VERSION ""

NS_ :

BS_:

BU_: RLPSU DPSU APSU PSB SHVU_RR vHS_B2 FCS EMCU SLB RCM CGW_CCU vDummy_HS_B ATS RLHV PFSU SGU ALBCU DSAU SWRC SHVU_FR RCS RRPSU BLTN_CAM SCM DLBCU OHCL RWPC RRHV WPC HOD ASAU

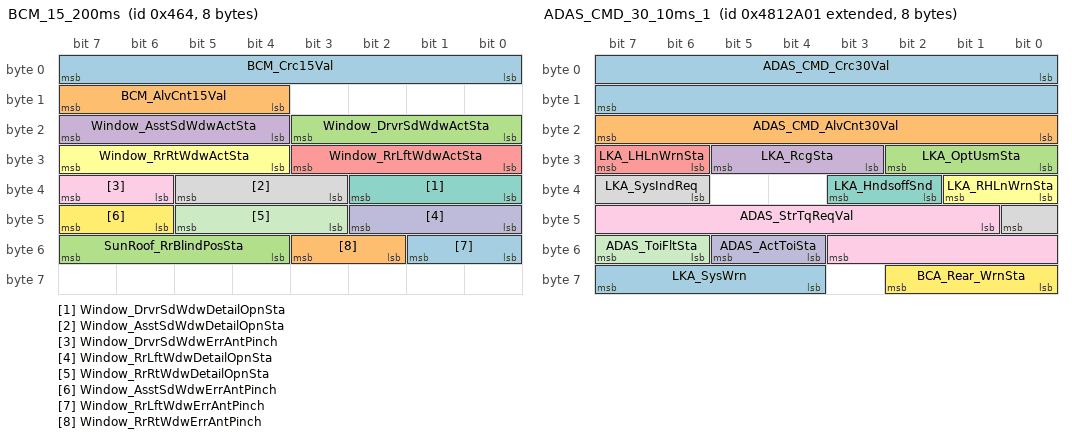
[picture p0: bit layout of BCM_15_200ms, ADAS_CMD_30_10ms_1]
BO_ 1124 BCM_15_200ms: 8 CGW_CCU
 SG_ BCM_Crc15Val : 0|8@1+ (1,0) [0|0] ""  Vector__XXX
 SG_ BCM_AlvCnt15Val : 12|4@1+ (1,0) [0|0] ""  Vector__XXX
 SG_ Window_DrvrSdWdwActSta : 16|4@1+ (1,0) [0|0] ""  Vector__XXX
 SG_ Window_AsstSdWdwActSta : 20|4@1+ (1,0) [0|0] ""  Vector__XXX
 SG_ Window_RrLftWdwActSta : 24|4@1+ (1,0) [0|0] ""  Vector__XXX
 SG_ Window_RrRtWdwActSta : 28|4@1+ (1,0) [0|0] ""  Vector__XXX
 SG_ Window_DrvrSdWdwDetailOpnSta : 32|3@1+ (1,0) [0|0] ""  Vector__XXX
 SG_ Window_AsstSdWdwDetailOpnSta : 35|3@1+ (1,0) [0|0] ""  Vector__XXX
 SG_ Window_DrvrSdWdwErrAntPinch : 38|2@1+ (1,0) [0|0] ""  Vector__XXX
 SG_ Window_RrLftWdwDetailOpnSta : 40|3@1+ (1,0) [0|0] ""  Vector__XXX
 SG_ Window_RrRtWdwDetailOpnSta : 43|3@1+ (1,0) [0|0] ""  Vector__XXX
 SG_ Window_AsstSdWdwErrAntPinch : 46|2@1+ (1,0) [0|0] ""  Vector__XXX
 SG_ Window_RrLftWdwErrAntPinch : 48|2@1+ (1,0) [0|0] ""  Vector__XXX
 SG_ Window_RrRtWdwErrAntPinch : 50|2@1+ (1,0) [0|0] ""  Vector__XXX
 SG_ SunRoof_RrBlindPosSta : 52|4@1+ (1,0) [0|0] ""  ATS

BO_ 2223057409 ADAS_CMD_30_10ms_1: 8 CGW_CCU
 SG_ ADAS_CMD_Crc30Val : 0|16@1+ (1,0) [0|0] ""  Vector__XXX
 SG_ ADAS_CMD_AlvCnt30Val : 16|8@1+ (1,0) [0|0] ""  Vector__XXX
 SG_ LKA_OptUsmSta : 24|3@1+ (1,0) [0|0] ""  Vector__XXX
 SG_ LKA_RcgSta : 27|3@1+ (1,0) [0|0] ""  Vector__XXX
 SG_ LKA_LHLnWrnSta : 30|2@1+ (1,0) [0|0] ""  Vector__XXX
 SG_ LKA_RHLnWrnSta : 32|2@1+ (1,0) [0|0] ""  Vector__XXX
 SG_ LKA_HndsoffSnd : 34|2@1+ (1,0) [0|0] ""  Vector__XXX
 SG_ LKA_SysIndReq : 38|3@1+ (1,0) [0|0] ""  Vector__XXX
 SG_ ADAS_StrTqReqVal : 41|11@1+ (0.0078125,-8) [0|0] "Nm"  Vector__XXX
 SG_ ADAS_ActToiSta : 52|2@1+ (1,0) [0|0] ""  Vector__XXX
 SG_ ADAS_ToiFltSta : 54|2@1+ (1,0) [0|0] ""  Vector__XXX
 SG_ BCA_Rear_WrnSta : 56|3@1+ (1,0) [0|0] ""  Vector__XXX
 SG_ LKA_SysWrn : 60|4@1+ (1,0) [0|0] ""  Vector__XXX

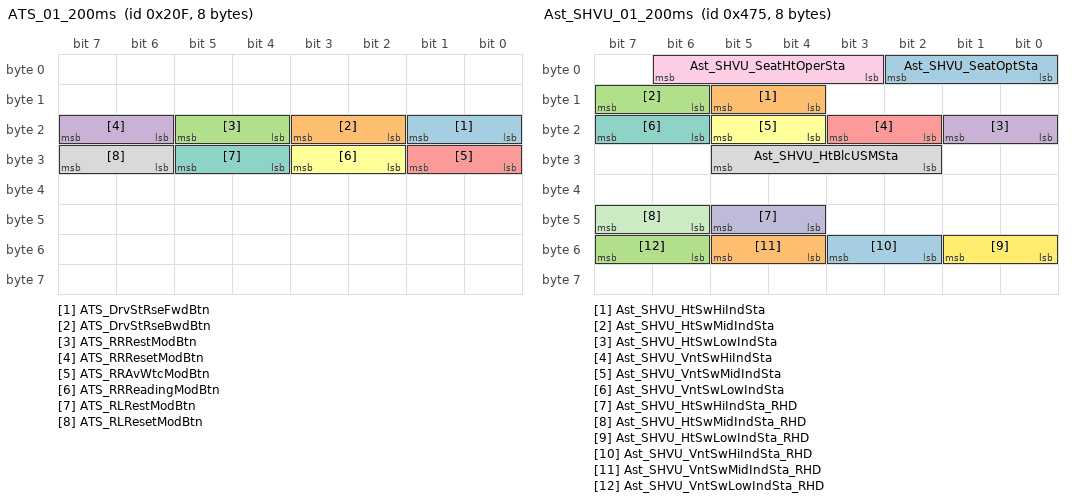
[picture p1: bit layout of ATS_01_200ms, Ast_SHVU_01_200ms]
BO_ 527 ATS_01_200ms: 8 ATS
 SG_ ATS_DrvStRseFwdBtn : 16|2@1+ (1,0) [0|0] ""  Vector__XXX
 SG_ ATS_DrvStRseBwdBtn : 18|2@1+ (1,0) [0|0] ""  Vector__XXX
 SG_ ATS_RRRestModBtn : 20|2@1+ (1,0) [0|0] ""  Vector__XXX
 SG_ ATS_RRResetModBtn : 22|2@1+ (1,0) [0|0] ""  Vector__XXX
 SG_ ATS_RRAvWtcModBtn : 24|2@1+ (1,0) [0|0] ""  Vector__XXX
 SG_ ATS_RRReadingModBtn : 26|2@1+ (1,0) [0|0] ""  Vector__XXX
 SG_ ATS_RLRestModBtn : 28|2@1+ (1,0) [0|0] ""  Vector__XXX
 SG_ ATS_RLResetModBtn : 30|2@1+ (1,0) [0|0] ""  Vector__XXX

BO_ 1616 MKBD_HU_E_01: 8 CGW_CCU
 SG_ MKBD_IllumiState : 48|2@1+ (1,0) [0|0] ""  Vector__XXX
 SG_ MKBD_SeatKeySet : 50|2@1+ (1,0) [0|0] ""  APSU,SHVU_FR,DPSU

BO_ 1141 Ast_SHVU_01_200ms: 8 APSU
 SG_ Ast_SHVU_SeatOptSta : 0|3@1+ (1,0) [0|0] ""  FCS,CGW_CCU
 SG_ Ast_SHVU_HtSwHiIndSta : 12|2@1+ (1,0) [0|0] ""  FCS,CGW_CCU
 SG_ Ast_SHVU_HtSwMidIndSta : 14|2@1+ (1,0) [0|0] ""  FCS,CGW_CCU
 SG_ Ast_SHVU_HtSwLowIndSta : 16|2@1+ (1,0) [0|0] ""  FCS,CGW_CCU
 SG_ Ast_SHVU_VntSwHiIndSta : 18|2@1+ (1,0) [0|0] ""  FCS,CGW_CCU
 SG_ Ast_SHVU_VntSwMidIndSta : 20|2@1+ (1,0) [0|0] ""  FCS,CGW_CCU
 SG_ Ast_SHVU_VntSwLowIndSta : 22|2@1+ (1,0) [0|0] ""  FCS,CGW_CCU
 SG_ Ast_SHVU_HtBlcUSMSta : 26|4@1+ (1,0) [0|0] ""  CGW_CCU
 SG_ Ast_SHVU_SeatHtOperSta : 3|4@1+ (1,0) [0|0] ""  CGW_CCU
 SG_ Ast_SHVU_HtSwHiIndSta_RHD : 44|2@1+ (1,0) [0|0] ""  FCS,CGW_CCU
 SG_ Ast_SHVU_HtSwMidIndSta_RHD : 46|2@1+ (1,0) [0|0] ""  FCS,CGW_CCU
 SG_ Ast_SHVU_HtSwLowIndSta_RHD : 48|2@1+ (1,0) [0|0] ""  FCS,CGW_CCU
 SG_ Ast_SHVU_VntSwHiIndSta_RHD : 50|2@1+ (1,0) [0|0] ""  FCS,CGW_CCU
 SG_ Ast_SHVU_VntSwMidIndSta_RHD : 52|2@1+ (1,0) [0|0] ""  FCS,CGW_CCU
 SG_ Ast_SHVU_VntSwLowIndSta_RHD : 54|2@1+ (1,0) [0|0] ""  FCS,CGW_CCU

BO_ 543 ATS_02_200ms: 8 ATS
 SG_ ATS_AstStSldFwdBtn : 16|2@1+ (1,0) [0|0] ""  Vector__XXX
 SG_ ATS_AstStSldBwdBtn : 18|2@1+ (1,0) [0|0] ""  Vector__XXX
 SG_ ATS_AstStRclFwdBtn : 20|2@1+ (1,0) [0|0] ""  Vector__XXX
 SG_ ATS_AstStRclBwdBtn : 22|2@1+ (1,0) [0|0] ""  Vector__XXX
 SG_ ATS_AstStHgtUpBtn : 28|2@1+ (1,0) [0|0] ""  Vector__XXX
 SG_ ATS_AstStHgtDnBtn : 30|2@1+ (1,0) [0|0] ""  Vector__XXX
 SG_ ATS_AstStHRestUpBtn : 40|2@1+ (1,0) [0|0] ""  Vector__XXX
 SG_ ATS_AstStHRestDnBtn : 42|2@1+ (1,0) [0|0] ""  Vector__XXX
 SG_ ATS_AstStHRestFwdBtn : 44|2@1+ (1,0) [0|0] ""  Vector__XXX
 SG_ ATS_AstStHRestBwdBtn : 46|2@1+ (1,0) [0|0] ""  Vector__XXX
 SG_ ATS_AstStHRestFldBtn : 48|2@1+ (1,0) [0|0] ""  Vector__XXX
 SG_ ATS_AstStHRestUnFldBtn : 50|2@1+ (1,0) [0|0] ""  Vector__XXX
 SG_ ATS_AstStRseFwdBtn : 52|2@1+ (1,0) [0|0] ""  Vector__XXX
 SG_ ATS_AstStRseBwdBtn : 54|2@1+ (1,0) [0|0] ""  Vector__XXX
 SG_ ATS_AstStFRestFldBtn : 56|2@1+ (1,0) [0|0] ""  Vector__XXX
 SG_ ATS_AstStFRestUnFldBtn : 58|2@1+ (1,0) [0|0] ""  Vector__XXX
 SG_ ATS_AstTltUpBtn : 60|2@1+ (1,0) [0|0] ""  Vector__XXX
 SG_ ATS_AstTltDnBtn : 62|2@1+ (1,0) [0|0] ""  Vector__XXX

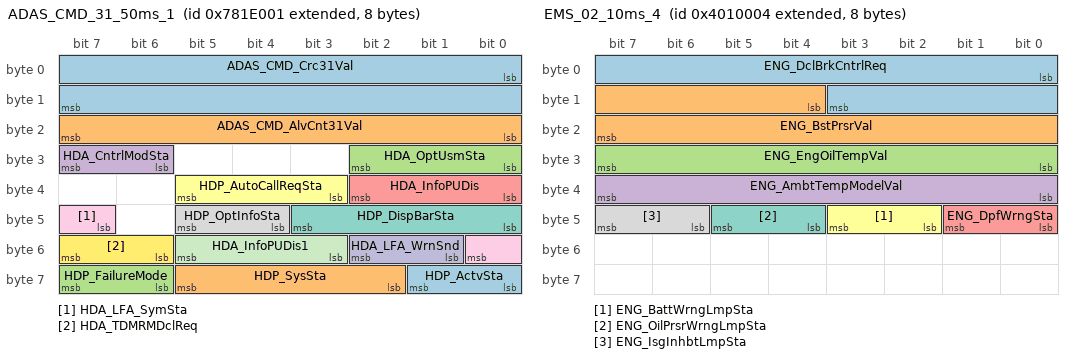
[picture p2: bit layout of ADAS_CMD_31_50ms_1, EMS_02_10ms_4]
BO_ 2273435649 ADAS_CMD_31_50ms_1: 8 CGW_CCU
 SG_ ADAS_CMD_Crc31Val : 0|16@1+ (1,0) [0|0] ""  Vector__XXX
 SG_ ADAS_CMD_AlvCnt31Val : 16|8@1+ (1,0) [0|0] ""  Vector__XXX
 SG_ HDA_OptUsmSta : 24|3@1+ (1,0) [0|0] ""  Vector__XXX
 SG_ HDA_CntrlModSta : 30|2@1+ (1,0) [0|0] ""  Vector__XXX
 SG_ HDA_InfoPUDis : 32|3@1+ (1,0) [0|0] ""  Vector__XXX
 SG_ HDP_AutoCallReqSta : 35|3@1+ (1,0) [0|0] ""  Vector__XXX
 SG_ HDP_DispBarSta : 40|4@1+ (1,0) [0|0] ""  Vector__XXX
 SG_ HDP_OptInfoSta : 44|2@1+ (1,0) [0|0] ""  Vector__XXX
 SG_ HDA_LFA_SymSta : 47|2@1+ (1,0) [0|0] ""  Vector__XXX
 SG_ HDA_LFA_WrnSnd : 49|2@1+ (1,0) [0|0] ""  Vector__XXX
 SG_ HDA_InfoPUDis1 : 51|3@1+ (1,0) [0|0] ""  Vector__XXX
 SG_ HDA_TDMRMDclReq : 54|2@1+ (1,0) [0|0] ""  Vector__XXX
 SG_ HDP_ActvSta : 56|2@1+ (1,0) [0|0] ""  Vector__XXX
 SG_ HDP_SysSta : 58|4@1+ (1,0) [0|0] ""  HOD
 SG_ HDP_FailureMode : 62|2@1+ (1,0) [0|0] ""  Vector__XXX

BO_ 2214658052 EMS_02_10ms_4: 8 CGW_CCU
 SG_ ENG_DclBrkCntrlReq : 0|12@1+ (0.001,-4.094) [0|0] "m/s^2"  Vector__XXX
 SG_ ENG_BstPrsrVal : 12|12@1+ (1.322,0) [0|0] "hPa"  Vector__XXX
 SG_ ENG_EngOilTempVal : 24|8@1+ (0.75,-40) [0|0] "¡É"  Vector__XXX
 SG_ ENG_AmbtTempModelVal : 32|8@1+ (0.5,-41) [0|0] "¡É"  Vector__XXX
 SG_ ENG_DpfWrngSta : 40|2@1+ (1,0) [0|0] ""  Vector__XXX
 SG_ ENG_BattWrngLmpSta : 42|2@1+ (1,0) [0|0] ""  Vector__XXX
 SG_ ENG_OilPrsrWrngLmpSta : 44|2@1+ (1,0) [0|0] ""  Vector__XXX
 SG_ ENG_IsgInhbtLmpSta : 46|2@1+ (1,0) [0|0] ""  FCS

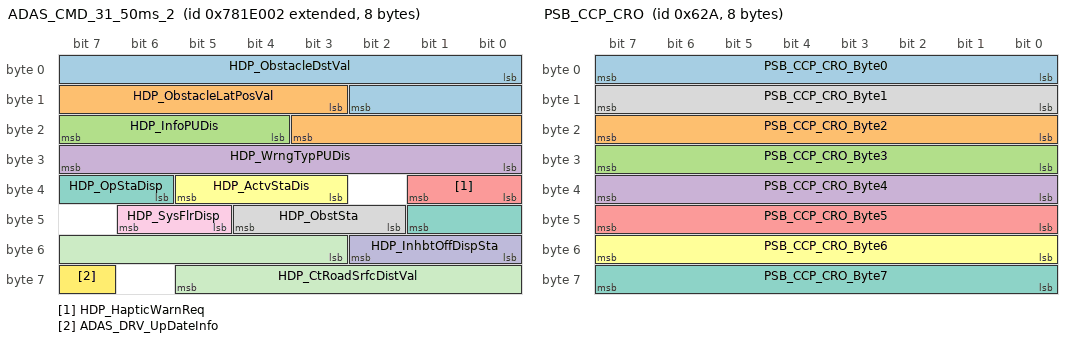
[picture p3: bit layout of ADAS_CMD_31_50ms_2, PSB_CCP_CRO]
BO_ 2273435650 ADAS_CMD_31_50ms_2: 8 CGW_CCU
 SG_ HDP_ObstacleDstVal : 0|11@1+ (0.1,0) [0|0] "m"  Vector__XXX
 SG_ HDP_ObstacleLatPosVal : 11|9@1+ (0.1,-20) [0|0] "m"  Vector__XXX
 SG_ HDP_InfoPUDis : 20|4@1+ (1,0) [0|0] ""  Vector__XXX
 SG_ HDP_WrngTypPUDis : 24|8@1+ (1,0) [0|0] ""  Vector__XXX
 SG_ HDP_HapticWarnReq : 32|2@1+ (1,0) [0|0] ""  PSB
 SG_ HDP_ActvStaDis : 35|3@1+ (1,0) [0|0] ""  Vector__XXX
 SG_ HDP_OpStaDisp : 38|4@1+ (1,0) [0|0] ""  Vector__XXX
 SG_ HDP_ObstSta : 42|3@1+ (1,0) [0|0] ""  Vector__XXX
 SG_ HDP_SysFlrDisp : 45|2@1+ (1,0) [0|0] ""  Vector__XXX
 SG_ HDP_InhbtOffDispSta : 48|3@1+ (1,0) [0|0] ""  Vector__XXX
 SG_ HDP_CtRoadSrfcDistVal : 51|11@1+ (1,0) [0|0] ""  Vector__XXX
 SG_ ADAS_DRV_UpDateInfo : 63|1@1+ (1,0) [0|0] ""  Vector__XXX

BO_ 1578 PSB_CCP_CRO: 8 CGW_CCU
 SG_ PSB_CCP_CRO_Byte0 : 0|8@1+ (1,0) [0|0] ""  PSB
 SG_ PSB_CCP_CRO_Byte2 : 16|8@1+ (1,0) [0|0] ""  PSB
 SG_ PSB_CCP_CRO_Byte3 : 24|8@1+ (1,0) [0|0] ""  PSB
 SG_ PSB_CCP_CRO_Byte4 : 32|8@1+ (1,0) [0|0] ""  PSB
 SG_ PSB_CCP_CRO_Byte5 : 40|8@1+ (1,0) [0|0] ""  PSB
 SG_ PSB_CCP_CRO_Byte6 : 48|8@1+ (1,0) [0|0] ""  PSB
 SG_ PSB_CCP_CRO_Byte7 : 56|8@1+ (1,0) [0|0] ""  PSB
 SG_ PSB_CCP_CRO_Byte1 : 8|8@1+ (1,0) [0|0] ""  PSB

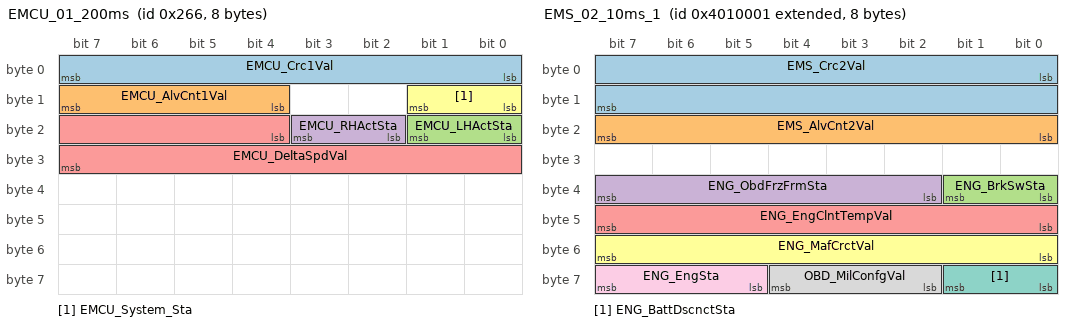
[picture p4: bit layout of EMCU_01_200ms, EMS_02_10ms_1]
BO_ 614 EMCU_01_200ms: 8 EMCU
 SG_ EMCU_Crc1Val : 0|8@1+ (1,0) [0|0] ""  Vector__XXX
 SG_ EMCU_AlvCnt1Val : 12|4@1+ (1,0) [0|0] ""  Vector__XXX
 SG_ EMCU_LHActSta : 16|2@1+ (1,0) [0|0] ""  Vector__XXX
 SG_ EMCU_RHActSta : 18|2@1+ (1,0) [0|0] ""  Vector__XXX
 SG_ EMCU_DeltaSpdVal : 20|12@1+ (0.01,0) [0|0] ""  Vector__XXX
 SG_ EMCU_System_Sta : 8|2@1+ (1,0) [0|0] ""  Vector__XXX

BO_ 2214658049 EMS_02_10ms_1: 8 CGW_CCU
 SG_ EMS_Crc2Val : 0|16@1+ (1,0) [0|0] ""  Vector__XXX
 SG_ EMS_AlvCnt2Val : 16|8@1+ (1,0) [0|0] ""  Vector__XXX
 SG_ ENG_BrkSwSta : 32|2@1+ (1,0) [0|0] ""  BLTN_CAM
 SG_ ENG_ObdFrzFrmSta : 34|6@1+ (1,0) [0|0] ""  Vector__XXX
 SG_ ENG_EngClntTempVal : 40|8@1+ (0.75,-48) [0|0] "¡É"  Vector__XXX
 SG_ ENG_MafCrctVal : 48|8@1+ (0.00781,0) [0|0] ""  Vector__XXX
 SG_ ENG_BattDscnctSta : 56|2@1+ (1,0) [0|0] ""  Vector__XXX
 SG_ OBD_MilConfgVal : 58|3@1+ (1,0) [0|0] ""  Vector__XXX
 SG_ ENG_EngSta : 61|3@1+ (1,0) [0|0] ""  SCM,WPC,RWPC,SWRC,APSU,SHVU_FR,DPSU,PFSU,RRPSU,RLPSU,HOD,BLTN_CAM,EMCU

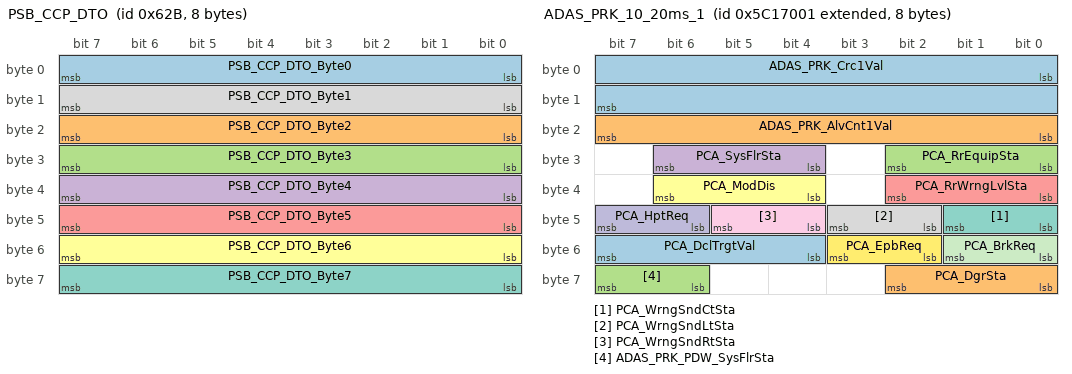
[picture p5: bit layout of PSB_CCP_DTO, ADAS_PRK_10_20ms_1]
BO_ 1579 PSB_CCP_DTO: 8 PSB
 SG_ PSB_CCP_DTO_Byte0 : 0|8@1+ (1,0) [0|0] ""  CGW_CCU
 SG_ PSB_CCP_DTO_Byte2 : 16|8@1+ (1,0) [0|0] ""  CGW_CCU
 SG_ PSB_CCP_DTO_Byte3 : 24|8@1+ (1,0) [0|0] ""  CGW_CCU
 SG_ PSB_CCP_DTO_Byte4 : 32|8@1+ (1,0) [0|0] ""  CGW_CCU
 SG_ PSB_CCP_DTO_Byte5 : 40|8@1+ (1,0) [0|0] ""  CGW_CCU
 SG_ PSB_CCP_DTO_Byte6 : 48|8@1+ (1,0) [0|0] ""  CGW_CCU
 SG_ PSB_CCP_DTO_Byte7 : 56|8@1+ (1,0) [0|0] ""  CGW_CCU
 SG_ PSB_CCP_DTO_Byte1 : 8|8@1+ (1,0) [0|0] ""  CGW_CCU

BO_ 2244046850 ADAS_PRK_10_20ms_2: 8 CGW_CCU
 SG_ ADAS_PRK_PDW_SwIndOnReq : 0|2@1+ (1,0) [0|0] ""  FCS
 SG_ PCA_RrEquipChkSta : 10|2@1+ (1,0) [0|0] ""  Vector__XXX
 SG_ PCA_FrWrngLvlSta : 12|3@1+ (1,0) [0|0] ""  Vector__XXX
 SG_ PCA_LtWrngLvlSta : 16|3@1+ (1,0) [0|0] ""  Vector__XXX
 SG_ ADAS_PRK_PDW_OptTyp : 2|3@1+ (1,0) [0|0] ""  Vector__XXX
 SG_ PCA_RtWrngLvlSta : 20|3@1+ (1,0) [0|0] ""  Vector__XXX
 SG_ PCA_RrFlrDis : 32|2@1+ (1,0) [0|0] ""  Vector__XXX
 SG_ PCA_FrFlrDis : 34|2@1+ (1,0) [0|0] ""  Vector__XXX
 SG_ PCA_LtFlrDis : 36|2@1+ (1,0) [0|0] ""  Vector__XXX
 SG_ PCA_RtFlrDis : 38|2@1+ (1,0) [0|0] ""  Vector__XXX
 SG_ PCA_FrBndryLn : 40|2@1+ (1,0) [0|0] ""  Vector__XXX
 SG_ PCA_RrBndryLn : 42|2@1+ (1,0) [0|0] ""  Vector__XXX
 SG_ PCA_LtBndryLn : 44|2@1+ (1,0) [0|0] ""  Vector__XXX
 SG_ PCA_RtBndryLn : 46|2@1+ (1,0) [0|0] ""  Vector__XXX
 SG_ PCA_WrngPhrs : 48|3@1+ (1,0) [0|0] ""  Vector__XXX
 SG_ ADAS_PRK_PDW_AutoOn_USM : 5|2@1+ (1,0) [0|0] ""  Vector__XXX
 SG_ PCA_FrSdEquipChkSta : 8|2@1+ (1,0) [0|0] ""  Vector__XXX

BO_ 2244046849 ADAS_PRK_10_20ms_1: 8 CGW_CCU
 SG_ ADAS_PRK_Crc1Val : 0|16@1+ (1,0) [0|0] ""  Vector__XXX
 SG_ ADAS_PRK_AlvCnt1Val : 16|8@1+ (1,0) [0|0] ""  Vector__XXX
 SG_ PCA_RrEquipSta : 24|3@1+ (1,0) [0|0] ""  Vector__XXX
 SG_ PCA_SysFlrSta : 28|3@1+ (1,0) [0|0] ""  Vector__XXX
 SG_ PCA_RrWrngLvlSta : 32|3@1+ (1,0) [0|0] ""  Vector__XXX
 SG_ PCA_ModDis : 36|3@1+ (1,0) [0|0] ""  Vector__XXX
 SG_ PCA_WrngSndCtSta : 40|2@1+ (1,0) [0|0] ""  Vector__XXX
 SG_ PCA_WrngSndLtSta : 42|2@1+ (1,0) [0|0] ""  Vector__XXX
 SG_ PCA_WrngSndRtSta : 44|2@1+ (1,0) [0|0] ""  Vector__XXX
 SG_ PCA_HptReq : 46|2@1+ (1,0) [0|0] ""  Vector__XXX
 SG_ PCA_BrkReq : 48|2@1+ (1,0) [0|0] ""  Vector__XXX
 SG_ PCA_EpbReq : 50|2@1+ (1,0) [0|0] ""  Vector__XXX
 SG_ PCA_DclTrgtVal : 52|4@1+ (0.04,0) [0|0] "g"  Vector__XXX
 SG_ PCA_DgrSta : 56|3@1+ (1,0) [0|0] ""  Vector__XXX
 SG_ ADAS_PRK_PDW_SysFlrSta : 62|2@1+ (1,0) [0|0] ""  Vector__XXX

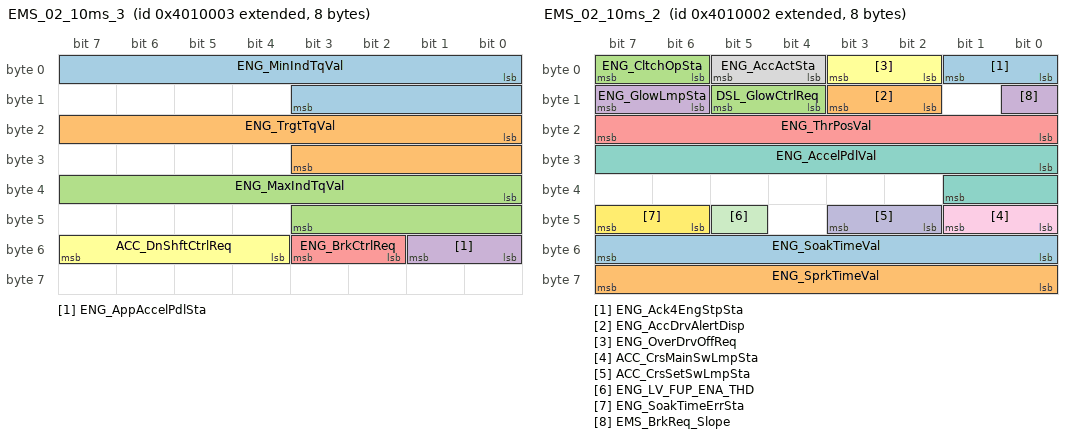
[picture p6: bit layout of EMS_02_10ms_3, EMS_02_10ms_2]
BO_ 2214658051 EMS_02_10ms_3: 8 CGW_CCU
 SG_ ENG_MinIndTqVal : 0|12@1- (1,0) [0|0] "Nm"  Vector__XXX
 SG_ ENG_TrgtTqVal : 16|12@1- (1,0) [0|0] "Nm"  Vector__XXX
 SG_ ENG_MaxIndTqVal : 32|12@1- (1,0) [0|0] "Nm"  Vector__XXX
 SG_ ENG_AppAccelPdlSta : 48|2@1+ (1,0) [0|0] ""  Vector__XXX
 SG_ ENG_BrkCtrlReq : 50|2@1+ (1,0) [0|0] ""  Vector__XXX
 SG_ ACC_DnShftCtrlReq : 52|4@1+ (1,0) [0|0] ""  Vector__XXX

BO_ 2214658050 EMS_02_10ms_2: 8 CGW_CCU
 SG_ ENG_Ack4EngStpSta : 0|2@1+ (1,0) [0|0] ""  Vector__XXX
 SG_ ENG_AccDrvAlertDisp : 10|2@1+ (1,0) [0|0] ""  Vector__XXX
 SG_ DSL_GlowCtrlReq : 12|2@1+ (1,0) [0|0] ""  Vector__XXX
 SG_ ENG_GlowLmpSta : 14|2@1+ (1,0) [0|0] ""  Vector__XXX
 SG_ ENG_ThrPosVal : 16|8@1+ (0.4694836,-15.0234742) [0|0] "%"  Vector__XXX
 SG_ ENG_OverDrvOffReq : 2|2@1+ (1,0) [0|0] ""  Vector__XXX
 SG_ ENG_AccelPdlVal : 24|10@1+ (0.09784,0) [0|0] "%"  BLTN_CAM,EMCU
 SG_ ENG_AccActSta : 4|2@1+ (1,0) [0|0] ""  Vector__XXX
 SG_ ACC_CrsMainSwLmpSta : 40|2@1+ (1,0) [0|0] ""  Vector__XXX
 SG_ ACC_CrsSetSwLmpSta : 42|2@1+ (1,0) [0|0] ""  Vector__XXX
 SG_ ENG_LV_FUP_ENA_THD : 45|1@1+ (1,0) [0|0] ""  Vector__XXX
 SG_ ENG_SoakTimeErrSta : 46|2@1+ (1,0) [0|0] ""  Vector__XXX
 SG_ ENG_SoakTimeVal : 48|8@1+ (1,0) [0|0] "Min"  Vector__XXX
 SG_ ENG_SprkTimeVal : 56|8@1+ (0.375,-35.625) [0|0] "¢ª"  Vector__XXX
 SG_ ENG_CltchOpSta : 6|2@1+ (1,0) [0|0] ""  Vector__XXX
 SG_ EMS_BrkReq_Slope : 8|1@1+ (1,0) [0|0] ""  Vector__XXX

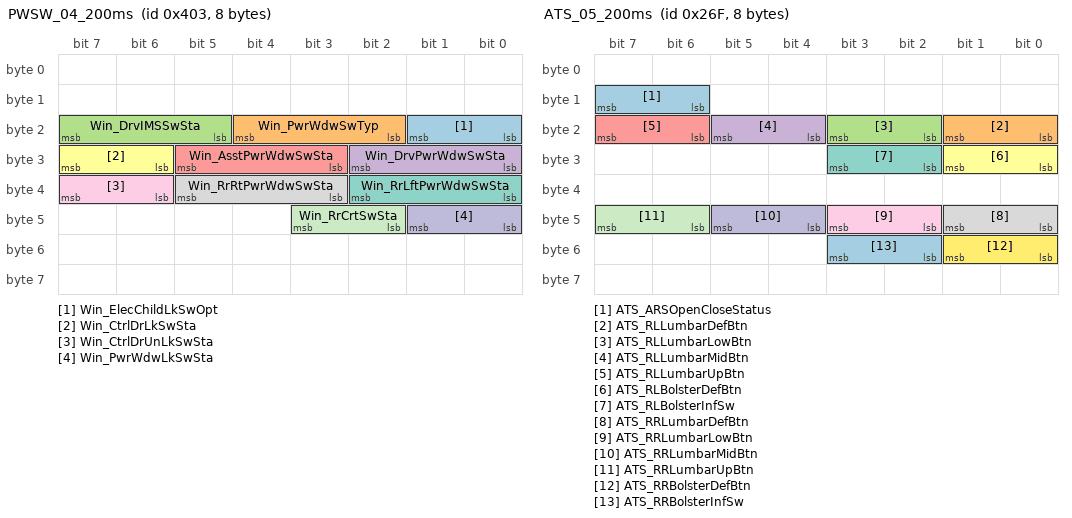
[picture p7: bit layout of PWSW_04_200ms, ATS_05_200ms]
BO_ 1027 PWSW_04_200ms: 8 CGW_CCU
 SG_ Win_ElecChildLkSwOpt : 16|2@1+ (1,0) [0|0] ""  Vector__XXX
 SG_ Win_PwrWdwSwTyp : 18|3@1+ (1,0) [0|0] ""  Vector__XXX
 SG_ Win_DrvIMSSwSta : 21|3@1+ (1,0) [0|0] ""  DPSU
 SG_ Win_DrvPwrWdwSwSta : 24|3@1+ (1,0) [0|0] ""  Vector__XXX
 SG_ Win_AsstPwrWdwSwSta : 27|3@1+ (1,0) [0|0] ""  Vector__XXX
 SG_ Win_CtrlDrLkSwSta : 30|2@1+ (1,0) [0|0] ""  Vector__XXX
 SG_ Win_RrLftPwrWdwSwSta : 32|3@1+ (1,0) [0|0] ""  Vector__XXX
 SG_ Win_RrRtPwrWdwSwSta : 35|3@1+ (1,0) [0|0] ""  Vector__XXX
 SG_ Win_CtrlDrUnLkSwSta : 38|2@1+ (1,0) [0|0] ""  Vector__XXX
 SG_ Win_PwrWdwLkSwSta : 40|2@1+ (1,0) [0|0] ""  Vector__XXX
 SG_ Win_RrCrtSwSta : 42|2@1+ (1,0) [0|0] ""  Vector__XXX

BO_ 623 ATS_05_200ms: 8 ATS
 SG_ ATS_ARSOpenCloseStatus : 14|2@1+ (1,0) [0|0] ""  Vector__XXX
 SG_ ATS_RLLumbarDefBtn : 16|2@1+ (1,0) [0|0] ""  Vector__XXX
 SG_ ATS_RLLumbarLowBtn : 18|2@1+ (1,0) [0|0] ""  Vector__XXX
 SG_ ATS_RLLumbarMidBtn : 20|2@1+ (1,0) [0|0] ""  Vector__XXX
 SG_ ATS_RLLumbarUpBtn : 22|2@1+ (1,0) [0|0] ""  Vector__XXX
 SG_ ATS_RLBolsterDefBtn : 24|2@1+ (1,0) [0|0] ""  Vector__XXX
 SG_ ATS_RLBolsterInfSw : 26|2@1+ (1,0) [0|0] ""  Vector__XXX
 SG_ ATS_RRLumbarDefBtn : 40|2@1+ (1,0) [0|0] ""  Vector__XXX
 SG_ ATS_RRLumbarLowBtn : 42|2@1+ (1,0) [0|0] ""  Vector__XXX
 SG_ ATS_RRLumbarMidBtn : 44|2@1+ (1,0) [0|0] ""  Vector__XXX
 SG_ ATS_RRLumbarUpBtn : 46|2@1+ (1,0) [0|0] ""  Vector__XXX
 SG_ ATS_RRBolsterDefBtn : 48|2@1+ (1,0) [0|0] ""  Vector__XXX
 SG_ ATS_RRBolsterInfSw : 50|2@1+ (1,0) [0|0] ""  Vector__XXX

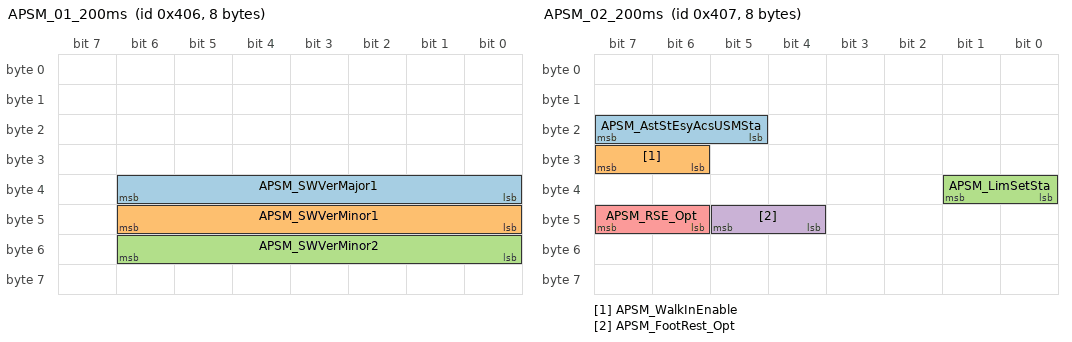
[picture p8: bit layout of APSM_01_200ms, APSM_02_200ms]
BO_ 1030 APSM_01_200ms: 8 APSU
 SG_ APSM_SWVerMajor1 : 32|7@1+ (1,0) [0|0] ""  CGW_CCU
 SG_ APSM_SWVerMinor1 : 40|7@1+ (1,0) [0|0] ""  CGW_CCU
 SG_ APSM_SWVerMinor2 : 48|7@1+ (1,0) [0|0] ""  CGW_CCU

BO_ 1031 APSM_02_200ms: 8 APSU
 SG_ APSM_AstStEsyAcsUSMSta : 21|3@1+ (1,0) [0|0] ""  CGW_CCU
 SG_ APSM_WalkInEnable : 30|2@1+ (1,0) [0|0] ""  Vector__XXX
 SG_ APSM_LimSetSta : 32|2@1+ (1,0) [0|0] ""  Vector__XXX
 SG_ APSM_FootRest_Opt : 44|2@1+ (1,0) [0|0] ""  Vector__XXX
 SG_ APSM_RSE_Opt : 46|2@1+ (1,0) [0|0] ""  Vector__XXX

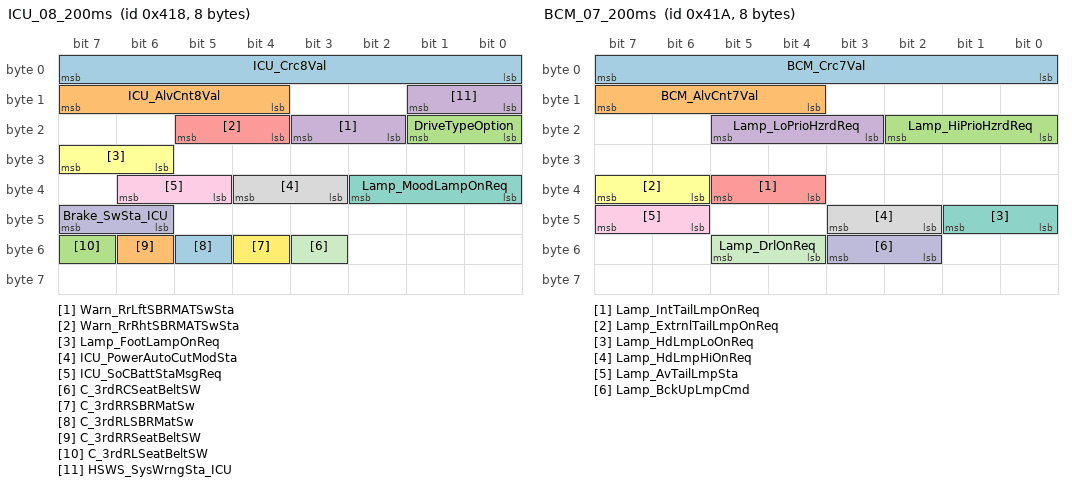
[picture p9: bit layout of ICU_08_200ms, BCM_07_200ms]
BO_ 1048 ICU_08_200ms: 8 CGW_CCU
 SG_ ICU_Crc8Val : 0|8@1+ (1,0) [0|0] ""  Vector__XXX
 SG_ ICU_AlvCnt8Val : 12|4@1+ (1,0) [0|0] ""  Vector__XXX
 SG_ DriveTypeOption : 16|2@1+ (1,0) [0|0] ""  APSU,SHVU_FR,SHVU_RR,DPSU,DLBCU,ATS
 SG_ Warn_RrLftSBRMATSwSta : 18|2@1+ (1,0) [0|0] ""  Vector__XXX
 SG_ Warn_RrRhtSBRMATSwSta : 20|2@1+ (1,0) [0|0] ""  Vector__XXX
 SG_ Lamp_FootLampOnReq : 30|2@1+ (1,0) [0|0] ""  Vector__XXX
 SG_ Lamp_MoodLampOnReq : 32|3@1+ (1,0) [0|0] ""  Vector__XXX
 SG_ ICU_PowerAutoCutModSta : 35|2@1+ (1,0) [0|0] ""  APSU,RLHV,RRHV,DPSU,RRPSU,RLPSU,BLTN_CAM
 SG_ ICU_SoCBattStaMsgReq : 37|2@1+ (1,0) [0|0] ""  Vector__XXX
 SG_ Brake_SwSta_ICU : 46|2@1+ (1,0) [0|0] ""  Vector__XXX
 SG_ C_3rdRCSeatBeltSW : 51|1@1+ (1,0) [0|0] ""  RRPSU,RLPSU
 SG_ C_3rdRRSBRMatSw : 52|1@1+ (1,0) [0|0] ""  RRPSU,RLPSU
 SG_ C_3rdRLSBRMatSw : 53|1@1+ (1,0) [0|0] ""  RLPSU
 SG_ C_3rdRRSeatBeltSW : 54|1@1+ (1,0) [0|0] ""  RRPSU,RLPSU
 SG_ C_3rdRLSeatBeltSW : 55|1@1+ (1,0) [0|0] ""  RRPSU,RLPSU
 SG_ HSWS_SysWrngSta_ICU : 8|2@1+ (1,0) [0|0] ""  Vector__XXX

BO_ 1050 BCM_07_200ms: 8 CGW_CCU
 SG_ BCM_Crc7Val : 0|8@1+ (1,0) [0|0] ""  Vector__XXX
 SG_ BCM_AlvCnt7Val : 12|4@1+ (1,0) [0|0] ""  Vector__XXX
 SG_ Lamp_HiPrioHzrdReq : 16|3@1+ (1,0) [0|0] ""  Vector__XXX
 SG_ Lamp_LoPrioHzrdReq : 19|3@1+ (1,0) [0|0] ""  Vector__XXX
 SG_ Lamp_IntTailLmpOnReq : 36|2@1+ (1,0) [0|0] ""  FCS,WPC,RWPC,APSU,RLHV,RRHV,SHVU_FR,SHVU_RR,DPSU
 SG_ Lamp_ExtrnlTailLmpOnReq : 38|2@1+ (1,0) [0|0] ""  BLTN_CAM
 SG_ Lamp_HdLmpLoOnReq : 40|2@1+ (1,0) [0|0] ""  Vector__XXX
 SG_ Lamp_HdLmpHiOnReq : 42|2@1+ (1,0) [0|0] ""  Vector__XXX
 SG_ Lamp_AvTailLmpSta : 46|2@1+ (1,0) [0|0] ""  SWRC,APSU,ATS
 SG_ Lamp_BckUpLmpCmd : 50|2@1+ (1,0) [0|0] ""  Vector__XXX
 SG_ Lamp_DrlOnReq : 52|2@1+ (1,0) [0|0] ""  Vector__XXX

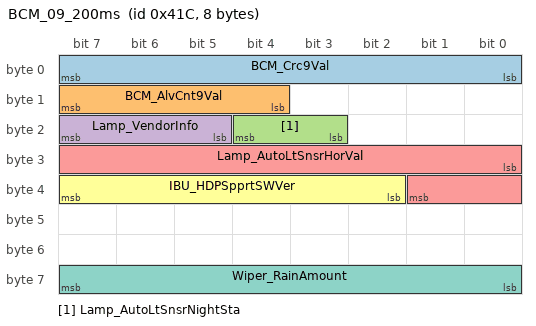
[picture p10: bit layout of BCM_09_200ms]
BO_ 1052 BCM_09_200ms: 8 CGW_CCU
 SG_ BCM_Crc9Val : 0|8@1+ (1,0) [0|0] ""  Vector__XXX
 SG_ BCM_AlvCnt9Val : 12|4@1+ (1,0) [0|0] ""  Vector__XXX
 SG_ Lamp_AutoLtSnsrNightSta : 19|2@1+ (1,0) [0|0] ""  SWRC,APSU,ATS
 SG_ Lamp_VendorInfo : 21|3@1+ (1,0) [0|0] ""  Vector__XXX
 SG_ Lamp_AutoLtSnsrHorVal : 24|10@1+ (1,0) [0|0] ""  ATS
 SG_ IBU_HDPSpprtSWVer : 34|6@1+ (1,0) [0|0] ""  Vector__XXX
 SG_ Wiper_RainAmount : 56|8@1+ (0.5,0) [0|0] ""  Vector__XXX

BO_TX_BU_ 1141 : APSU,SHVU_FR;
CM_ BO_ 2223057409 "[P] Periodic";
CM_ SG_ 2223057409 ADAS_CMD_Crc30Val "ADAS_CMD_CyclicRedundancyCheck30Value";
CM_ SG_ 2223057409 ADAS_CMD_AlvCnt30Val "ADAS_CMD_AliveCounter30Value";
CM_ SG_ 2223057409 LKA_OptUsmSta "LKA_OptionUsmStatus ##2G##LDW_LKA - LKA11 - CF_LKA_Opt_USM";
CM_ SG_ 2223057409 LKA_RcgSta "LKA_RecognitionStatus ##2G##LDW_LKA - LKA11 - CF_LKA_LaneRecogState";
CM_ SG_ 2223057409 LKA_LHLnWrnSta "LKA_LHLaneWarningStatus ##2G##LDW_LKA - LKA11 - CF_LKA_LHWarning";
CM_ SG_ 2223057409 LKA_RHLnWrnSta "LKA_RHLaneWarningStatus ##2G##LDW_LKA - LKA11 - CF_LKA_RHWarning";
CM_ SG_ 2223057409 LKA_HndsoffSnd "LKA_HandsoffSound ##2G##LDW_LKA - LKA11 - CF_LKA_HandsOff_Snd";
CM_ SG_ 2223057409 LKA_SysIndReq "LKA_SystemIndicatorRequest ##2G##LDW_LKA - LKA11 - CF_LKA_SymbolState";
CM_ SG_ 2223057409 ADAS_StrTqReqVal "LKA_SteeringTorqueRequestValue ##2G##LDW_LKA - LKA11 - CR_LKA_StrToqReq";
CM_ SG_ 2223057409 ADAS_ActToiSta "ADAS_ActiveTorqueOverlayInterfaceStatus ##2G##LDW_LKA - LKA11 - CF_LKA_ActToi";
CM_ SG_ 2223057409 ADAS_ToiFltSta "ADAS_TorqueOverlayInterfaceFaultStatus ##2G##LDW_LKA - LKA11 - CF_LKA_ToiFlt";
CM_ SG_ 2223057409 BCA_Rear_WrnSta "BCA_Rear_WarningStatus";
CM_ SG_ 2223057409 LKA_SysWrn "LKA_Additional_Info";
CM_ BO_ 2273435649 "[P] Periodic";
CM_ SG_ 2273435649 ADAS_CMD_Crc31Val "ADAS_CMD_CyclicRedundancyCheck31Value";
CM_ SG_ 2273435649 ADAS_CMD_AlvCnt31Val "ADAS_CMD_AliveCounter31Value";
CM_ SG_ 2273435649 HDA_OptUsmSta "HDA_OptionUSMStatus ##2G##LDW_LKA - HDA11 - CF_HDA_Opt_USM";
CM_ SG_ 2273435649 HDA_CntrlModSta "HDA_ControlModeStatus ##2G##LDW_LKA - HDA11 - CF_HDA_Mode";
CM_ SG_ 2273435649 HDA_InfoPUDis "HDA_InformationPopUpDisplay ##2G##LDW_LKA - HDA11 - CF_HDA_InfoDisplay";
CM_ SG_ 2273435649 HDP_AutoCallReqSta "HDP Auto Call Request State";
CM_ SG_ 2273435649 HDP_DispBarSta "HDP Display Bar State";
CM_ SG_ 2273435649 HDP_OptInfoSta "HDP Option Infomation State";
CM_ SG_ 2273435649 HDA_LFA_SymSta "HDA_LFA_SymbolStatus ##2G##LDW_LKA - HDA11 - CF_HDA_LFA_SymbolState";
CM_ SG_ 2273435649 HDA_LFA_WrnSnd "HDA/LFA Additional Warning Sound";
CM_ SG_ 2273435649 HDA_InfoPUDis1 "HDA_InfomationPopupDisplay";
CM_ SG_ 2273435649 HDP_ActvSta "HDP_ControlActiveStatus";
CM_ SG_ 2273435649 HDP_SysSta "HDP_SystemStatus";
CM_ BO_ 2273435650 "[P] Periodic";
CM_ SG_ 2273435650 HDP_ObstacleDstVal "HDP_InPathObstacleDistance";
CM_ SG_ 2273435650 HDP_ObstacleLatPosVal "HDP_InPathObstaclePositionValue";
CM_ SG_ 2273435650 HDP_InfoPUDis "HDP_InformationPopupDisplay (main pop-up)";
CM_ SG_ 2273435650 HDP_WrngTypPUDis "HDP_WarningTypePopupDisplay (mini pop-up)";
CM_ SG_ 2273435650 HDP_HapticWarnReq "Request for HDP haptic warning";
CM_ SG_ 2273435650 HDP_ActvStaDis "HDP_Active/Deactive Status Display";
CM_ SG_ 2273435650 HDP_OpStaDisp "HDP Operation State Display";
CM_ SG_ 2273435650 HDP_ObstSta "HDP Obstacle State";
CM_ SG_ 2273435650 HDP_SysFlrDisp "HDP System Failure Display";
CM_ SG_ 2273435650 HDP_InhbtOffDispSta "HDP Inhibit Off Display State";
CM_ SG_ 2273435650 HDP_CtRoadSrfcDistVal "HDP Center Road Surface Distance Value";
CM_ SG_ 2273435650 ADAS_DRV_UpDateInfo "ADAS_DRV update state info";
CM_ BO_ 2244046849 "[P] Periodic";
CM_ SG_ 2244046849 ADAS_PRK_Crc1Val "ADAS_PRK_CyclicRedundancyCheck1Value";
CM_ SG_ 2244046849 ADAS_PRK_AlvCnt1Val "ADAs_PRK_AliveCounter1Value";
CM_ SG_ 2244046849 PCA_RrEquipSta "PCA_RearEquipmentStatus";
CM_ SG_ 2244046849 PCA_SysFlrSta "PCA_SystemFailureStatus";
CM_ SG_ 2244046849 PCA_RrWrngLvlSta "PCA_RearWarningLevelStatus";
CM_ SG_ 2244046849 PCA_ModDis "PCA_ ModeDisplay";
CM_ SG_ 2244046849 PCA_WrngSndCtSta "PCA_WarningSoundCenterStatus";
CM_ SG_ 2244046849 PCA_WrngSndLtSta "PCA_WarningSoundLeftStatus";
CM_ SG_ 2244046849 PCA_WrngSndRtSta "PCA_WarningSoundRightStatus";
CM_ SG_ 2244046849 PCA_HptReq "PCA_HapticRequest";
CM_ SG_ 2244046849 PCA_BrkReq "PCA_BrakeRequest";
CM_ SG_ 2244046849 PCA_EpbReq "PCA_EPBRequest";
CM_ SG_ 2244046849 PCA_DclTrgtVal "PCA_DecelerationTargetValue";
CM_ SG_ 2244046849 PCA_DgrSta "PCA_DegreeStatus";
CM_ SG_ 2244046849 ADAS_PRK_PDW_SysFlrSta "PDW System Failure State";
CM_ BO_ 2244046850 "[P] Periodic";
CM_ SG_ 2244046850 PCA_RrEquipChkSta "PCA RearEquipmentCheckStatus";
CM_ SG_ 2244046850 PCA_FrWrngLvlSta "PCA_FrontWarningLevelStatus";
CM_ SG_ 2244046850 PCA_LtWrngLvlSta "PCA_LeftWarningLevelStatus";
CM_ SG_ 2244046850 ADAS_PRK_PDW_OptTyp "Option information for None, PDW-R, PDW-FR, PDW-FSR";
CM_ SG_ 2244046850 PCA_RtWrngLvlSta "PCA_RightWarningLevelStatus";
CM_ SG_ 2244046850 PCA_RrFlrDis "PCA_RearFailureDisplay";
CM_ SG_ 2244046850 PCA_FrFlrDis "PCA_FrontFailureDisplay";
CM_ SG_ 2244046850 PCA_LtFlrDis "PCA_LeftFailureDisplay";
CM_ SG_ 2244046850 PCA_RtFlrDis "PCA_RightFailureDisplay";
CM_ SG_ 2244046850 PCA_FrBndryLn "PCA - Front Boundary Line Display Status";
CM_ SG_ 2244046850 PCA_RrBndryLn "PCA - Rear Boundary Line Display Status";
CM_ SG_ 2244046850 PCA_LtBndryLn "PCA - Left Boundary Line Display Status";
CM_ SG_ 2244046850 PCA_RtBndryLn "PCA - Right Boundary Line Display Status";
CM_ SG_ 2244046850 PCA_WrngPhrs "PCA - Warning Phrase Display Status";
CM_ SG_ 2244046850 PCA_FrSdEquipChkSta "PCA_FrontSideEquipmentCheckStatus";
CM_ BO_ 1030 "[PE] Periodic and On Event";
CM_ SG_ 1030 APSM_SWVerMajor1 "First Word(ASCII) in APSM S/W Ver";
CM_ SG_ 1030 APSM_SWVerMinor1 "Second Word(ASCII) in APSM S/W Ver";
CM_ SG_ 1030 APSM_SWVerMinor2 "Third Word(ASCII) in APSM S/W Ver";
CM_ BO_ 1031 "[PE] Periodic and On Event";
CM_ SG_ 1031 APSM_AstStEsyAcsUSMSta "USM_MovingValue";
CM_ SG_ 1031 APSM_LimSetSta "APSM limit setting state";
CM_ SG_ 1031 APSM_FootRest_Opt "Foot Rest OPTION";
CM_ SG_ 1031 APSM_RSE_Opt "RSE OPTION";
CM_ BO_ 527 "[PE] Periodic and On Event";
CM_ SG_ 527 ATS_DrvStRseFwdBtn "Drive Seat  RSE Forward Touch Button";
CM_ SG_ 527 ATS_DrvStRseBwdBtn "Drive Seat  RSE Backward Touch Button";
CM_ SG_ 527 ATS_RRRestModBtn "Rear Right Rest Mode Touch Button";
CM_ SG_ 527 ATS_RRResetModBtn "Rear Right Return Mode Touch Button";
CM_ SG_ 527 ATS_RRAvWtcModBtn "Rear Right AV Watching Mode Touch Button";
CM_ SG_ 527 ATS_RRReadingModBtn "Rear Right Reading Mode Touch Button";
CM_ SG_ 527 ATS_RLRestModBtn "Rear Left Rest Mode Touch Button";
CM_ SG_ 527 ATS_RLResetModBtn "Rear Left Return Mode Touch Button";
CM_ BO_ 543 "[PE] Periodic and On Event";
CM_ SG_ 543 ATS_AstStSldFwdBtn "Assist Power Seat Slide Forward Rear Walk In Button";
CM_ SG_ 543 ATS_AstStSldBwdBtn "Assist Power Seat Slide Backward Rear Walk In Button";
CM_ SG_ 543 ATS_AstStRclFwdBtn "Assist Power Seat Recline Forward Rear Walk In Button";
CM_ SG_ 543 ATS_AstStRclBwdBtn "Assist Power Seat Recline Backward Rear Walk In Button";
CM_ SG_ 543 ATS_AstStHgtUpBtn "Assist Power Seat Height Up Walk In Button";
CM_ SG_ 543 ATS_AstStHgtDnBtn "Assist Power Seat Height Dn Walk In Button";
CM_ SG_ 543 ATS_AstStHRestUpBtn "Assist Power Seat Head Rest Up Walk In Button";
CM_ SG_ 543 ATS_AstStHRestDnBtn "Assist Power Seat  Head Rest Dn Walk In Button";
CM_ SG_ 543 ATS_AstStHRestFwdBtn "Assist Power Seat Head Rest Forward  Walk In Button";
CM_ SG_ 543 ATS_AstStHRestBwdBtn "Assist Power Seat Head Rest Backward  Walk In Button";
CM_ SG_ 543 ATS_AstStHRestFldBtn "Assist Power Seat Head Rest Folding  Walk In Button";
CM_ SG_ 543 ATS_AstStHRestUnFldBtn "Assist Power Seat Head Rest Unfolding  Walk In Button";
CM_ SG_ 543 ATS_AstStRseFwdBtn "Assist Power Seat RSE Forward  Walk In Button";
CM_ SG_ 543 ATS_AstStRseBwdBtn "Assist Power Seat RSE Backward Walk In Button";
CM_ SG_ 543 ATS_AstStFRestFldBtn "Assist Power Seat Foot Rest Folding Walk In Button";
CM_ SG_ 543 ATS_AstStFRestUnFldBtn "Assist Power Seat Foot Rest Unfolding Walk In Button";
CM_ SG_ 543 ATS_AstTltUpBtn "Assist Power Seat  Tilt Up Walk In Button";
CM_ SG_ 543 ATS_AstTltDnBtn "Assist Power Seat Tilt Down  Walk In Button";
CM_ BO_ 623 "[PE] Periodic and On Event";
CM_ SG_ 623 ATS_ARSOpenCloseStatus "Armrest Open / Close Status";
CM_ SG_ 623 ATS_RLLumbarDefBtn "Rear Left Lumbar Deflation Touch Button";
CM_ SG_ 623 ATS_RLLumbarLowBtn "Rear Left Lumbar Low Touch Button";
CM_ SG_ 623 ATS_RLLumbarMidBtn "Rear Left Lumbar Middle Touch Button";
CM_ SG_ 623 ATS_RLLumbarUpBtn "Rear Left Lumbar Up Touch Button";
CM_ SG_ 623 ATS_RLBolsterDefBtn "Rear Left Bolster Deflation Touch Button";
CM_ SG_ 623 ATS_RLBolsterInfSw "Rear Left Bolster Inflation Touch Button";
CM_ SG_ 623 ATS_RRLumbarDefBtn "Rear Right Lumbar Deflation Touch Button";
CM_ SG_ 623 ATS_RRLumbarLowBtn "Rear Right Lumbar Low Touch Button";
CM_ SG_ 623 ATS_RRLumbarMidBtn "Rear Right Lumbar Middle Touch Button";
CM_ SG_ 623 ATS_RRLumbarUpBtn "Rear Right Lumbar Up Touch Button";
CM_ SG_ 623 ATS_RRBolsterDefBtn "Rear Right Bolster Deflation Touch Button";
CM_ SG_ 623 ATS_RRBolsterInfSw "Rear Right Bolster Inflation Touch Button";
CM_ BO_ 1141 "[PE] Periodic and On Event";
CM_ SG_ 1141 Ast_SHVU_SeatOptSta "Ast Seat Heater/Vent option info";
CM_ SG_ 1141 Ast_SHVU_HtSwHiIndSta "Ast Seat Heater Switch High Indicator Status";
CM_ SG_ 1141 Ast_SHVU_HtSwMidIndSta "Ast Seat Heater Switch Mid Indicator Status";
CM_ SG_ 1141 Ast_SHVU_HtSwLowIndSta "Ast Seat Heater Switch Low Indicator Status";
CM_ SG_ 1141 Ast_SHVU_VntSwHiIndSta "Ast Seat Vent Switch High Indicator Status";
CM_ SG_ 1141 Ast_SHVU_VntSwMidIndSta "Ast Seat Vent Switch Mid Indicator Status";
CM_ SG_ 1141 Ast_SHVU_VntSwLowIndSta "Ast Seat Vent Switch Low Indicator Status";
CM_ SG_ 1141 Ast_SHVU_HtBlcUSMSta "Hetaer Balance Assistant USM R vaule";
CM_ SG_ 1141 Ast_SHVU_SeatHtOperSta "Ast Seat Heater/Vent current operation state";
CM_ SG_ 1141 Ast_SHVU_HtSwHiIndSta_RHD "Ast Seat Heater Switch High Indicator Status(RHD)";
CM_ SG_ 1141 Ast_SHVU_HtSwMidIndSta_RHD "Ast Seat Heater Switch Mid Indicator Status(RHD)";
CM_ SG_ 1141 Ast_SHVU_HtSwLowIndSta_RHD "Ast Seat Heater Switch Low Indicator Status(RHD)";
CM_ SG_ 1141 Ast_SHVU_VntSwHiIndSta_RHD "Ast Seat Vent Switch High Indicator Status(RHD)";
CM_ SG_ 1141 Ast_SHVU_VntSwMidIndSta_RHD "Ast Seat Vent Switch Mid Indicator Status(RHD)";
CM_ SG_ 1141 Ast_SHVU_VntSwLowIndSta_RHD "Ast Seat Vent Switch Low Indicator Status(RHD)";
CM_ BO_ 1050 "[PE] Periodic and On Event";
CM_ SG_ 1050 BCM_Crc7Val "BCM_CyclicRedundancyCheck7Value";
CM_ SG_ 1050 BCM_AlvCnt7Val "BCM_AliveCounter7Value";
CM_ SG_ 1050 Lamp_HiPrioHzrdReq "Lamp_HighPriorityHazardRequest ##2G##BCM - BCMmsg19 - C_HazardFromBCMHigh";
CM_ SG_ 1050 Lamp_LoPrioHzrdReq "Lamp_LowPriorityHazardStatus ##2G##BCM - BCMmsg19 - C_HazardfromBCMLow";
CM_ SG_ 1050 Lamp_IntTailLmpOnReq "Lamp_InternalTailLampOnRequest ##2G##BCM - BCMmsg19 - C_IntTailOn";
CM_ SG_ 1050 Lamp_ExtrnlTailLmpOnReq "Lamp_ExternalTailLampOnRequest ##2G##BCM - BCMmsg19 - C_ExtTailOn";
CM_ SG_ 1050 Lamp_HdLmpLoOnReq "Lamp_HeadLampLowOnRequest ##2G##BCM - BCMmsg19 - C_HLpLowOn";
CM_ SG_ 1050 Lamp_HdLmpHiOnReq "Lamp_HeadLampHighOnRequest ##2G##BCM - BCMmsg19 - C_HLpHighOn";
CM_ SG_ 1050 Lamp_AvTailLmpSta "Lamp_AvTailLampStatus ##2G##BCM - BCMmsg18 - C_AvTail";
CM_ BO_ 1052 "[PE] Periodic and On Event";
CM_ SG_ 1052 BCM_Crc9Val "BCM_CyclicRedundancyCheck9Value";
CM_ SG_ 1052 BCM_AlvCnt9Val "BCM_AliveCounter9Value";
CM_ SG_ 1052 Lamp_AutoLtSnsrNightSta "Lamp_AutoLightSensorNightStatus ##2G##BCM - BCMmsg24 - C_AutolightValue";
CM_ SG_ 1052 Lamp_AutoLtSnsrHorVal "Lamp_AutoLightSensorHorValue ##2G##BCM - BCMmsg24 - C_AutolightSensorHorState";
CM_ BO_ 1124 "[PE] Periodic and On Event";
CM_ SG_ 1124 BCM_Crc15Val "BCM_CyclicRedundancyCheck15Value";
CM_ SG_ 1124 BCM_AlvCnt15Val "BCM_AliveCounter15Value";
CM_ SG_ 1124 Window_DrvrSdWdwActSta "Window_DriverSideWindowActionStatus ##2G##BCM - BCMmsg25 - C_DrvWindowActState";
CM_ SG_ 1124 Window_AsstSdWdwActSta "Window_AssistantSideWindowActionStatus ##2G##BCM - BCMmsg25 - C_AstWindowActState";
CM_ SG_ 1124 Window_RrLftWdwActSta "Window_RearLeftWindowActionStatus ##2G##BCM - BCMmsg25 - C_RLWindowActState";
CM_ SG_ 1124 Window_RrRtWdwActSta "Window_RearRightWindowActionStatus ##2G##BCM - BCMmsg25 - C_RRWindowActState";
CM_ SG_ 1124 Window_DrvrSdWdwDetailOpnSta "Window_DriverSideWindowDetailOpenStatus ##2G##BCM - BCMmsg26 - C_DrvWdwDetailOpenState";
CM_ SG_ 1124 Window_AsstSdWdwDetailOpnSta "Window_AssistantSideWindowDetailOpenStatus ##2G##BCM - BCMmsg26 - C_AstWdwDetailOpenState";
CM_ SG_ 1124 Window_DrvrSdWdwErrAntPinch "Window_DriverSideWindowErrorAntiPinch ##2G##BCM - BCMmsg26 - C_DrvWdwErrAntiPinch";
CM_ SG_ 1124 Window_RrLftWdwDetailOpnSta "Window_RearLeftWindowDetailOpenStatus ##2G##BCM - BCMmsg26 - C_RLWdwDetailOpenState";
CM_ SG_ 1124 Window_RrRtWdwDetailOpnSta "Window_RearRightWindowDetailOpenStatus ##2G##BCM - BCMmsg26 - C_RRWdwDetailOpenState";
CM_ SG_ 1124 Window_AsstSdWdwErrAntPinch "Window_AssistantSideWindowErrorAntiPinch ##2G##BCM - BCMmsg26 - C_AstWdwErrAntiPinch";
CM_ SG_ 1124 Window_RrLftWdwErrAntPinch "Window_RearLeftWindowErrorAntiPinch ##2G##BCM - BCMmsg26 - C_RLWdwErrAntiPinch";
CM_ SG_ 1124 Window_RrRtWdwErrAntPinch "Window_RearRightWindowErrorAntiPinch ##2G##BCM - BCMmsg26 - C_RRWdwErrAntiPinch";
CM_ SG_ 1124 SunRoof_RrBlindPosSta "SunRoof_RearBlindPositionStatus";
CM_ BO_ 614 "[PE] Periodic and On Event";
CM_ SG_ 614 EMCU_Crc1Val "EMCU_CyclicRedundancyCheck1Value";
CM_ SG_ 614 EMCU_AlvCnt1Val "EMCU_AliveCounter1Value";
CM_ SG_ 614 EMCU_LHActSta "EMCU_LeftActuatorStatus";
CM_ SG_ 614 EMCU_RHActSta "EMCU_RightActuatorStatus";
CM_ SG_ 614 EMCU_DeltaSpdVal "EMCU_DeltaSpeedValue";
CM_ SG_ 614 EMCU_System_Sta "EMCU_SystemStatus";
CM_ BO_ 2214658049 "[P] Periodic";
CM_ SG_ 2214658049 EMS_Crc2Val "EMS_CyclicRedundancyCheck2Value";
CM_ SG_ 2214658049 EMS_AlvCnt2Val "EMS_AliveCounter2Value";
CM_ SG_ 2214658049 ENG_BrkSwSta "ENG_BrakeSwitchStatus ##2G##EMS - EMS12 - BRAKE_ACT";
CM_ SG_ 2214658049 ENG_ObdFrzFrmSta "ENG_ObdFreezeFrameStatus ##2G##EMS - EMS12 - OBD_FRF_ACK";
CM_ SG_ 2214658049 ENG_EngClntTempVal "ENG_EngineCoolantTemperatureValue ##2G##EMS - EMS12 - TEMP_ENG";
CM_ SG_ 2214658049 ENG_MafCrctVal "ENG_MassAirFlowCorrectionValue ##2G##EMS - EMS12 - MAF_FAC_ALTI_MMV";
CM_ SG_ 2214658049 ENG_BattDscnctSta "ENG_BatteryDisconnectStatus ##2G##EMS - EMS12 - VB_OFF_ACT";
CM_ SG_ 2214658049 OBD_MilConfgVal "OBD_MalfunctionIndicationLampConfigurationValue ##2G##EMS - EMS12 - CONF_MIL_FMY";
CM_ SG_ 2214658049 ENG_EngSta "ENG_EngineStatus ##2G##EMS - EMS16 - ENG_STAT";
CM_ BO_ 2214658050 "[P] Periodic";
CM_ SG_ 2214658050 ENG_Ack4EngStpSta "ENG_AcknowledgeForEngineStopStatus ##2G##EMS - EMS12 - ACK_ES";
CM_ SG_ 2214658050 ENG_AccDrvAlertDisp "The status of No Auto cruise Engaged or Auto cruise Disengaged.";
CM_ SG_ 2214658050 DSL_GlowCtrlReq "DSL_GlowControlRequest ##2G##EMS - EMS12 - GP_CTL";
CM_ SG_ 2214658050 ENG_GlowLmpSta "ENG_GlowLampStatus ##2G##EMS - EMS16 - GLOW_STAT";
CM_ SG_ 2214658050 ENG_ThrPosVal "ENG_ThrottlePositionValue ##2G##EMS - EMS12 - TPS";
CM_ SG_ 2214658050 ENG_OverDrvOffReq "ENG_OverDriveOffRequest ##2G##EMS - EMS12 - OD_OFF_REQ";
CM_ SG_ 2214658050 ENG_AccelPdlVal "ENG_AcceleratorPedalValue ##2G##EMS - EMS12 - PV_AV_CAN";
CM_ SG_ 2214658050 ENG_AccActSta "ENG_AutoCruiseControlActiveStatus ##2G##EMS - EMS12 - ACC_ACT";
CM_ SG_ 2214658050 ACC_CrsMainSwLmpSta "ACC_CruiseMainSwLampStatus ##2G##EMS - EMS16 - CRUISE_LAMP_M";
CM_ SG_ 2214658050 ACC_CrsSetSwLmpSta "ACC_CruiseSetSwLampStatus ##2G##EMS - EMS16 - CRUISE_LAMP_S";
CM_ SG_ 2214658050 ENG_LV_FUP_ENA_THD "Fuel prsssure state ##2G##EMS - LPI11 - LV_FUP_ENA_THD";
CM_ SG_ 2214658050 ENG_SoakTimeErrSta "ENG_SoakTimeErrorStatus ##2G##EMS - EMS16 - SOAK_TIME_ERROR";
CM_ SG_ 2214658050 ENG_SoakTimeVal "ENG_SoakTimeValue ##2G##EMS - EMS16 - SOAK_TIME";
CM_ SG_ 2214658050 ENG_SprkTimeVal "ENG_SparkTimeValue ##2G##EMS - EMS16 - SPK_TIME_CUR";
CM_ SG_ 2214658050 ENG_CltchOpSta "ENG_ClutchStatus ##2G##EMS - EMS12 - CLU_ACK";
CM_ SG_ 2214658050 EMS_BrkReq_Slope "Brake request at slope for anti-stall";
CM_ BO_ 2214658051 "[P] Periodic";
CM_ SG_ 2214658051 ENG_MinIndTqVal "ENG_MinimumIndicatedTorqueValue ##2G##EMS - EMS16 - TQI_MIN";
CM_ SG_ 2214658051 ENG_TrgtTqVal "ENG_TargetTorqueValue ##2G##EMS - EMS16 - TQI_TARGET";
CM_ SG_ 2214658051 ENG_MaxIndTqVal "ENG_MaximumIndicatedTorqueValue ##2G##EMS - EMS16 - TQI_MAX";
CM_ SG_ 2214658051 ENG_AppAccelPdlSta "ENG_AppliedAcceleratorPedalStatus ##2G##EMS - EMS16 - CF_Ems_AclAct";
CM_ SG_ 2214658051 ENG_BrkCtrlReq "ENG_BrakeControlRequest ##2G##EMS - EMS19 - CF_Ems_BrkReq";
CM_ SG_ 2214658051 ACC_DnShftCtrlReq "ACC_DownShiftControlRequest ##2G##EMS - EMS19 - CF_Ems_DnShftReq";
CM_ BO_ 2214658052 "[P] Periodic";
CM_ SG_ 2214658052 ENG_DclBrkCntrlReq "ENG_DecelerationBrakeControlRequest ##2G##EMS - EMS19 - CF_Ems_DecelReq";
CM_ SG_ 2214658052 ENG_BstPrsrVal "ENG_BoostPressureValue ##2G##EMS - EMS19 - CR_Ems_BstPre";
CM_ SG_ 2214658052 ENG_EngOilTempVal "ENG_EngineOilTemperatureValue ##2G##EMS - EMS19 - CR_Ems_EngOilTemp";
CM_ SG_ 2214658052 ENG_AmbtTempModelVal "ENG_AmbientTemperatureModelValue ##2G##EMS - EMS19 - CF_Ems_ModeledAmbTemp";
CM_ SG_ 2214658052 ENG_DpfWrngSta "ENG_DpfWarningStatus ##2G##EMS - EMS19 - DPF_LAMP_STAT";
CM_ SG_ 2214658052 ENG_BattWrngLmpSta "ENG_BatteryWarningLampStatus ##2G##EMS - EMS19 - BAT_LAMP_STAT";
CM_ SG_ 2214658052 ENG_OilPrsrWrngLmpSta "ENG_OilPressureWarningLampStatus ##2G##EMS - EMS19 - CF_Ems_OPSFail";
CM_ SG_ 2214658052 ENG_IsgInhbtLmpSta "ENG_IsgInhibitLampStatus ##2G##EMS - EMS19 - ISG_INHIBIT_LAMP_STAT";
CM_ BO_ 1048 "[PE] Periodic and On Event";
CM_ SG_ 1048 ICU_Crc8Val "ICU_CyclicRedundancyCheck8Value";
CM_ SG_ 1048 ICU_AlvCnt8Val "ICU_AliveCounter8Value";
CM_ SG_ 1048 DriveTypeOption "##2G## -  - C_DriveTypeOption,CF_Gway_DriveTypeOption";
CM_ SG_ 1048 Warn_RrLftSBRMATSwSta "##2G## -  - C_RLSBRMatSw";
CM_ SG_ 1048 Warn_RrRhtSBRMATSwSta "##2G## -  - C_RRSBRMatSw";
CM_ SG_ 1048 Lamp_FootLampOnReq "##2G## -  - C_FootLpOn";
CM_ SG_ 1048 Lamp_MoodLampOnReq "##2G## -  - C_MoodLpOn";
CM_ SG_ 1048 ICU_PowerAutoCutModSta "##2G## -  - CF_Gway_ICUPowerAutoCutMode";
CM_ SG_ 1048 ICU_SoCBattStaMsgReq "##2G## -  - Batt_SoCWarningAlertMsgReq";
CM_ SG_ 1048 Brake_SwSta_ICU "Brake Switch Status ##2G## -  - C_BrakeSw";
CM_ SG_ 1048 C_3rdRRSeatBeltSW "3rd Rear Right Seat Belt Switch Status";
CM_ SG_ 1048 C_3rdRLSeatBeltSW "3rd Rear Left Seat Belt Switch Status";
CM_ SG_ 1048 HSWS_SysWrngSta_ICU "HSWS Status ##2G## -  - C_HSWSSysStat";
CM_ BO_ 1616 "[EC] On Event and On Change";
CM_ SG_ 1616 MKBD_IllumiState "Signal to confirm completion transmission of illumination information between MKBD and HU";
CM_ SG_ 1616 MKBD_SeatKeySet "The signal for transmitting Seat Key inputs from MKBD to Seat ECU";
CM_ BO_ 1578 "[EW] On Event and On Write";
CM_ SG_ 1578 PSB_CCP_CRO_Byte0 "EOL Message for PSB";
CM_ SG_ 1578 PSB_CCP_CRO_Byte2 "EOL Message for PSB";
CM_ SG_ 1578 PSB_CCP_CRO_Byte3 "EOL Message for PSB";
CM_ SG_ 1578 PSB_CCP_CRO_Byte4 "EOL Message for PSB";
CM_ SG_ 1578 PSB_CCP_CRO_Byte5 "EOL Message for PSB";
CM_ SG_ 1578 PSB_CCP_CRO_Byte6 "EOL Message for PSB";
CM_ SG_ 1578 PSB_CCP_CRO_Byte7 "EOL Message for PSB";
CM_ SG_ 1578 PSB_CCP_CRO_Byte1 "EOL Message for PSB";
CM_ BO_ 1579 "[EW] On Event and On Write";
CM_ SG_ 1579 PSB_CCP_DTO_Byte0 "EOL Message for PSB";
CM_ SG_ 1579 PSB_CCP_DTO_Byte2 "EOL Message for PSB";
CM_ SG_ 1579 PSB_CCP_DTO_Byte3 "EOL Message for PSB";
CM_ SG_ 1579 PSB_CCP_DTO_Byte4 "EOL Message for PSB";
CM_ SG_ 1579 PSB_CCP_DTO_Byte5 "EOL Message for PSB";
CM_ SG_ 1579 PSB_CCP_DTO_Byte6 "EOL Message for PSB";
CM_ SG_ 1579 PSB_CCP_DTO_Byte7 "EOL Message for PSB";
CM_ SG_ 1579 PSB_CCP_DTO_Byte1 "EOL Message for PSB";
CM_ BO_ 1027 "[PE] Periodic and On Event";
CM_ SG_ 1027 Win_ElecChildLkSwOpt "Window_ElectricChildLockSwitchOption";
CM_ SG_ 1027 Win_PwrWdwSwTyp "Window_PowerWindowSwitchType";
CM_ SG_ 1027 Win_DrvIMSSwSta "Window_DriverIMSSwitchStatus";
CM_ SG_ 1027 Win_DrvPwrWdwSwSta "Window_DriverPowerWindowSwitchStatus";
CM_ SG_ 1027 Win_AsstPwrWdwSwSta "Window_AssistantPowerWindowSwitchStatus";
CM_ SG_ 1027 Win_CtrlDrLkSwSta "Window_CentralDoorLockSwitchStatus";
CM_ SG_ 1027 Win_RrLftPwrWdwSwSta "Window_RearLeftPowerWindowSwitchStatus";
CM_ SG_ 1027 Win_RrRtPwrWdwSwSta "Window_RearRightPowerWindowSwitchStatus";
CM_ SG_ 1027 Win_CtrlDrUnLkSwSta "Window_CentralDoorUnlockSwitchStatus";
CM_ SG_ 1027 Win_PwrWdwLkSwSta "Window_PowerWindowLockSwitchStatus";
CM_ SG_ 1027 Win_RrCrtSwSta "Window_RearCurtainSwitchStatus";
BA_DEF_ BO_ "DiagState" ENUM "No","Yes" ;
BA_DEF_ BO_ "DiagResponse" ENUM "No","Yes" ;
BA_DEF_ BO_ "DiagRequest" ENUM "No","Yes" ;
BA_DEF_ BO_ "TpMessage" ENUM "No","Yes" ;
BA_DEF_ BO_ "UsrMsgIDSforwardDeviation" INT 0 100 ;
BA_DEF_ BO_ "UsrMsgIDSbackwardDeviation" INT 50 1000 ;
BA_DEF_ BO_ "GenMsgCycleTime" INT 0 2000 ;
BA_DEF_ BO_ "GenMsgStartDelayTime" INT 0 2000 ;
BA_DEF_ BO_ "GenMsgSendType" ENUM "Cyclic","NoMsgSendType" ;
BA_DEF_ BO_ "GenMsgCycleTimeFast" INT 0 500 ;
BA_DEF_ BO_ "GenMsgDelayTime" INT 0 20 ;
BA_DEF_ BO_ "GenMsgILSupport" ENUM "No","Yes" ;
BA_DEF_ BO_ "GenMsgNrOfRepetition" INT 0 3 ;
BA_DEF_ BO_ "NmMessage" ENUM "No","Yes" ;
BA_DEF_ BO_ "NWM-Botschaft" ENUM "No","Yes" ;
BA_DEF_ BO_ "TpTxIndex" INT 0 255 ;
BA_DEF_ BO_ "VFrameFormat" ENUM "StandardCAN","ExtendedCAN","reserved","reserved","reserved","reserved","reserved","reserved","reserved","reserved","reserved","reserved","reserved","reserved","StandardCAN_FD","ExtendedCAN_FD" ;
BA_DEF_ SG_ "UserSigValidity" ENUM "B+","ACC","IG","IG1","IG2","IG3","IG1 or IG2","IG1 or IG3","Undef" ;
BA_DEF_ SG_ "TimeoutValue" STRING ;
BA_DEF_ SG_ "UsrSigPurpose" ENUM "Undef","FN","DIAG","DIAG(Req)","DIAG(Res)","DIAG(Phy)","DEV","CCP(Req)","CCP(Res)","NM","TP" ;
BA_DEF_ SG_ "GenSigStartValue" INT 0 1215752192 ;
BA_DEF_ SG_ "NetworkRequest" ENUM "Yes","No" ;
BA_DEF_ SG_ "NetworkRequestHoldingTime" INT 0 65535 ;
BA_DEF_ SG_ "Description" STRING ;
BA_DEF_ SG_ "Version" STRING ;
BA_DEF_ SG_ "GenSigEnvVarType" ENUM "Int","Float","Undef" ;
BA_DEF_ SG_ "GenSigSendType" ENUM "Cyclic","OnWrite","OnWriteWithRepetition","OnChange","OnChangeWithRepetition","IfActive","IfActiveWithRepetition","NoSigSendType","OnChangeAndIfActive","OnChangeAndIfActiveWithRepetition" ;
BA_DEF_ SG_ "GwSigLatencyTime" INT 0 65536 ;
BA_DEF_ SG_ "GwSigMissingSourceType" ENUM "Undef","OldValue","DefaultValue","InitialValue" ;
BA_DEF_ SG_ "NWM-WakeupAllowed" ENUM "<n.a.>" ;
BA_DEF_ SG_ "RoutingFactor" INT 1 1215752192 ;
BA_DEF_REL_ BU_SG_REL_ "GenSigTimeoutTime" INT 0 7000 ;
BA_DEF_DEF_ "DiagState" "No" ;
BA_DEF_DEF_ "DiagResponse" "No" ;
BA_DEF_DEF_ "DiagRequest" "No" ;
BA_DEF_DEF_ "TpMessage" "No" ;
BA_DEF_DEF_ "UsrMsgIDSforwardDeviation" 10 ;
BA_DEF_DEF_ "UsrMsgIDSbackwardDeviation" 100 ;
BA_DEF_DEF_ "GenMsgCycleTime" 200 ;
BA_DEF_DEF_ "GenMsgStartDelayTime" 0 ;
BA_DEF_DEF_ "GenMsgSendType" "NoMsgSendType" ;
BA_DEF_DEF_ "GenMsgCycleTimeFast" 40 ;
BA_DEF_DEF_ "GenMsgDelayTime" 20 ;
BA_DEF_DEF_ "GenMsgILSupport" "Yes" ;
BA_DEF_DEF_ "GenMsgNrOfRepetition" 3 ;
BA_DEF_DEF_ "NmMessage" "No" ;
BA_DEF_DEF_ "NWM-Botschaft" "No" ;
BA_DEF_DEF_ "TpTxIndex" 0 ;
BA_DEF_DEF_ "VFrameFormat" "StandardCAN" ;
BA_DEF_DEF_ "UserSigValidity" "IG" ;
BA_DEF_DEF_ "TimeoutValue" "" ;
BA_DEF_DEF_ "UsrSigPurpose" "FN" ;
BA_DEF_DEF_ "GenSigStartValue" 0 ;
BA_DEF_DEF_ "NetworkRequest" "No" ;
BA_DEF_DEF_ "NetworkRequestHoldingTime" 0 ;
BA_DEF_DEF_ "Description" "" ;
BA_DEF_DEF_ "Version" "" ;
BA_DEF_DEF_ "GenSigEnvVarType" "Undef" ;
BA_DEF_DEF_ "GenSigSendType" "NoSigSendType" ;
BA_DEF_DEF_ "GwSigLatencyTime" 40 ;
BA_DEF_DEF_ "GwSigMissingSourceType" "Undef" ;
BA_DEF_DEF_ "NWM-WakeupAllowed" "<n.a.>" ;
BA_DEF_DEF_ "RoutingFactor" 1 ;
BA_DEF_DEF_REL_ "GenSigTimeoutTime" 500 ;
BA_ "GenMsgSendType" BO_ 2223057409 0;
BA_ "GenMsgCycleTime" BO_ 2223057409 50;
BA_ "GenMsgCycleTimeFast" BO_ 2223057409 0;
BA_ "GenMsgNrOfRepetition" BO_ 2223057409 0;
BA_ "VFrameFormat" BO_ 2223057409 1;
BA_ "Description" SG_ 2223057409 ADAS_CMD_Crc30Val "The data area for CRC calculation is based on the data length (DLC) of the message DB.

The CRC shall be calculated over the entire data block (excluding the CRC bytes) including the user data, alive counter and Data ID

 

- CRC Polynomial (0x1021) , Initial Value : 0xFFFF, XOR value : 0x0000, Data ID : Message ID + 0xF800 

- The initial value is for CRC calculation and the message should be sent with the calculated result value. 

- The mathematical expression to 16 bit CRC polynomial is given here. G(x) = x16 + x12 + x5 + 1";
BA_ "GenSigStartValue" SG_ 2223057409 ADAS_CMD_Crc30Val 65535;
BA_ "UserSigValidity" SG_ 2223057409 ADAS_CMD_Crc30Val 3;
BA_ "RoutingFactor" SG_ 2223057409 ADAS_CMD_Crc30Val 5;
BA_ "Version" SG_ 2223057409 ADAS_CMD_Crc30Val "18.11.08";
BA_ "Description" SG_ 2223057409 ADAS_CMD_AlvCnt30Val "For the first transmission request for a data element the counter shall be initialized with 0 and shall be incremented by 1 for every subsequent send request. 

When the counter reaches the maximum value(0xFF), then it shall restart with 0 for the next send request";
BA_ "UserSigValidity" SG_ 2223057409 ADAS_CMD_AlvCnt30Val 3;
BA_ "RoutingFactor" SG_ 2223057409 ADAS_CMD_AlvCnt30Val 5;
BA_ "Version" SG_ 2223057409 ADAS_CMD_AlvCnt30Val "18.11.08";
BA_ "UserSigValidity" SG_ 2223057409 LKA_OptUsmSta 3;
BA_ "RoutingFactor" SG_ 2223057409 LKA_OptUsmSta 5;
BA_ "Version" SG_ 2223057409 LKA_OptUsmSta "17.12.02";
BA_ "UserSigValidity" SG_ 2223057409 LKA_RcgSta 3;
BA_ "RoutingFactor" SG_ 2223057409 LKA_RcgSta 5;
BA_ "Version" SG_ 2223057409 LKA_RcgSta "18.10.12";
BA_ "UserSigValidity" SG_ 2223057409 LKA_LHLnWrnSta 3;
BA_ "RoutingFactor" SG_ 2223057409 LKA_LHLnWrnSta 5;
BA_ "Version" SG_ 2223057409 LKA_LHLnWrnSta "19.02.05";
BA_ "UserSigValidity" SG_ 2223057409 LKA_RHLnWrnSta 3;
BA_ "RoutingFactor" SG_ 2223057409 LKA_RHLnWrnSta 5;
BA_ "Version" SG_ 2223057409 LKA_RHLnWrnSta "19.02.05";
BA_ "UserSigValidity" SG_ 2223057409 LKA_HndsoffSnd 3;
BA_ "RoutingFactor" SG_ 2223057409 LKA_HndsoffSnd 5;
BA_ "Version" SG_ 2223057409 LKA_HndsoffSnd "17.12.02";
BA_ "UserSigValidity" SG_ 2223057409 LKA_SysIndReq 3;
BA_ "RoutingFactor" SG_ 2223057409 LKA_SysIndReq 5;
BA_ "Version" SG_ 2223057409 LKA_SysIndReq "20.12.00";
BA_ "Description" SG_ 2223057409 ADAS_StrTqReqVal "This is the driver torque overlay demand value. A negative value represents a torque that would accelerate the steering wheel in a clockwise direction. This signal is always zero whilst the TOI is inactive.";
BA_ "GenSigStartValue" SG_ 2223057409 ADAS_StrTqReqVal 1024;
BA_ "UserSigValidity" SG_ 2223057409 ADAS_StrTqReqVal 3;
BA_ "RoutingFactor" SG_ 2223057409 ADAS_StrTqReqVal 5;
BA_ "Version" SG_ 2223057409 ADAS_StrTqReqVal "18.10.00";
BA_ "Description" SG_ 2223057409 ADAS_ActToiSta "This is a flag that is set to 1 when requesting the steering to activate the torque overlay interface (TOI).  This must be done before an attempt is made to request non-zero steering torque overlay.";
BA_ "UserSigValidity" SG_ 2223057409 ADAS_ActToiSta 3;
BA_ "RoutingFactor" SG_ 2223057409 ADAS_ActToiSta 5;
BA_ "Version" SG_ 2223057409 ADAS_ActToiSta "18.12.07";
BA_ "Description" SG_ 2223057409 ADAS_ToiFltSta "This fault flag is set when a fault in the LKA system has been detected by the LKA ECU such that LKA can no longer function. CAN failures, internal video ECU failures, hard-wired component (e.g. master switch) failures and other system logic failures are all reported by this flag. Failures reported by the MDPS are not looped back through this flag.";
BA_ "UserSigValidity" SG_ 2223057409 ADAS_ToiFltSta 3;
BA_ "RoutingFactor" SG_ 2223057409 ADAS_ToiFltSta 5;
BA_ "Version" SG_ 2223057409 ADAS_ToiFltSta "18.12.07";
BA_ "Description" SG_ 2223057409 BCA_Rear_WrnSta "This signal indicates BCA-Rear warning for display and sound.";
BA_ "UserSigValidity" SG_ 2223057409 BCA_Rear_WrnSta 3;
BA_ "RoutingFactor" SG_ 2223057409 BCA_Rear_WrnSta 5;
BA_ "Version" SG_ 2223057409 BCA_Rear_WrnSta "18.10.09";
BA_ "Description" SG_ 2223057409 LKA_SysWrn "A signal that provides additional information on the operation of the LKA system for the HMI to display to the driver. This includes additional fault information, reasons for unavailability of the system and additional warnings like the hands-off warning. Some of the information may be displayed for short periods, whilst others like the hands-off warning may be displayed for longer periods.";
BA_ "UserSigValidity" SG_ 2223057409 LKA_SysWrn 3;
BA_ "RoutingFactor" SG_ 2223057409 LKA_SysWrn 5;
BA_ "Version" SG_ 2223057409 LKA_SysWrn "20.12.00";
BA_ "GenMsgSendType" BO_ 2273435649 0;
BA_ "GenMsgCycleTime" BO_ 2273435649 150;
BA_ "GenMsgCycleTimeFast" BO_ 2273435649 0;
BA_ "GenMsgNrOfRepetition" BO_ 2273435649 0;
BA_ "VFrameFormat" BO_ 2273435649 1;
BA_ "Description" SG_ 2273435649 ADAS_CMD_Crc31Val "The data area for CRC calculation is based on the data length (DLC) of the message DB.

The CRC shall be calculated over the entire data block (excluding the CRC bytes) including the user data, alive counter and Data ID

 

- CRC Polynomial (0x1021) , Initial Value : 0xFFFF, XOR value : 0x0000, Data ID : Message ID + 0xF800 

- The initial value is for CRC calculation and the message should be sent with the calculated result value. 

- The mathematical expression to 16 bit CRC polynomial is given here. G(x) = x16 + x12 + x5 + 1";
BA_ "UserSigValidity" SG_ 2273435649 ADAS_CMD_Crc31Val 3;
BA_ "RoutingFactor" SG_ 2273435649 ADAS_CMD_Crc31Val 3;
BA_ "Version" SG_ 2273435649 ADAS_CMD_Crc31Val "18.11.08";
BA_ "Description" SG_ 2273435649 ADAS_CMD_AlvCnt31Val "For the first transmission request for a data element the counter shall be initialized with 0 and shall be incremented by 1 for every subsequent send request. 

When the counter reaches the maximum value(0xFF), then it shall restart with 0 for the next send request";
BA_ "UserSigValidity" SG_ 2273435649 ADAS_CMD_AlvCnt31Val 3;
BA_ "RoutingFactor" SG_ 2273435649 ADAS_CMD_AlvCnt31Val 3;
BA_ "Version" SG_ 2273435649 ADAS_CMD_AlvCnt31Val "18.11.08";
BA_ "Description" SG_ 2273435649 HDA_OptUsmSta "This is HDA system status needed for the cluster USM display.";
BA_ "UserSigValidity" SG_ 2273435649 HDA_OptUsmSta 3;
BA_ "RoutingFactor" SG_ 2273435649 HDA_OptUsmSta 3;
BA_ "Version" SG_ 2273435649 HDA_OptUsmSta "17.12.02";
BA_ "Description" SG_ 2273435649 HDA_CntrlModSta "This is HDA Control Mode needed for longitudinal/lateral control and cluster display.";
BA_ "UserSigValidity" SG_ 2273435649 HDA_CntrlModSta 3;
BA_ "RoutingFactor" SG_ 2273435649 HDA_CntrlModSta 3;
BA_ "Version" SG_ 2273435649 HDA_CntrlModSta "20.05.02";
BA_ "Description" SG_ 2273435649 HDA_InfoPUDis "This is HDA information display needed for the cluster pop-up display.";
BA_ "UserSigValidity" SG_ 2273435649 HDA_InfoPUDis 3;
BA_ "RoutingFactor" SG_ 2273435649 HDA_InfoPUDis 3;
BA_ "Version" SG_ 2273435649 HDA_InfoPUDis "19.03.06";
BA_ "Description" SG_ 2273435649 HDP_AutoCallReqSta "This signal is needed for HDP Auto Call.";
BA_ "UserSigValidity" SG_ 2273435649 HDP_AutoCallReqSta 3;
BA_ "RoutingFactor" SG_ 2273435649 HDP_AutoCallReqSta 3;
BA_ "Version" SG_ 2273435649 HDP_AutoCallReqSta "21.04.03";
BA_ "Description" SG_ 2273435649 HDP_DispBarSta "This signal indicates HDP operation state (always not covered other display)";
BA_ "UserSigValidity" SG_ 2273435649 HDP_DispBarSta 0;
BA_ "RoutingFactor" SG_ 2273435649 HDP_DispBarSta 3;
BA_ "Version" SG_ 2273435649 HDP_DispBarSta "21.03.11";
BA_ "Description" SG_ 2273435649 HDP_OptInfoSta "This signal indicates whether the HDP system has been applied or not.";
BA_ "UserSigValidity" SG_ 2273435649 HDP_OptInfoSta 0;
BA_ "RoutingFactor" SG_ 2273435649 HDP_OptInfoSta 3;
BA_ "Version" SG_ 2273435649 HDP_OptInfoSta "21.03.11";
BA_ "Description" SG_ 2273435649 HDA_LFA_SymSta "This signal shows the state of steering assist.";
BA_ "UserSigValidity" SG_ 2273435649 HDA_LFA_SymSta 3;
BA_ "RoutingFactor" SG_ 2273435649 HDA_LFA_SymSta 3;
BA_ "Version" SG_ 2273435649 HDA_LFA_SymSta "20.11.02";
BA_ "Description" SG_ 2273435649 HDA_LFA_WrnSnd "HDA/LFA Additional Warning Sound";
BA_ "UserSigValidity" SG_ 2273435649 HDA_LFA_WrnSnd 3;
BA_ "RoutingFactor" SG_ 2273435649 HDA_LFA_WrnSnd 3;
BA_ "Version" SG_ 2273435649 HDA_LFA_WrnSnd "18.02.03";
BA_ "Description" SG_ 2273435649 HDA_InfoPUDis1 "This is HDA/LFA information display needed for the cluster pop-up display.";
BA_ "UserSigValidity" SG_ 2273435649 HDA_InfoPUDis1 3;
BA_ "RoutingFactor" SG_ 2273435649 HDA_InfoPUDis1 3;
BA_ "Version" SG_ 2273435649 HDA_InfoPUDis1 "21.01.08";
BA_ "Description" SG_ 2273435649 HDA_TDMRMDclReq "This signal show the state of LFA automatic deactivation.";
BA_ "UserSigValidity" SG_ 2273435649 HDA_TDMRMDclReq 3;
BA_ "RoutingFactor" SG_ 2273435649 HDA_TDMRMDclReq 3;
BA_ "Version" SG_ 2273435649 HDA_TDMRMDclReq "19.02.00";
BA_ "Description" SG_ 2273435649 HDP_ActvSta "This signal indicates control active status of HDP.";
BA_ "UserSigValidity" SG_ 2273435649 HDP_ActvSta 3;
BA_ "RoutingFactor" SG_ 2273435649 HDP_ActvSta 3;
BA_ "Version" SG_ 2273435649 HDP_ActvSta "19.11.02";
BA_ "Description" SG_ 2273435649 HDP_SysSta "This signal indicates system status of HDP.";
BA_ "UserSigValidity" SG_ 2273435649 HDP_SysSta 3;
BA_REL_ "GenSigTimeoutTime" BU_SG_REL_ HOD SG_ 2273435649 HDP_SysSta 1500;
BA_ "RoutingFactor" SG_ 2273435649 HDP_SysSta 3;
BA_ "Version" SG_ 2273435649 HDP_SysSta "20.07.10";
BA_ "Description" SG_ 2273435649 HDP_FailureMode "This signal shows HDP failure status";
BA_ "UserSigValidity" SG_ 2273435649 HDP_FailureMode 3;
BA_ "RoutingFactor" SG_ 2273435649 HDP_FailureMode 3;
BA_ "Version" SG_ 2273435649 HDP_FailureMode "20.07.10";
BA_ "GenMsgSendType" BO_ 2273435650 0;
BA_ "GenMsgCycleTime" BO_ 2273435650 150;
BA_ "GenMsgCycleTimeFast" BO_ 2273435650 0;
BA_ "GenMsgNrOfRepetition" BO_ 2273435650 0;
BA_ "VFrameFormat" BO_ 2273435650 1;
BA_ "Description" SG_ 2273435650 HDP_ObstacleDstVal "This signal indicates distance to a obstacle which is on driving path.";
BA_ "GenSigStartValue" SG_ 2273435650 HDP_ObstacleDstVal 2046;
BA_ "UserSigValidity" SG_ 2273435650 HDP_ObstacleDstVal 3;
BA_ "RoutingFactor" SG_ 2273435650 HDP_ObstacleDstVal 3;
BA_ "Version" SG_ 2273435650 HDP_ObstacleDstVal "19.11.02";
BA_ "Description" SG_ 2273435650 HDP_ObstacleLatPosVal "This signal indicates distance to a obstacle which is on driving path.";
BA_ "GenSigStartValue" SG_ 2273435650 HDP_ObstacleLatPosVal 510;
BA_ "UserSigValidity" SG_ 2273435650 HDP_ObstacleLatPosVal 3;
BA_ "RoutingFactor" SG_ 2273435650 HDP_ObstacleLatPosVal 3;
BA_ "Version" SG_ 2273435650 HDP_ObstacleLatPosVal "19.11.02";
BA_ "Description" SG_ 2273435650 HDP_InfoPUDis "This signal needed for the cluster pop-up display to inform HDP system status and warning.";
BA_ "UserSigValidity" SG_ 2273435650 HDP_InfoPUDis 3;
BA_ "RoutingFactor" SG_ 2273435650 HDP_InfoPUDis 3;
BA_ "Version" SG_ 2273435650 HDP_InfoPUDis "20.09.00";
BA_ "Description" SG_ 2273435650 HDP_WrngTypPUDis "This signal is needed for the cluster mini pop-up display to inform a reason of unavailable/TD activation or warning messages.";
BA_ "UserSigValidity" SG_ 2273435650 HDP_WrngTypPUDis 3;
BA_ "RoutingFactor" SG_ 2273435650 HDP_WrngTypPUDis 3;
BA_ "Version" SG_ 2273435650 HDP_WrngTypPUDis "20.03.01";
BA_ "Description" SG_ 2273435650 HDP_HapticWarnReq "This signal is needed for HDP haptic warning";
BA_ "UserSigValidity" SG_ 2273435650 HDP_HapticWarnReq 3;
BA_REL_ "GenSigTimeoutTime" BU_SG_REL_ PSB SG_ 2273435650 HDP_HapticWarnReq 1500;
BA_ "RoutingFactor" SG_ 2273435650 HDP_HapticWarnReq 3;
BA_ "Version" SG_ 2273435650 HDP_HapticWarnReq "20.03.01";
BA_ "Description" SG_ 2273435650 HDP_ActvStaDis "This signal is needed for the cluster symbol display to inform a activation or deactivation status";
BA_ "UserSigValidity" SG_ 2273435650 HDP_ActvStaDis 3;
BA_ "RoutingFactor" SG_ 2273435650 HDP_ActvStaDis 3;
BA_ "Version" SG_ 2273435650 HDP_ActvStaDis "20.03.01";
BA_ "Description" SG_ 2273435650 HDP_OpStaDisp "This signal is needed for the cluster symbol display to inform highway driving pilot status";
BA_ "UserSigValidity" SG_ 2273435650 HDP_OpStaDisp 3;
BA_ "RoutingFactor" SG_ 2273435650 HDP_OpStaDisp 3;
BA_ "Version" SG_ 2273435650 HDP_OpStaDisp "20.06.01";
BA_ "Description" SG_ 2273435650 HDP_ObstSta "This signal represents the state of in-path obstacle and information of controllable state.

- ÀÚÂ÷¼±»óÀÇ Àü¹æ ÀÏ¹Ý¹°Ã¼ ÀÎ½Ä ¿©ºÎ ¹× Á¦¾î °¡´É »óÅÂ Á¤º¸";
BA_ "UserSigValidity" SG_ 2273435650 HDP_ObstSta 3;
BA_ "RoutingFactor" SG_ 2273435650 HDP_ObstSta 3;
BA_ "Version" SG_ 2273435650 HDP_ObstSta "20.06.01";
BA_ "Description" SG_ 2273435650 HDP_SysFlrDisp "This signal is for pop-up indication of HDP system failure.

If this signal is set to 1, the display device shall indicate HDP failure information to the driver.";
BA_ "UserSigValidity" SG_ 2273435650 HDP_SysFlrDisp 3;
BA_ "RoutingFactor" SG_ 2273435650 HDP_SysFlrDisp 3;
BA_ "Version" SG_ 2273435650 HDP_SysFlrDisp "20.09.00";
BA_ "Description" SG_ 2273435650 HDP_InhbtOffDispSta "This signal is shows that driving safety functions are inhibited while HDP in operation";
BA_ "UserSigValidity" SG_ 2273435650 HDP_InhbtOffDispSta 3;
BA_ "RoutingFactor" SG_ 2273435650 HDP_InhbtOffDispSta 3;
BA_ "Version" SG_ 2273435650 HDP_InhbtOffDispSta "20.12.04";
BA_ "Description" SG_ 2273435650 HDP_CtRoadSrfcDistVal "This signal is notifying how far to display the road surfaces.";
BA_ "GenSigStartValue" SG_ 2273435650 HDP_CtRoadSrfcDistVal 2046;
BA_ "UserSigValidity" SG_ 2273435650 HDP_CtRoadSrfcDistVal 3;
BA_ "RoutingFactor" SG_ 2273435650 HDP_CtRoadSrfcDistVal 3;
BA_ "Version" SG_ 2273435650 HDP_CtRoadSrfcDistVal "21.03.11";
BA_ "Description" SG_ 2273435650 ADAS_DRV_UpDateInfo "ADAS_DRV update state info for AVN";
BA_ "GenSigStartValue" SG_ 2273435650 ADAS_DRV_UpDateInfo 1;
BA_ "UserSigValidity" SG_ 2273435650 ADAS_DRV_UpDateInfo 3;
BA_ "RoutingFactor" SG_ 2273435650 ADAS_DRV_UpDateInfo 3;
BA_ "Version" SG_ 2273435650 ADAS_DRV_UpDateInfo "20.10.02";
BA_ "GenMsgSendType" BO_ 2244046849 0;
BA_ "GenMsgCycleTime" BO_ 2244046849 100;
BA_ "GenMsgCycleTimeFast" BO_ 2244046849 0;
BA_ "GenMsgNrOfRepetition" BO_ 2244046849 0;
BA_ "VFrameFormat" BO_ 2244046849 1;
BA_ "Description" SG_ 2244046849 ADAS_PRK_Crc1Val "The data area for CRC calculation is based on the data length (DLC) of the message DB.

The CRC shall be calculated over the entire data block (excluding the CRC bytes) including the user data, alive counter and Data ID

 

- CRC Polynomial (0x1021) , Initial Value : 0xFFFF, XOR value : 0x0000, Data ID : Message ID + 0xF800 

- The initial value is for CRC calculation and the message should be sent with the calculated result value. 

- The mathematical expression to 16 bit CRC polynomial is given here. G(x) = x16 + x12 + x5 + 1";
BA_ "GenSigStartValue" SG_ 2244046849 ADAS_PRK_Crc1Val 65535;
BA_ "UserSigValidity" SG_ 2244046849 ADAS_PRK_Crc1Val 3;
BA_ "RoutingFactor" SG_ 2244046849 ADAS_PRK_Crc1Val 5;
BA_ "Version" SG_ 2244046849 ADAS_PRK_Crc1Val "18.11.08";
BA_ "Description" SG_ 2244046849 ADAS_PRK_AlvCnt1Val "For the first transmission request for a data element the counter shall be initialized with 0 and shall be incremented by 1 for every subsequent send request. 

When the counter reaches the maximum value(0xFF), then it shall restart with 0 for the next send request";
BA_ "UserSigValidity" SG_ 2244046849 ADAS_PRK_AlvCnt1Val 3;
BA_ "RoutingFactor" SG_ 2244046849 ADAS_PRK_AlvCnt1Val 5;
BA_ "Version" SG_ 2244046849 ADAS_PRK_AlvCnt1Val "18.11.08";
BA_ "Description" SG_ 2244046849 PCA_RrEquipSta "PCA Rear Equipment Status";
BA_ "UserSigValidity" SG_ 2244046849 PCA_RrEquipSta 3;
BA_ "RoutingFactor" SG_ 2244046849 PCA_RrEquipSta 5;
BA_ "Version" SG_ 2244046849 PCA_RrEquipSta "19.10.03";
BA_ "Description" SG_ 2244046849 PCA_SysFlrSta "PCA Failure status";
BA_ "UserSigValidity" SG_ 2244046849 PCA_SysFlrSta 3;
BA_ "RoutingFactor" SG_ 2244046849 PCA_SysFlrSta 5;
BA_ "Version" SG_ 2244046849 PCA_SysFlrSta "21.02.00";
BA_ "Description" SG_ 2244046849 PCA_RrWrngLvlSta "PCA Rear Warning level status";
BA_ "UserSigValidity" SG_ 2244046849 PCA_RrWrngLvlSta 3;
BA_ "RoutingFactor" SG_ 2244046849 PCA_RrWrngLvlSta 5;
BA_ "Version" SG_ 2244046849 PCA_RrWrngLvlSta "19.10.03";
BA_ "Description" SG_ 2244046849 PCA_ModDis "PCA Mode Display";
BA_ "UserSigValidity" SG_ 2244046849 PCA_ModDis 3;
BA_ "RoutingFactor" SG_ 2244046849 PCA_ModDis 5;
BA_ "Version" SG_ 2244046849 PCA_ModDis "20.02.01";
BA_ "Description" SG_ 2244046849 PCA_WrngSndCtSta "Warning sound center status";
BA_ "UserSigValidity" SG_ 2244046849 PCA_WrngSndCtSta 3;
BA_ "RoutingFactor" SG_ 2244046849 PCA_WrngSndCtSta 5;
BA_ "Version" SG_ 2244046849 PCA_WrngSndCtSta "20.01.01";
BA_ "Description" SG_ 2244046849 PCA_WrngSndLtSta "Warning sound left status";
BA_ "UserSigValidity" SG_ 2244046849 PCA_WrngSndLtSta 3;
BA_ "RoutingFactor" SG_ 2244046849 PCA_WrngSndLtSta 5;
BA_ "Version" SG_ 2244046849 PCA_WrngSndLtSta "20.01.01";
BA_ "Description" SG_ 2244046849 PCA_WrngSndRtSta "Warning sound right status";
BA_ "UserSigValidity" SG_ 2244046849 PCA_WrngSndRtSta 3;
BA_ "RoutingFactor" SG_ 2244046849 PCA_WrngSndRtSta 5;
BA_ "Version" SG_ 2244046849 PCA_WrngSndRtSta "17.12.00";
BA_ "Description" SG_ 2244046849 PCA_HptReq "PCA Haptic Request";
BA_ "UserSigValidity" SG_ 2244046849 PCA_HptReq 3;
BA_ "RoutingFactor" SG_ 2244046849 PCA_HptReq 5;
BA_ "Version" SG_ 2244046849 PCA_HptReq "20.02.03";
BA_ "Description" SG_ 2244046849 PCA_BrkReq "Brake request

with EPB : 0x2 PCA Brake on (hold)

without EPB : 0x1 PCA Brake on";
BA_ "UserSigValidity" SG_ 2244046849 PCA_BrkReq 3;
BA_ "RoutingFactor" SG_ 2244046849 PCA_BrkReq 5;
BA_ "Version" SG_ 2244046849 PCA_BrkReq "19.07.06";
BA_ "Description" SG_ 2244046849 PCA_EpbReq "request to hold the vehicle, applying EPB";
BA_ "UserSigValidity" SG_ 2244046849 PCA_EpbReq 3;
BA_ "RoutingFactor" SG_ 2244046849 PCA_EpbReq 5;
BA_ "Version" SG_ 2244046849 PCA_EpbReq "19.07.06";
BA_ "Description" SG_ 2244046849 PCA_DclTrgtVal "Deceleration target value";
BA_ "UserSigValidity" SG_ 2244046849 PCA_DclTrgtVal 3;
BA_ "RoutingFactor" SG_ 2244046849 PCA_DclTrgtVal 5;
BA_ "Version" SG_ 2244046849 PCA_DclTrgtVal "18.07.01";
BA_ "Description" SG_ 2244046849 PCA_DgrSta "Warning timing status";
BA_ "UserSigValidity" SG_ 2244046849 PCA_DgrSta 3;
BA_ "RoutingFactor" SG_ 2244046849 PCA_DgrSta 5;
BA_ "Version" SG_ 2244046849 PCA_DgrSta "17.12.03";
BA_ "Description" SG_ 2244046849 ADAS_PRK_PDW_SysFlrSta "PDW Failure Status";
BA_ "UserSigValidity" SG_ 2244046849 ADAS_PRK_PDW_SysFlrSta 3;
BA_ "RoutingFactor" SG_ 2244046849 ADAS_PRK_PDW_SysFlrSta 5;
BA_ "Version" SG_ 2244046849 ADAS_PRK_PDW_SysFlrSta "20.11.02";
BA_ "GenMsgSendType" BO_ 2244046850 0;
BA_ "GenMsgCycleTime" BO_ 2244046850 100;
BA_ "GenMsgCycleTimeFast" BO_ 2244046850 0;
BA_ "GenMsgNrOfRepetition" BO_ 2244046850 0;
BA_ "VFrameFormat" BO_ 2244046850 1;
BA_ "Description" SG_ 2244046850 ADAS_PRK_PDW_SwIndOnReq "-PDW Switch Indicator On/Off Request

This signal is used for PDW-R and PDW-F/R";
BA_ "UserSigValidity" SG_ 2244046850 ADAS_PRK_PDW_SwIndOnReq 3;
BA_REL_ "GenSigTimeoutTime" BU_SG_REL_ FCS SG_ 2244046850 ADAS_PRK_PDW_SwIndOnReq 1500;
BA_ "RoutingFactor" SG_ 2244046850 ADAS_PRK_PDW_SwIndOnReq 5;
BA_ "Version" SG_ 2244046850 ADAS_PRK_PDW_SwIndOnReq "18.05.02";
BA_ "Description" SG_ 2244046850 PCA_RrEquipChkSta "PCA Rear Equipment Check Status";
BA_ "UserSigValidity" SG_ 2244046850 PCA_RrEquipChkSta 3;
BA_ "RoutingFactor" SG_ 2244046850 PCA_RrEquipChkSta 5;
BA_ "Version" SG_ 2244046850 PCA_RrEquipChkSta "20.05.02";
BA_ "Description" SG_ 2244046850 PCA_FrWrngLvlSta "PCA Front warning level status";
BA_ "UserSigValidity" SG_ 2244046850 PCA_FrWrngLvlSta 3;
BA_ "RoutingFactor" SG_ 2244046850 PCA_FrWrngLvlSta 5;
BA_ "Version" SG_ 2244046850 PCA_FrWrngLvlSta "19.10.03";
BA_ "Description" SG_ 2244046850 PCA_LtWrngLvlSta "PCA Left warning level status";
BA_ "UserSigValidity" SG_ 2244046850 PCA_LtWrngLvlSta 3;
BA_ "RoutingFactor" SG_ 2244046850 PCA_LtWrngLvlSta 5;
BA_ "Version" SG_ 2244046850 PCA_LtWrngLvlSta "20.01.01";
BA_ "Description" SG_ 2244046850 ADAS_PRK_PDW_OptTyp "this signal means PDW Option (Non, PDW-R, PDW-FR, PDW-FSR)";
BA_ "UserSigValidity" SG_ 2244046850 ADAS_PRK_PDW_OptTyp 3;
BA_ "RoutingFactor" SG_ 2244046850 ADAS_PRK_PDW_OptTyp 5;
BA_ "Version" SG_ 2244046850 ADAS_PRK_PDW_OptTyp "20.11.02";
BA_ "Description" SG_ 2244046850 PCA_RtWrngLvlSta "PCA Right warning level status";
BA_ "UserSigValidity" SG_ 2244046850 PCA_RtWrngLvlSta 3;
BA_ "RoutingFactor" SG_ 2244046850 PCA_RtWrngLvlSta 5;
BA_ "Version" SG_ 2244046850 PCA_RtWrngLvlSta "19.08.08";
BA_ "Description" SG_ 2244046850 PCA_RrFlrDis "PCA Rear Failure Display";
BA_ "UserSigValidity" SG_ 2244046850 PCA_RrFlrDis 3;
BA_ "RoutingFactor" SG_ 2244046850 PCA_RrFlrDis 5;
BA_ "Version" SG_ 2244046850 PCA_RrFlrDis "19.10.04";
BA_ "Description" SG_ 2244046850 PCA_FrFlrDis "PCA Front Failure Display";
BA_ "UserSigValidity" SG_ 2244046850 PCA_FrFlrDis 3;
BA_ "RoutingFactor" SG_ 2244046850 PCA_FrFlrDis 5;
BA_ "Version" SG_ 2244046850 PCA_FrFlrDis "19.10.04";
BA_ "Description" SG_ 2244046850 PCA_LtFlrDis "PCA Left Failure Display";
BA_ "UserSigValidity" SG_ 2244046850 PCA_LtFlrDis 3;
BA_ "RoutingFactor" SG_ 2244046850 PCA_LtFlrDis 5;
BA_ "Version" SG_ 2244046850 PCA_LtFlrDis "20.01.01";
BA_ "Description" SG_ 2244046850 PCA_RtFlrDis "PCA Right Failure Display";
BA_ "UserSigValidity" SG_ 2244046850 PCA_RtFlrDis 3;
BA_ "RoutingFactor" SG_ 2244046850 PCA_RtFlrDis 5;
BA_ "Version" SG_ 2244046850 PCA_RtFlrDis "19.10.04";
BA_ "UserSigValidity" SG_ 2244046850 PCA_FrBndryLn 3;
BA_ "RoutingFactor" SG_ 2244046850 PCA_FrBndryLn 5;
BA_ "Version" SG_ 2244046850 PCA_FrBndryLn "21.04.09";
BA_ "UserSigValidity" SG_ 2244046850 PCA_RrBndryLn 3;
BA_ "RoutingFactor" SG_ 2244046850 PCA_RrBndryLn 5;
BA_ "Version" SG_ 2244046850 PCA_RrBndryLn "21.04.09";
BA_ "UserSigValidity" SG_ 2244046850 PCA_LtBndryLn 3;
BA_ "RoutingFactor" SG_ 2244046850 PCA_LtBndryLn 5;
BA_ "Version" SG_ 2244046850 PCA_LtBndryLn "21.04.09";
BA_ "UserSigValidity" SG_ 2244046850 PCA_RtBndryLn 3;
BA_ "RoutingFactor" SG_ 2244046850 PCA_RtBndryLn 5;
BA_ "Version" SG_ 2244046850 PCA_RtBndryLn "21.04.09";
BA_ "UserSigValidity" SG_ 2244046850 PCA_WrngPhrs 3;
BA_ "RoutingFactor" SG_ 2244046850 PCA_WrngPhrs 5;
BA_ "Version" SG_ 2244046850 PCA_WrngPhrs "21.04.09";
BA_ "Description" SG_ 2244046850 ADAS_PRK_PDW_AutoOn_USM "PDW system automatically on/off setting status";
BA_ "UserSigValidity" SG_ 2244046850 ADAS_PRK_PDW_AutoOn_USM 3;
BA_ "RoutingFactor" SG_ 2244046850 ADAS_PRK_PDW_AutoOn_USM 5;
BA_ "Version" SG_ 2244046850 ADAS_PRK_PDW_AutoOn_USM "18.05.02";
BA_ "Description" SG_ 2244046850 PCA_FrSdEquipChkSta "PCA Front Side Equipment Check Status";
BA_ "UserSigValidity" SG_ 2244046850 PCA_FrSdEquipChkSta 3;
BA_ "RoutingFactor" SG_ 2244046850 PCA_FrSdEquipChkSta 5;
BA_ "Version" SG_ 2244046850 PCA_FrSdEquipChkSta "20.05.02";
BA_ "GenMsgSendType" BO_ 1030 0;
BA_ "Description" SG_ 1030 APSM_SWVerMajor1 "Indicate the SCM software version as follows:

- The software version is displayed in three digits.

- The Major and Minor digits are separated by '.'

- Signal values are transmitted to ASCII codes.



¡Ø Example

APSM_SWVerMajor1 : 0x41 (HEX) -> ASCII CODE : 'A' 

APSM_SWVerMinor1 : 0x30 (HEX) -> ASCII CODE : '0'

APSM_SWVerMinor2 : 0x33 (HEX) -> ASCII CODE : '3'

=> APSM S/W Ver is displayed 'A.03'";
BA_ "GenSigSendType" SG_ 1030 APSM_SWVerMajor1 4;
BA_ "UserSigValidity" SG_ 1030 APSM_SWVerMajor1 0;
BA_REL_ "GenSigTimeoutTime" BU_SG_REL_ CGW_CCU SG_ 1030 APSM_SWVerMajor1 1500;
BA_ "Version" SG_ 1030 APSM_SWVerMajor1 "21.07.00";
BA_ "Description" SG_ 1030 APSM_SWVerMinor1 "Indicate the APSM software version as follows:

- The software version is displayed in three digits.

- The Major and Minor digits are separated by '.'

- Signal values are transmitted to ASCII codes.



¡Ø Example

APSM_SWVerMajor1 : 0x41 (HEX) -> ASCII CODE : 'A' 

APSM_SWVerMinor1 : 0x30 (HEX) -> ASCII CODE : '0'

APSM_SWVerMinor2 : 0x33 (HEX) -> ASCII CODE : '3'

=> APSM S/W Ver is displayed 'A.03'";
BA_ "GenSigSendType" SG_ 1030 APSM_SWVerMinor1 4;
BA_ "UserSigValidity" SG_ 1030 APSM_SWVerMinor1 0;
BA_REL_ "GenSigTimeoutTime" BU_SG_REL_ CGW_CCU SG_ 1030 APSM_SWVerMinor1 1500;
BA_ "Version" SG_ 1030 APSM_SWVerMinor1 "18.10.06";
BA_ "Description" SG_ 1030 APSM_SWVerMinor2 "Indicate the APSM software version as follows:

- The software version is displayed in three digits.

- The Major and Minor digits are separated by '.'

- Signal values are transmitted to ASCII codes.



¡Ø Example

APSM_SWVerMajor1 : 0x41 (HEX) -> ASCII CODE : 'A' 

APSM_SWVerMinor1 : 0x30 (HEX) -> ASCII CODE : '0'

APSM_SWVerMinor2 : 0x33 (HEX) -> ASCII CODE : '3'

=> APSM S/W Ver is displayed 'A.03'";
BA_ "GenSigSendType" SG_ 1030 APSM_SWVerMinor2 4;
BA_ "UserSigValidity" SG_ 1030 APSM_SWVerMinor2 0;
BA_REL_ "GenSigTimeoutTime" BU_SG_REL_ CGW_CCU SG_ 1030 APSM_SWVerMinor2 1500;
BA_ "Version" SG_ 1030 APSM_SWVerMinor2 "18.10.06";
BA_ "GenMsgSendType" BO_ 1031 0;
BA_ "GenSigSendType" SG_ 1031 APSM_AstStEsyAcsUSMSta 4;
BA_ "UserSigValidity" SG_ 1031 APSM_AstStEsyAcsUSMSta 0;
BA_REL_ "GenSigTimeoutTime" BU_SG_REL_ CGW_CCU SG_ 1031 APSM_AstStEsyAcsUSMSta 1500;
BA_ "NetworkRequest" SG_ 1031 APSM_AstStEsyAcsUSMSta 0;
BA_ "NetworkRequestHoldingTime" SG_ 1031 APSM_AstStEsyAcsUSMSta 5000;
BA_ "Version" SG_ 1031 APSM_AstStEsyAcsUSMSta "19.08.08";
BA_ "Description" SG_ 1031 APSM_WalkInEnable "Apsm Walk In Mode Enable/Disable";
BA_ "GenSigSendType" SG_ 1031 APSM_WalkInEnable 4;
BA_ "UserSigValidity" SG_ 1031 APSM_WalkInEnable 0;
BA_ "NetworkRequest" SG_ 1031 APSM_WalkInEnable 0;
BA_ "NetworkRequestHoldingTime" SG_ 1031 APSM_WalkInEnable 5000;
BA_ "Version" SG_ 1031 APSM_WalkInEnable "19.07.06";
BA_ "GenSigSendType" SG_ 1031 APSM_LimSetSta 4;
BA_ "UserSigValidity" SG_ 1031 APSM_LimSetSta 0;
BA_ "NetworkRequest" SG_ 1031 APSM_LimSetSta 0;
BA_ "NetworkRequestHoldingTime" SG_ 1031 APSM_LimSetSta 5000;
BA_ "Version" SG_ 1031 APSM_LimSetSta "21.04.01";
BA_ "Description" SG_ 1031 APSM_FootRest_Opt "Foot Rest OPTION";
BA_ "GenSigSendType" SG_ 1031 APSM_FootRest_Opt 4;
BA_ "UserSigValidity" SG_ 1031 APSM_FootRest_Opt 0;
BA_ "NetworkRequest" SG_ 1031 APSM_FootRest_Opt 0;
BA_ "NetworkRequestHoldingTime" SG_ 1031 APSM_FootRest_Opt 5000;
BA_ "Version" SG_ 1031 APSM_FootRest_Opt "19.11.05";
BA_ "Description" SG_ 1031 APSM_RSE_Opt "RSE OPTION";
BA_ "GenSigSendType" SG_ 1031 APSM_RSE_Opt 4;
BA_ "UserSigValidity" SG_ 1031 APSM_RSE_Opt 0;
BA_ "NetworkRequest" SG_ 1031 APSM_RSE_Opt 0;
BA_ "NetworkRequestHoldingTime" SG_ 1031 APSM_RSE_Opt 5000;
BA_ "Version" SG_ 1031 APSM_RSE_Opt "20.07.11";
BA_ "GenMsgSendType" BO_ 527 0;
BA_ "Description" SG_ 527 ATS_DrvStRseFwdBtn "¿îÀü¼® ¸ð´ÏÅÍ °¢µµ Á¶Àý Àü¹æ ÀÌµ¿";
BA_ "GenSigSendType" SG_ 527 ATS_DrvStRseFwdBtn 4;
BA_ "UserSigValidity" SG_ 527 ATS_DrvStRseFwdBtn 3;
BA_ "NetworkRequest" SG_ 527 ATS_DrvStRseFwdBtn 0;
BA_ "NetworkRequestHoldingTime" SG_ 527 ATS_DrvStRseFwdBtn 5000;
BA_ "Version" SG_ 527 ATS_DrvStRseFwdBtn "19.09.02";
BA_ "Description" SG_ 527 ATS_DrvStRseBwdBtn "¿îÀü¼® ¸ð´ÏÅÍ °¢µµ Á¶Àý ÈÄ¹æ ÀÌµ¿";
BA_ "GenSigSendType" SG_ 527 ATS_DrvStRseBwdBtn 4;
BA_ "UserSigValidity" SG_ 527 ATS_DrvStRseBwdBtn 3;
BA_ "NetworkRequest" SG_ 527 ATS_DrvStRseBwdBtn 0;
BA_ "NetworkRequestHoldingTime" SG_ 527 ATS_DrvStRseBwdBtn 5000;
BA_ "Version" SG_ 527 ATS_DrvStRseBwdBtn "19.09.02";
BA_ "Description" SG_ 527 ATS_RRRestModBtn "ÈÄ¼® RH REST ¸ðµå ÀÛµ¿";
BA_ "GenSigSendType" SG_ 527 ATS_RRRestModBtn 4;
BA_ "UserSigValidity" SG_ 527 ATS_RRRestModBtn 3;
BA_ "NetworkRequest" SG_ 527 ATS_RRRestModBtn 0;
BA_ "NetworkRequestHoldingTime" SG_ 527 ATS_RRRestModBtn 5000;
BA_ "Version" SG_ 527 ATS_RRRestModBtn "19.09.02";
BA_ "Description" SG_ 527 ATS_RRResetModBtn "ÈÄ¼® RH RETURN ¸ðµå ÀÛµ¿";
BA_ "GenSigSendType" SG_ 527 ATS_RRResetModBtn 4;
BA_ "UserSigValidity" SG_ 527 ATS_RRResetModBtn 3;
BA_ "NetworkRequest" SG_ 527 ATS_RRResetModBtn 0;
BA_ "NetworkRequestHoldingTime" SG_ 527 ATS_RRResetModBtn 5000;
BA_ "Version" SG_ 527 ATS_RRResetModBtn "19.09.02";
BA_ "Description" SG_ 527 ATS_RRAvWtcModBtn "ÈÄ¼® RH AVN ¸ðµå ÀÛµ¿";
BA_ "GenSigSendType" SG_ 527 ATS_RRAvWtcModBtn 4;
BA_ "UserSigValidity" SG_ 527 ATS_RRAvWtcModBtn 3;
BA_ "NetworkRequest" SG_ 527 ATS_RRAvWtcModBtn 0;
BA_ "NetworkRequestHoldingTime" SG_ 527 ATS_RRAvWtcModBtn 5000;
BA_ "Version" SG_ 527 ATS_RRAvWtcModBtn "19.09.02";
BA_ "Description" SG_ 527 ATS_RRReadingModBtn "ÈÄ¼® RH READING ¸ðµå ÀÛµ¿";
BA_ "GenSigSendType" SG_ 527 ATS_RRReadingModBtn 4;
BA_ "UserSigValidity" SG_ 527 ATS_RRReadingModBtn 3;
BA_ "NetworkRequest" SG_ 527 ATS_RRReadingModBtn 0;
BA_ "NetworkRequestHoldingTime" SG_ 527 ATS_RRReadingModBtn 5000;
BA_ "Version" SG_ 527 ATS_RRReadingModBtn "19.09.02";
BA_ "Description" SG_ 527 ATS_RLRestModBtn "ÈÄ¼® LH REST ¸ðµå ÀÛµ¿";
BA_ "GenSigSendType" SG_ 527 ATS_RLRestModBtn 4;
BA_ "UserSigValidity" SG_ 527 ATS_RLRestModBtn 3;
BA_ "NetworkRequest" SG_ 527 ATS_RLRestModBtn 0;
BA_ "NetworkRequestHoldingTime" SG_ 527 ATS_RLRestModBtn 5000;
BA_ "Version" SG_ 527 ATS_RLRestModBtn "19.09.02";
BA_ "Description" SG_ 527 ATS_RLResetModBtn "ÈÄ¼® LH RETURN ¸ðµå ÀÛµ¿";
BA_ "GenSigSendType" SG_ 527 ATS_RLResetModBtn 4;
BA_ "UserSigValidity" SG_ 527 ATS_RLResetModBtn 3;
BA_ "NetworkRequest" SG_ 527 ATS_RLResetModBtn 0;
BA_ "NetworkRequestHoldingTime" SG_ 527 ATS_RLResetModBtn 5000;
BA_ "Version" SG_ 527 ATS_RLResetModBtn "19.09.02";
BA_ "GenMsgSendType" BO_ 543 0;
BA_ "Description" SG_ 543 ATS_AstStSldFwdBtn "µ¿½Â¼® ½½¶óÀÌµù Àü¹æ ÀÌµ¿ (¿öÅ©ÀÎ ÀÛµ¿)";
BA_ "GenSigSendType" SG_ 543 ATS_AstStSldFwdBtn 4;
BA_ "UserSigValidity" SG_ 543 ATS_AstStSldFwdBtn 3;
BA_ "NetworkRequest" SG_ 543 ATS_AstStSldFwdBtn 0;
BA_ "NetworkRequestHoldingTime" SG_ 543 ATS_AstStSldFwdBtn 5000;
BA_ "Version" SG_ 543 ATS_AstStSldFwdBtn "19.09.02";
BA_ "Description" SG_ 543 ATS_AstStSldBwdBtn "µ¿½Â¼® ½½¶óÀÌµù ÈÄ¹æ ÀÌµ¿ (¿öÅ©ÀÎ ÀÛµ¿)";
BA_ "GenSigSendType" SG_ 543 ATS_AstStSldBwdBtn 4;
BA_ "UserSigValidity" SG_ 543 ATS_AstStSldBwdBtn 3;
BA_ "NetworkRequest" SG_ 543 ATS_AstStSldBwdBtn 0;
BA_ "NetworkRequestHoldingTime" SG_ 543 ATS_AstStSldBwdBtn 5000;
BA_ "Version" SG_ 543 ATS_AstStSldBwdBtn "19.09.02";
BA_ "Description" SG_ 543 ATS_AstStRclFwdBtn "µ¿½Â¼® ¸®Å¬¶óÀÌ´× Àü¹æ ÀÌµ¿ (¿öÅ©ÀÎ ÀÛµ¿)";
BA_ "GenSigSendType" SG_ 543 ATS_AstStRclFwdBtn 4;
BA_ "UserSigValidity" SG_ 543 ATS_AstStRclFwdBtn 3;
BA_ "NetworkRequest" SG_ 543 ATS_AstStRclFwdBtn 0;
BA_ "NetworkRequestHoldingTime" SG_ 543 ATS_AstStRclFwdBtn 5000;
BA_ "Version" SG_ 543 ATS_AstStRclFwdBtn "19.09.02";
BA_ "Description" SG_ 543 ATS_AstStRclBwdBtn "µ¿½Â¼® ¸®Å¬¶óÀÌ´× ÈÄ¹æ ÀÌµ¿ (¿öÅ©ÀÎ ÀÛµ¿)";
BA_ "GenSigSendType" SG_ 543 ATS_AstStRclBwdBtn 4;
BA_ "UserSigValidity" SG_ 543 ATS_AstStRclBwdBtn 3;
BA_ "NetworkRequest" SG_ 543 ATS_AstStRclBwdBtn 0;
BA_ "NetworkRequestHoldingTime" SG_ 543 ATS_AstStRclBwdBtn 5000;
BA_ "Version" SG_ 543 ATS_AstStRclBwdBtn "19.09.02";
BA_ "Description" SG_ 543 ATS_AstStHgtUpBtn "µ¿½Â¼® ÇÏÀÌÆ® ¾÷ ÀÌµ¿ (¿öÅ©ÀÎ ÀÛµ¿)";
BA_ "GenSigSendType" SG_ 543 ATS_AstStHgtUpBtn 4;
BA_ "UserSigValidity" SG_ 543 ATS_AstStHgtUpBtn 3;
BA_ "NetworkRequest" SG_ 543 ATS_AstStHgtUpBtn 0;
BA_ "NetworkRequestHoldingTime" SG_ 543 ATS_AstStHgtUpBtn 5000;
BA_ "Version" SG_ 543 ATS_AstStHgtUpBtn "19.09.02";
BA_ "Description" SG_ 543 ATS_AstStHgtDnBtn "µ¿½Â¼® ÇÏÀÌÆ® ´Ù¿î ÀÌµ¿ (¿öÅ©ÀÎ ÀÛµ¿)";
BA_ "GenSigSendType" SG_ 543 ATS_AstStHgtDnBtn 4;
BA_ "UserSigValidity" SG_ 543 ATS_AstStHgtDnBtn 3;
BA_ "NetworkRequest" SG_ 543 ATS_AstStHgtDnBtn 0;
BA_ "NetworkRequestHoldingTime" SG_ 543 ATS_AstStHgtDnBtn 5000;
BA_ "Version" SG_ 543 ATS_AstStHgtDnBtn "19.09.02";
BA_ "Description" SG_ 543 ATS_AstStHRestUpBtn "µ¿½Â¼® Çìµå·¹½ºÆ® ¾÷ ÀÌµ¿ (¿öÅ©ÀÎ ÀÛµ¿)";
BA_ "GenSigSendType" SG_ 543 ATS_AstStHRestUpBtn 4;
BA_ "UserSigValidity" SG_ 543 ATS_AstStHRestUpBtn 3;
BA_ "NetworkRequest" SG_ 543 ATS_AstStHRestUpBtn 0;
BA_ "NetworkRequestHoldingTime" SG_ 543 ATS_AstStHRestUpBtn 5000;
BA_ "Version" SG_ 543 ATS_AstStHRestUpBtn "19.09.02";
BA_ "Description" SG_ 543 ATS_AstStHRestDnBtn "µ¿½Â¼® Çìµå·¹½ºÆ® ´Ù¿î ÀÌµ¿ (¿öÅ©ÀÎ ÀÛµ¿)";
BA_ "GenSigSendType" SG_ 543 ATS_AstStHRestDnBtn 4;
BA_ "UserSigValidity" SG_ 543 ATS_AstStHRestDnBtn 3;
BA_ "NetworkRequest" SG_ 543 ATS_AstStHRestDnBtn 0;
BA_ "NetworkRequestHoldingTime" SG_ 543 ATS_AstStHRestDnBtn 5000;
BA_ "Version" SG_ 543 ATS_AstStHRestDnBtn "19.09.02";
BA_ "Description" SG_ 543 ATS_AstStHRestFwdBtn "µ¿½Â¼® Çìµå·¹½ºÆ® Àü¹æ ÀÌµ¿ (¿öÅ©ÀÎ ÀÛµ¿)";
BA_ "GenSigSendType" SG_ 543 ATS_AstStHRestFwdBtn 4;
BA_ "UserSigValidity" SG_ 543 ATS_AstStHRestFwdBtn 3;
BA_ "NetworkRequest" SG_ 543 ATS_AstStHRestFwdBtn 0;
BA_ "NetworkRequestHoldingTime" SG_ 543 ATS_AstStHRestFwdBtn 5000;
BA_ "Version" SG_ 543 ATS_AstStHRestFwdBtn "19.09.02";
BA_ "Description" SG_ 543 ATS_AstStHRestBwdBtn "µ¿½Â¼® Çìµå·¹½ºÆ® ÈÄ¹æ ÀÌµ¿ (¿öÅ©ÀÎ ÀÛµ¿)";
BA_ "GenSigSendType" SG_ 543 ATS_AstStHRestBwdBtn 4;
BA_ "UserSigValidity" SG_ 543 ATS_AstStHRestBwdBtn 3;
BA_ "NetworkRequest" SG_ 543 ATS_AstStHRestBwdBtn 0;
BA_ "NetworkRequestHoldingTime" SG_ 543 ATS_AstStHRestBwdBtn 5000;
BA_ "Version" SG_ 543 ATS_AstStHRestBwdBtn "19.09.02";
BA_ "Description" SG_ 543 ATS_AstStHRestFldBtn "µ¿½Â¼® Çìµå·¹½ºÆ® Æúµù ÀÌµ¿ (¿öÅ©ÀÎ ÀÛµ¿)";
BA_ "GenSigSendType" SG_ 543 ATS_AstStHRestFldBtn 4;
BA_ "UserSigValidity" SG_ 543 ATS_AstStHRestFldBtn 3;
BA_ "NetworkRequest" SG_ 543 ATS_AstStHRestFldBtn 0;
BA_ "NetworkRequestHoldingTime" SG_ 543 ATS_AstStHRestFldBtn 5000;
BA_ "Version" SG_ 543 ATS_AstStHRestFldBtn "19.09.02";
BA_ "Description" SG_ 543 ATS_AstStHRestUnFldBtn "µ¿½Â¼® Çìµå·¹½ºÆ® ¾ðÆúµù ÀÌµ¿ (¿öÅ©ÀÎ ÀÛµ¿)";
BA_ "GenSigSendType" SG_ 543 ATS_AstStHRestUnFldBtn 4;
BA_ "UserSigValidity" SG_ 543 ATS_AstStHRestUnFldBtn 3;
BA_ "NetworkRequest" SG_ 543 ATS_AstStHRestUnFldBtn 0;
BA_ "NetworkRequestHoldingTime" SG_ 543 ATS_AstStHRestUnFldBtn 5000;
BA_ "Version" SG_ 543 ATS_AstStHRestUnFldBtn "19.09.02";
BA_ "Description" SG_ 543 ATS_AstStRseFwdBtn "µ¿½Â¼® ¸ð´ÏÅÍ °¢µµ Á¶Àý Àü¹æ ÀÌµ¿";
BA_ "GenSigSendType" SG_ 543 ATS_AstStRseFwdBtn 4;
BA_ "UserSigValidity" SG_ 543 ATS_AstStRseFwdBtn 3;
BA_ "NetworkRequest" SG_ 543 ATS_AstStRseFwdBtn 0;
BA_ "NetworkRequestHoldingTime" SG_ 543 ATS_AstStRseFwdBtn 5000;
BA_ "Version" SG_ 543 ATS_AstStRseFwdBtn "19.09.02";
BA_ "Description" SG_ 543 ATS_AstStRseBwdBtn "µ¿½Â¼® ¸ð´ÏÅÍ °¢µµ Á¶Àý ÈÄ¹æ ÀÌµ¿";
BA_ "GenSigSendType" SG_ 543 ATS_AstStRseBwdBtn 4;
BA_ "UserSigValidity" SG_ 543 ATS_AstStRseBwdBtn 3;
BA_ "NetworkRequest" SG_ 543 ATS_AstStRseBwdBtn 0;
BA_ "NetworkRequestHoldingTime" SG_ 543 ATS_AstStRseBwdBtn 5000;
BA_ "Version" SG_ 543 ATS_AstStRseBwdBtn "19.09.02";
BA_ "Description" SG_ 543 ATS_AstStFRestFldBtn "µ¿½Â¼® Ç²·¹½ºÆ® Æúµù ÀÌµ¿ (¿öÅ©ÀÎ ÀÛµ¿)";
BA_ "GenSigSendType" SG_ 543 ATS_AstStFRestFldBtn 4;
BA_ "UserSigValidity" SG_ 543 ATS_AstStFRestFldBtn 3;
BA_ "NetworkRequest" SG_ 543 ATS_AstStFRestFldBtn 0;
BA_ "NetworkRequestHoldingTime" SG_ 543 ATS_AstStFRestFldBtn 5000;
BA_ "Version" SG_ 543 ATS_AstStFRestFldBtn "19.09.02";
BA_ "Description" SG_ 543 ATS_AstStFRestUnFldBtn "µ¿½Â¼® Ç²·¹½ºÆ® ¾ðÆúµù ÀÌµ¿ (¿öÅ©ÀÎ ÀÛµ¿)";
BA_ "GenSigSendType" SG_ 543 ATS_AstStFRestUnFldBtn 4;
BA_ "UserSigValidity" SG_ 543 ATS_AstStFRestUnFldBtn 3;
BA_ "NetworkRequest" SG_ 543 ATS_AstStFRestUnFldBtn 0;
BA_ "NetworkRequestHoldingTime" SG_ 543 ATS_AstStFRestUnFldBtn 5000;
BA_ "Version" SG_ 543 ATS_AstStFRestUnFldBtn "19.09.02";
BA_ "Description" SG_ 543 ATS_AstTltUpBtn "µ¿½Â¼® Æ¿Æ® UP ÀÌµ¿ (¿öÅ©ÀÎ ÀÛµ¿)";
BA_ "GenSigSendType" SG_ 543 ATS_AstTltUpBtn 4;
BA_ "UserSigValidity" SG_ 543 ATS_AstTltUpBtn 3;
BA_ "NetworkRequest" SG_ 543 ATS_AstTltUpBtn 0;
BA_ "NetworkRequestHoldingTime" SG_ 543 ATS_AstTltUpBtn 5000;
BA_ "Version" SG_ 543 ATS_AstTltUpBtn "19.12.00";
BA_ "Description" SG_ 543 ATS_AstTltDnBtn "µ¿½Â¼® Æ¿Æ® DOWN ÀÌµ¿ (¿öÅ©ÀÎ ÀÛµ¿)";
BA_ "GenSigSendType" SG_ 543 ATS_AstTltDnBtn 4;
BA_ "UserSigValidity" SG_ 543 ATS_AstTltDnBtn 3;
BA_ "NetworkRequest" SG_ 543 ATS_AstTltDnBtn 0;
BA_ "NetworkRequestHoldingTime" SG_ 543 ATS_AstTltDnBtn 5000;
BA_ "Version" SG_ 543 ATS_AstTltDnBtn "19.12.00";
BA_ "GenMsgSendType" BO_ 623 0;
BA_ "Description" SG_ 623 ATS_ARSOpenCloseStatus "ÈÄ¼® ¾Ï·¹½ºÆ® ¿­¸²/´ÝÈû »óÅÂ ½ÅÈ£";
BA_ "GenSigSendType" SG_ 623 ATS_ARSOpenCloseStatus 4;
BA_ "UserSigValidity" SG_ 623 ATS_ARSOpenCloseStatus 3;
BA_ "NetworkRequest" SG_ 623 ATS_ARSOpenCloseStatus 0;
BA_ "NetworkRequestHoldingTime" SG_ 623 ATS_ARSOpenCloseStatus 5000;
BA_ "Version" SG_ 623 ATS_ARSOpenCloseStatus "20.12.05";
BA_ "Description" SG_ 623 ATS_RLLumbarDefBtn "ÈÄ¼® LH ·³¹ö ¹è±â ÀÛµ¿";
BA_ "GenSigSendType" SG_ 623 ATS_RLLumbarDefBtn 4;
BA_ "UserSigValidity" SG_ 623 ATS_RLLumbarDefBtn 3;
BA_ "NetworkRequest" SG_ 623 ATS_RLLumbarDefBtn 0;
BA_ "NetworkRequestHoldingTime" SG_ 623 ATS_RLLumbarDefBtn 5000;
BA_ "Version" SG_ 623 ATS_RLLumbarDefBtn "19.09.02";
BA_ "Description" SG_ 623 ATS_RLLumbarLowBtn "ÈÄ¼® LH ·³¹ö LOW ÀÛµ¿";
BA_ "GenSigSendType" SG_ 623 ATS_RLLumbarLowBtn 4;
BA_ "UserSigValidity" SG_ 623 ATS_RLLumbarLowBtn 3;
BA_ "NetworkRequest" SG_ 623 ATS_RLLumbarLowBtn 0;
BA_ "NetworkRequestHoldingTime" SG_ 623 ATS_RLLumbarLowBtn 5000;
BA_ "Version" SG_ 623 ATS_RLLumbarLowBtn "19.09.02";
BA_ "Description" SG_ 623 ATS_RLLumbarMidBtn "ÈÄ¼® LH ·³¹ö MID ÀÛµ¿";
BA_ "GenSigSendType" SG_ 623 ATS_RLLumbarMidBtn 4;
BA_ "UserSigValidity" SG_ 623 ATS_RLLumbarMidBtn 3;
BA_ "NetworkRequest" SG_ 623 ATS_RLLumbarMidBtn 0;
BA_ "NetworkRequestHoldingTime" SG_ 623 ATS_RLLumbarMidBtn 5000;
BA_ "Version" SG_ 623 ATS_RLLumbarMidBtn "19.09.02";
BA_ "Description" SG_ 623 ATS_RLLumbarUpBtn "ÈÄ¼® LH ·³¹ö UP ÀÛµ¿";
BA_ "GenSigSendType" SG_ 623 ATS_RLLumbarUpBtn 4;
BA_ "UserSigValidity" SG_ 623 ATS_RLLumbarUpBtn 3;
BA_ "NetworkRequest" SG_ 623 ATS_RLLumbarUpBtn 0;
BA_ "NetworkRequestHoldingTime" SG_ 623 ATS_RLLumbarUpBtn 5000;
BA_ "Version" SG_ 623 ATS_RLLumbarUpBtn "19.09.02";
BA_ "Description" SG_ 623 ATS_RLBolsterDefBtn "ÈÄ¼® LH º¼½ºÅÍ ¹è±â ÀÛµ¿";
BA_ "GenSigSendType" SG_ 623 ATS_RLBolsterDefBtn 4;
BA_ "UserSigValidity" SG_ 623 ATS_RLBolsterDefBtn 3;
BA_ "NetworkRequest" SG_ 623 ATS_RLBolsterDefBtn 0;
BA_ "NetworkRequestHoldingTime" SG_ 623 ATS_RLBolsterDefBtn 5000;
BA_ "Version" SG_ 623 ATS_RLBolsterDefBtn "19.09.02";
BA_ "Description" SG_ 623 ATS_RLBolsterInfSw "ÈÄ¼® LH º¼½ºÅÍ Èí±â ÀÛµ¿";
BA_ "GenSigSendType" SG_ 623 ATS_RLBolsterInfSw 4;
BA_ "UserSigValidity" SG_ 623 ATS_RLBolsterInfSw 3;
BA_ "NetworkRequest" SG_ 623 ATS_RLBolsterInfSw 0;
BA_ "NetworkRequestHoldingTime" SG_ 623 ATS_RLBolsterInfSw 5000;
BA_ "Version" SG_ 623 ATS_RLBolsterInfSw "19.09.02";
BA_ "Description" SG_ 623 ATS_RRLumbarDefBtn "ÈÄ¼® LH ·³¹ö ¹è±â ÀÛµ¿";
BA_ "GenSigSendType" SG_ 623 ATS_RRLumbarDefBtn 4;
BA_ "UserSigValidity" SG_ 623 ATS_RRLumbarDefBtn 3;
BA_ "NetworkRequest" SG_ 623 ATS_RRLumbarDefBtn 0;
BA_ "NetworkRequestHoldingTime" SG_ 623 ATS_RRLumbarDefBtn 5000;
BA_ "Version" SG_ 623 ATS_RRLumbarDefBtn "19.09.02";
BA_ "Description" SG_ 623 ATS_RRLumbarLowBtn "ÈÄ¼® RH ·³¹ö LOW ÀÛµ¿";
BA_ "GenSigSendType" SG_ 623 ATS_RRLumbarLowBtn 4;
BA_ "UserSigValidity" SG_ 623 ATS_RRLumbarLowBtn 3;
BA_ "NetworkRequest" SG_ 623 ATS_RRLumbarLowBtn 0;
BA_ "NetworkRequestHoldingTime" SG_ 623 ATS_RRLumbarLowBtn 5000;
BA_ "Version" SG_ 623 ATS_RRLumbarLowBtn "19.09.02";
BA_ "Description" SG_ 623 ATS_RRLumbarMidBtn "ÈÄ¼® RH ·³¹ö MID ÀÛµ¿";
BA_ "GenSigSendType" SG_ 623 ATS_RRLumbarMidBtn 4;
BA_ "UserSigValidity" SG_ 623 ATS_RRLumbarMidBtn 3;
BA_ "NetworkRequest" SG_ 623 ATS_RRLumbarMidBtn 0;
BA_ "NetworkRequestHoldingTime" SG_ 623 ATS_RRLumbarMidBtn 5000;
BA_ "Version" SG_ 623 ATS_RRLumbarMidBtn "19.09.02";
BA_ "Description" SG_ 623 ATS_RRLumbarUpBtn "ÈÄ¼® RH ·³¹ö UP ÀÛµ¿";
BA_ "GenSigSendType" SG_ 623 ATS_RRLumbarUpBtn 4;
BA_ "UserSigValidity" SG_ 623 ATS_RRLumbarUpBtn 3;
BA_ "NetworkRequest" SG_ 623 ATS_RRLumbarUpBtn 0;
BA_ "NetworkRequestHoldingTime" SG_ 623 ATS_RRLumbarUpBtn 5000;
BA_ "Version" SG_ 623 ATS_RRLumbarUpBtn "19.09.02";
BA_ "Description" SG_ 623 ATS_RRBolsterDefBtn "ÈÄ¼® RH º¼½ºÅÍ ¹è±â ÀÛµ¿";
BA_ "GenSigSendType" SG_ 623 ATS_RRBolsterDefBtn 4;
BA_ "UserSigValidity" SG_ 623 ATS_RRBolsterDefBtn 3;
BA_ "NetworkRequest" SG_ 623 ATS_RRBolsterDefBtn 0;
BA_ "NetworkRequestHoldingTime" SG_ 623 ATS_RRBolsterDefBtn 5000;
BA_ "Version" SG_ 623 ATS_RRBolsterDefBtn "19.09.02";
BA_ "Description" SG_ 623 ATS_RRBolsterInfSw "ÈÄ¼® RH º¼½ºÅÍ Èí±â ÀÛµ¿";
BA_ "GenSigSendType" SG_ 623 ATS_RRBolsterInfSw 4;
BA_ "UserSigValidity" SG_ 623 ATS_RRBolsterInfSw 3;
BA_ "NetworkRequest" SG_ 623 ATS_RRBolsterInfSw 0;
BA_ "NetworkRequestHoldingTime" SG_ 623 ATS_RRBolsterInfSw 5000;
BA_ "Version" SG_ 623 ATS_RRBolsterInfSw "19.09.02";
BA_ "GenMsgSendType" BO_ 1141 0;
BA_ "Description" SG_ 1141 Ast_SHVU_SeatOptSta "µ¿½Â¼® ½ÃÆ®¿¡ Àû¿ëµÈ È÷ÅÍ/ÅëÇ³ ¿É¼Ç »ç¾ç";
BA_ "GenSigSendType" SG_ 1141 Ast_SHVU_SeatOptSta 4;
BA_ "UserSigValidity" SG_ 1141 Ast_SHVU_SeatOptSta 3;
BA_REL_ "GenSigTimeoutTime" BU_SG_REL_ FCS SG_ 1141 Ast_SHVU_SeatOptSta 1500;
BA_REL_ "GenSigTimeoutTime" BU_SG_REL_ CGW_CCU SG_ 1141 Ast_SHVU_SeatOptSta 1500;
BA_ "NetworkRequest" SG_ 1141 Ast_SHVU_SeatOptSta 0;
BA_ "NetworkRequestHoldingTime" SG_ 1141 Ast_SHVU_SeatOptSta 5000;
BA_ "Version" SG_ 1141 Ast_SHVU_SeatOptSta "19.01.04";
BA_ "Description" SG_ 1141 Ast_SHVU_HtSwHiIndSta "µ¿½Â¼® ½ÃÆ® ¿­¼± ½ºÀ§Ä¡ High Indicator Á¤º¸";
BA_ "GenSigSendType" SG_ 1141 Ast_SHVU_HtSwHiIndSta 4;
BA_ "UserSigValidity" SG_ 1141 Ast_SHVU_HtSwHiIndSta 3;
BA_REL_ "GenSigTimeoutTime" BU_SG_REL_ FCS SG_ 1141 Ast_SHVU_HtSwHiIndSta 1500;
BA_REL_ "GenSigTimeoutTime" BU_SG_REL_ CGW_CCU SG_ 1141 Ast_SHVU_HtSwHiIndSta 1500;
BA_ "NetworkRequest" SG_ 1141 Ast_SHVU_HtSwHiIndSta 0;
BA_ "NetworkRequestHoldingTime" SG_ 1141 Ast_SHVU_HtSwHiIndSta 5000;
BA_ "Version" SG_ 1141 Ast_SHVU_HtSwHiIndSta "19.01.04";
BA_ "Description" SG_ 1141 Ast_SHVU_HtSwMidIndSta "µ¿½Â¼® ½ÃÆ® ¿­¼± ½ºÀ§Ä¡ Mid Indicator Á¤º¸";
BA_ "GenSigSendType" SG_ 1141 Ast_SHVU_HtSwMidIndSta 4;
BA_ "UserSigValidity" SG_ 1141 Ast_SHVU_HtSwMidIndSta 3;
BA_REL_ "GenSigTimeoutTime" BU_SG_REL_ FCS SG_ 1141 Ast_SHVU_HtSwMidIndSta 1500;
BA_REL_ "GenSigTimeoutTime" BU_SG_REL_ CGW_CCU SG_ 1141 Ast_SHVU_HtSwMidIndSta 1500;
BA_ "NetworkRequest" SG_ 1141 Ast_SHVU_HtSwMidIndSta 0;
BA_ "NetworkRequestHoldingTime" SG_ 1141 Ast_SHVU_HtSwMidIndSta 5000;
BA_ "Version" SG_ 1141 Ast_SHVU_HtSwMidIndSta "19.01.04";
BA_ "Description" SG_ 1141 Ast_SHVU_HtSwLowIndSta "µ¿½Â¼® ½ÃÆ® ¿­¼± ½ºÀ§Ä¡ Low Indicator Á¤º¸";
BA_ "GenSigSendType" SG_ 1141 Ast_SHVU_HtSwLowIndSta 4;
BA_ "UserSigValidity" SG_ 1141 Ast_SHVU_HtSwLowIndSta 3;
BA_REL_ "GenSigTimeoutTime" BU_SG_REL_ FCS SG_ 1141 Ast_SHVU_HtSwLowIndSta 1500;
BA_REL_ "GenSigTimeoutTime" BU_SG_REL_ CGW_CCU SG_ 1141 Ast_SHVU_HtSwLowIndSta 1500;
BA_ "NetworkRequest" SG_ 1141 Ast_SHVU_HtSwLowIndSta 0;
BA_ "NetworkRequestHoldingTime" SG_ 1141 Ast_SHVU_HtSwLowIndSta 5000;
BA_ "Version" SG_ 1141 Ast_SHVU_HtSwLowIndSta "19.01.04";
BA_ "Description" SG_ 1141 Ast_SHVU_VntSwHiIndSta "µ¿½Â¼® ½ÃÆ® ÅëÇ³ ½ºÀ§Ä¡ High Indicator Á¤º¸";
BA_ "GenSigSendType" SG_ 1141 Ast_SHVU_VntSwHiIndSta 4;
BA_ "UserSigValidity" SG_ 1141 Ast_SHVU_VntSwHiIndSta 3;
BA_REL_ "GenSigTimeoutTime" BU_SG_REL_ FCS SG_ 1141 Ast_SHVU_VntSwHiIndSta 1500;
BA_REL_ "GenSigTimeoutTime" BU_SG_REL_ CGW_CCU SG_ 1141 Ast_SHVU_VntSwHiIndSta 1500;
BA_ "NetworkRequest" SG_ 1141 Ast_SHVU_VntSwHiIndSta 0;
BA_ "NetworkRequestHoldingTime" SG_ 1141 Ast_SHVU_VntSwHiIndSta 5000;
BA_ "Version" SG_ 1141 Ast_SHVU_VntSwHiIndSta "19.01.04";
BA_ "Description" SG_ 1141 Ast_SHVU_VntSwMidIndSta "µ¿½Â¼® ½ÃÆ® ÅëÇ³ ½ºÀ§Ä¡ Mid Indicator Á¤º¸";
BA_ "GenSigSendType" SG_ 1141 Ast_SHVU_VntSwMidIndSta 4;
BA_ "UserSigValidity" SG_ 1141 Ast_SHVU_VntSwMidIndSta 3;
BA_REL_ "GenSigTimeoutTime" BU_SG_REL_ FCS SG_ 1141 Ast_SHVU_VntSwMidIndSta 1500;
BA_REL_ "GenSigTimeoutTime" BU_SG_REL_ CGW_CCU SG_ 1141 Ast_SHVU_VntSwMidIndSta 1500;
BA_ "NetworkRequest" SG_ 1141 Ast_SHVU_VntSwMidIndSta 0;
BA_ "NetworkRequestHoldingTime" SG_ 1141 Ast_SHVU_VntSwMidIndSta 5000;
BA_ "Version" SG_ 1141 Ast_SHVU_VntSwMidIndSta "19.01.04";
BA_ "Description" SG_ 1141 Ast_SHVU_VntSwLowIndSta "µ¿½Â¼® ½ÃÆ® ÅëÇ³ ½ºÀ§Ä¡ Low Indicator Á¤º¸";
BA_ "GenSigSendType" SG_ 1141 Ast_SHVU_VntSwLowIndSta 4;
BA_ "UserSigValidity" SG_ 1141 Ast_SHVU_VntSwLowIndSta 3;
BA_REL_ "GenSigTimeoutTime" BU_SG_REL_ FCS SG_ 1141 Ast_SHVU_VntSwLowIndSta 1500;
BA_REL_ "GenSigTimeoutTime" BU_SG_REL_ CGW_CCU SG_ 1141 Ast_SHVU_VntSwLowIndSta 1500;
BA_ "NetworkRequest" SG_ 1141 Ast_SHVU_VntSwLowIndSta 0;
BA_ "NetworkRequestHoldingTime" SG_ 1141 Ast_SHVU_VntSwLowIndSta 5000;
BA_ "Version" SG_ 1141 Ast_SHVU_VntSwLowIndSta "19.01.04";
BA_ "Description" SG_ 1141 Ast_SHVU_HtBlcUSMSta "Hetaer Balance Assistant USM R vaule";
BA_ "GenSigSendType" SG_ 1141 Ast_SHVU_HtBlcUSMSta 4;
BA_ "UserSigValidity" SG_ 1141 Ast_SHVU_HtBlcUSMSta 0;
BA_REL_ "GenSigTimeoutTime" BU_SG_REL_ CGW_CCU SG_ 1141 Ast_SHVU_HtBlcUSMSta 1500;
BA_ "Version" SG_ 1141 Ast_SHVU_HtBlcUSMSta "19.01.04";
BA_ "Description" SG_ 1141 Ast_SHVU_SeatHtOperSta "µ¿½Â¼® ½ÃÆ® ÇöÀç ÀÛµ¿ ÁßÀÎ È÷ÅÍ/ÅëÇ³ ´Ü¼ö »óÅÂ";
BA_ "GenSigSendType" SG_ 1141 Ast_SHVU_SeatHtOperSta 4;
BA_ "UserSigValidity" SG_ 1141 Ast_SHVU_SeatHtOperSta 3;
BA_REL_ "GenSigTimeoutTime" BU_SG_REL_ CGW_CCU SG_ 1141 Ast_SHVU_SeatHtOperSta 1500;
BA_ "NetworkRequest" SG_ 1141 Ast_SHVU_SeatHtOperSta 0;
BA_ "NetworkRequestHoldingTime" SG_ 1141 Ast_SHVU_SeatHtOperSta 5000;
BA_ "Version" SG_ 1141 Ast_SHVU_SeatHtOperSta "19.01.04";
BA_ "Description" SG_ 1141 Ast_SHVU_HtSwHiIndSta_RHD "µ¿½Â¼® ½ÃÆ® ¿­¼± ½ºÀ§Ä¡ High Indicator Á¤º¸(RHD)";
BA_ "GenSigSendType" SG_ 1141 Ast_SHVU_HtSwHiIndSta_RHD 4;
BA_ "UserSigValidity" SG_ 1141 Ast_SHVU_HtSwHiIndSta_RHD 3;
BA_REL_ "GenSigTimeoutTime" BU_SG_REL_ FCS SG_ 1141 Ast_SHVU_HtSwHiIndSta_RHD 1500;
BA_REL_ "GenSigTimeoutTime" BU_SG_REL_ CGW_CCU SG_ 1141 Ast_SHVU_HtSwHiIndSta_RHD 1500;
BA_ "NetworkRequest" SG_ 1141 Ast_SHVU_HtSwHiIndSta_RHD 0;
BA_ "NetworkRequestHoldingTime" SG_ 1141 Ast_SHVU_HtSwHiIndSta_RHD 5000;
BA_ "Version" SG_ 1141 Ast_SHVU_HtSwHiIndSta_RHD "19.01.04";
BA_ "Description" SG_ 1141 Ast_SHVU_HtSwMidIndSta_RHD "µ¿½Â¼® ½ÃÆ® ¿­¼± ½ºÀ§Ä¡ Mid Indicator Á¤º¸(RHD)";
BA_ "GenSigSendType" SG_ 1141 Ast_SHVU_HtSwMidIndSta_RHD 4;
BA_ "UserSigValidity" SG_ 1141 Ast_SHVU_HtSwMidIndSta_RHD 3;
BA_REL_ "GenSigTimeoutTime" BU_SG_REL_ FCS SG_ 1141 Ast_SHVU_HtSwMidIndSta_RHD 1500;
BA_REL_ "GenSigTimeoutTime" BU_SG_REL_ CGW_CCU SG_ 1141 Ast_SHVU_HtSwMidIndSta_RHD 1500;
BA_ "NetworkRequest" SG_ 1141 Ast_SHVU_HtSwMidIndSta_RHD 0;
BA_ "NetworkRequestHoldingTime" SG_ 1141 Ast_SHVU_HtSwMidIndSta_RHD 5000;
BA_ "Version" SG_ 1141 Ast_SHVU_HtSwMidIndSta_RHD "19.01.04";
BA_ "Description" SG_ 1141 Ast_SHVU_HtSwLowIndSta_RHD "µ¿½Â¼® ½ÃÆ® ¿­¼± ½ºÀ§Ä¡ Low Indicator Á¤º¸(RHD)";
BA_ "GenSigSendType" SG_ 1141 Ast_SHVU_HtSwLowIndSta_RHD 4;
BA_ "UserSigValidity" SG_ 1141 Ast_SHVU_HtSwLowIndSta_RHD 3;
BA_REL_ "GenSigTimeoutTime" BU_SG_REL_ FCS SG_ 1141 Ast_SHVU_HtSwLowIndSta_RHD 1500;
BA_REL_ "GenSigTimeoutTime" BU_SG_REL_ CGW_CCU SG_ 1141 Ast_SHVU_HtSwLowIndSta_RHD 1500;
BA_ "NetworkRequest" SG_ 1141 Ast_SHVU_HtSwLowIndSta_RHD 0;
BA_ "NetworkRequestHoldingTime" SG_ 1141 Ast_SHVU_HtSwLowIndSta_RHD 5000;
BA_ "Version" SG_ 1141 Ast_SHVU_HtSwLowIndSta_RHD "19.01.04";
BA_ "Description" SG_ 1141 Ast_SHVU_VntSwHiIndSta_RHD "µ¿½Â¼® ½ÃÆ® ÅëÇ³ ½ºÀ§Ä¡ High Indicator Á¤º¸(RHD)";
BA_ "GenSigSendType" SG_ 1141 Ast_SHVU_VntSwHiIndSta_RHD 4;
BA_ "UserSigValidity" SG_ 1141 Ast_SHVU_VntSwHiIndSta_RHD 3;
BA_REL_ "GenSigTimeoutTime" BU_SG_REL_ FCS SG_ 1141 Ast_SHVU_VntSwHiIndSta_RHD 1500;
BA_REL_ "GenSigTimeoutTime" BU_SG_REL_ CGW_CCU SG_ 1141 Ast_SHVU_VntSwHiIndSta_RHD 1500;
BA_ "NetworkRequest" SG_ 1141 Ast_SHVU_VntSwHiIndSta_RHD 0;
BA_ "NetworkRequestHoldingTime" SG_ 1141 Ast_SHVU_VntSwHiIndSta_RHD 5000;
BA_ "Version" SG_ 1141 Ast_SHVU_VntSwHiIndSta_RHD "19.01.04";
BA_ "Description" SG_ 1141 Ast_SHVU_VntSwMidIndSta_RHD "µ¿½Â¼® ½ÃÆ® ÅëÇ³ ½ºÀ§Ä¡ Mid Indicator Á¤º¸(RHD)";
BA_ "GenSigSendType" SG_ 1141 Ast_SHVU_VntSwMidIndSta_RHD 4;
BA_ "UserSigValidity" SG_ 1141 Ast_SHVU_VntSwMidIndSta_RHD 3;
BA_REL_ "GenSigTimeoutTime" BU_SG_REL_ FCS SG_ 1141 Ast_SHVU_VntSwMidIndSta_RHD 1500;
BA_REL_ "GenSigTimeoutTime" BU_SG_REL_ CGW_CCU SG_ 1141 Ast_SHVU_VntSwMidIndSta_RHD 1500;
BA_ "NetworkRequest" SG_ 1141 Ast_SHVU_VntSwMidIndSta_RHD 0;
BA_ "NetworkRequestHoldingTime" SG_ 1141 Ast_SHVU_VntSwMidIndSta_RHD 5000;
BA_ "Version" SG_ 1141 Ast_SHVU_VntSwMidIndSta_RHD "19.01.04";
BA_ "Description" SG_ 1141 Ast_SHVU_VntSwLowIndSta_RHD "µ¿½Â¼® ½ÃÆ® ÅëÇ³ ½ºÀ§Ä¡ Low Indicator Á¤º¸(RHD)";
BA_ "GenSigSendType" SG_ 1141 Ast_SHVU_VntSwLowIndSta_RHD 4;
BA_ "UserSigValidity" SG_ 1141 Ast_SHVU_VntSwLowIndSta_RHD 3;
BA_REL_ "GenSigTimeoutTime" BU_SG_REL_ FCS SG_ 1141 Ast_SHVU_VntSwLowIndSta_RHD 1500;
BA_REL_ "GenSigTimeoutTime" BU_SG_REL_ CGW_CCU SG_ 1141 Ast_SHVU_VntSwLowIndSta_RHD 1500;
BA_ "NetworkRequest" SG_ 1141 Ast_SHVU_VntSwLowIndSta_RHD 0;
BA_ "NetworkRequestHoldingTime" SG_ 1141 Ast_SHVU_VntSwLowIndSta_RHD 5000;
BA_ "Version" SG_ 1141 Ast_SHVU_VntSwLowIndSta_RHD "19.01.04";
BA_ "GenMsgSendType" BO_ 1050 0;
BA_ "Description" SG_ 1050 BCM_Crc7Val "The data area for CRC calculation is based on the data length (DLC) of the message DB.

The CRC shall be calculated over the entire data block (excluding the CRC bytes) including the user data, alive counter and Data ID 

 

- CRC Polynomial (0x1D) , Initial Value : 0x00, XOR value : 0xFF, Data ID Mode : Both, Data ID : Message ID + 0xF800 

- The initial value is for CRC calculation and the message should be sent with the calculated result value. 

The mathematical expression to 8 bit CRC polynomial is given here. G(x) = x8 + x4 + x3 + x2 + 1";
BA_ "GenSigSendType" SG_ 1050 BCM_Crc7Val 4;
BA_ "GenSigStartValue" SG_ 1050 BCM_Crc7Val 255;
BA_ "UserSigValidity" SG_ 1050 BCM_Crc7Val 0;
BA_ "Version" SG_ 1050 BCM_Crc7Val "18.11.08";
BA_ "Description" SG_ 1050 BCM_AlvCnt7Val "For the first transmission request for a data element the counter shall be initialized with 0 and shall be incremented by 1

for every subsequent send request. When the counter reaches the maximum value(0xE), then it shall restart with 0 for the next send request";
BA_ "GenSigSendType" SG_ 1050 BCM_AlvCnt7Val 4;
BA_ "UserSigValidity" SG_ 1050 BCM_AlvCnt7Val 0;
BA_ "Version" SG_ 1050 BCM_AlvCnt7Val "18.11.08";
BA_ "Description" SG_ 1050 Lamp_HiPrioHzrdReq "-Higher priority than SJB hazard

-Diag/Arm/DisArm/Balarm/Panic/MTS

-Initial Value: 2";
BA_ "GenSigSendType" SG_ 1050 Lamp_HiPrioHzrdReq 4;
BA_ "GenSigStartValue" SG_ 1050 Lamp_HiPrioHzrdReq 2;
BA_ "UserSigValidity" SG_ 1050 Lamp_HiPrioHzrdReq 0;
BA_ "NetworkRequest" SG_ 1050 Lamp_HiPrioHzrdReq 0;
BA_ "NetworkRequestHoldingTime" SG_ 1050 Lamp_HiPrioHzrdReq 5000;
BA_ "Version" SG_ 1050 Lamp_HiPrioHzrdReq "17.12.00";
BA_ "Description" SG_ 1050 Lamp_LoPrioHzrdReq "-Lower priority than SJB hazard

-TrunkOpenClose/CrashUnlock/RemoteStart

-Initial Value: 2";
BA_ "GenSigSendType" SG_ 1050 Lamp_LoPrioHzrdReq 4;
BA_ "GenSigStartValue" SG_ 1050 Lamp_LoPrioHzrdReq 2;
BA_ "UserSigValidity" SG_ 1050 Lamp_LoPrioHzrdReq 0;
BA_ "NetworkRequest" SG_ 1050 Lamp_LoPrioHzrdReq 0;
BA_ "NetworkRequestHoldingTime" SG_ 1050 Lamp_LoPrioHzrdReq 5000;
BA_ "Version" SG_ 1050 Lamp_LoPrioHzrdReq "17.12.00";
BA_ "Description" SG_ 1050 Lamp_IntTailLmpOnReq "-(Old)C_INTTailOn";
BA_ "GenSigSendType" SG_ 1050 Lamp_IntTailLmpOnReq 4;
BA_ "UserSigValidity" SG_ 1050 Lamp_IntTailLmpOnReq 0;
BA_REL_ "GenSigTimeoutTime" BU_SG_REL_ FCS SG_ 1050 Lamp_IntTailLmpOnReq 1500;
BA_REL_ "GenSigTimeoutTime" BU_SG_REL_ WPC SG_ 1050 Lamp_IntTailLmpOnReq 1500;
BA_REL_ "GenSigTimeoutTime" BU_SG_REL_ RWPC SG_ 1050 Lamp_IntTailLmpOnReq 1500;
BA_REL_ "GenSigTimeoutTime" BU_SG_REL_ APSU SG_ 1050 Lamp_IntTailLmpOnReq 1500;
BA_REL_ "GenSigTimeoutTime" BU_SG_REL_ RLHV SG_ 1050 Lamp_IntTailLmpOnReq 1500;
BA_REL_ "GenSigTimeoutTime" BU_SG_REL_ RRHV SG_ 1050 Lamp_IntTailLmpOnReq 1500;
BA_REL_ "GenSigTimeoutTime" BU_SG_REL_ SHVU_FR SG_ 1050 Lamp_IntTailLmpOnReq 1500;
BA_REL_ "GenSigTimeoutTime" BU_SG_REL_ SHVU_RR SG_ 1050 Lamp_IntTailLmpOnReq 1500;
BA_REL_ "GenSigTimeoutTime" BU_SG_REL_ DPSU SG_ 1050 Lamp_IntTailLmpOnReq 1500;
BA_ "NetworkRequest" SG_ 1050 Lamp_IntTailLmpOnReq 0;
BA_ "NetworkRequestHoldingTime" SG_ 1050 Lamp_IntTailLmpOnReq 5000;
BA_ "Version" SG_ 1050 Lamp_IntTailLmpOnReq "17.12.00";
BA_ "Description" SG_ 1050 Lamp_ExtrnlTailLmpOnReq "-(Old)C_EXTTailOn";
BA_ "GenSigSendType" SG_ 1050 Lamp_ExtrnlTailLmpOnReq 4;
BA_ "UserSigValidity" SG_ 1050 Lamp_ExtrnlTailLmpOnReq 0;
BA_REL_ "GenSigTimeoutTime" BU_SG_REL_ BLTN_CAM SG_ 1050 Lamp_ExtrnlTailLmpOnReq 1500;
BA_ "NetworkRequest" SG_ 1050 Lamp_ExtrnlTailLmpOnReq 0;
BA_ "NetworkRequestHoldingTime" SG_ 1050 Lamp_ExtrnlTailLmpOnReq 5000;
BA_ "Version" SG_ 1050 Lamp_ExtrnlTailLmpOnReq "17.12.00";
BA_ "Description" SG_ 1050 Lamp_HdLmpLoOnReq "-(Old)C_HLampLowON";
BA_ "GenSigSendType" SG_ 1050 Lamp_HdLmpLoOnReq 4;
BA_ "UserSigValidity" SG_ 1050 Lamp_HdLmpLoOnReq 0;
BA_ "NetworkRequest" SG_ 1050 Lamp_HdLmpLoOnReq 0;
BA_ "NetworkRequestHoldingTime" SG_ 1050 Lamp_HdLmpLoOnReq 5000;
BA_ "Version" SG_ 1050 Lamp_HdLmpLoOnReq "17.12.00";
BA_ "Description" SG_ 1050 Lamp_HdLmpHiOnReq "-(Old)C_HLampHighON";
BA_ "GenSigSendType" SG_ 1050 Lamp_HdLmpHiOnReq 4;
BA_ "UserSigValidity" SG_ 1050 Lamp_HdLmpHiOnReq 0;
BA_ "NetworkRequest" SG_ 1050 Lamp_HdLmpHiOnReq 0;
BA_ "NetworkRequestHoldingTime" SG_ 1050 Lamp_HdLmpHiOnReq 5000;
BA_ "Version" SG_ 1050 Lamp_HdLmpHiOnReq "17.12.00";
BA_ "Description" SG_ 1050 Lamp_AvTailLmpSta "-Send with at the same time with C_IntTailOn

-Initiail Value: 1";
BA_ "GenSigSendType" SG_ 1050 Lamp_AvTailLmpSta 4;
BA_ "GenSigStartValue" SG_ 1050 Lamp_AvTailLmpSta 1;
BA_ "UserSigValidity" SG_ 1050 Lamp_AvTailLmpSta 0;
BA_REL_ "GenSigTimeoutTime" BU_SG_REL_ SWRC SG_ 1050 Lamp_AvTailLmpSta 1500;
BA_REL_ "GenSigTimeoutTime" BU_SG_REL_ APSU SG_ 1050 Lamp_AvTailLmpSta 1500;
BA_REL_ "GenSigTimeoutTime" BU_SG_REL_ ATS SG_ 1050 Lamp_AvTailLmpSta 1500;
BA_ "NetworkRequest" SG_ 1050 Lamp_AvTailLmpSta 0;
BA_ "NetworkRequestHoldingTime" SG_ 1050 Lamp_AvTailLmpSta 5000;
BA_ "Version" SG_ 1050 Lamp_AvTailLmpSta "17.12.00";
BA_ "Description" SG_ 1050 Lamp_BckUpLmpCmd "BackUp Lamp On/Off Command";
BA_ "GenSigSendType" SG_ 1050 Lamp_BckUpLmpCmd 4;
BA_ "UserSigValidity" SG_ 1050 Lamp_BckUpLmpCmd 0;
BA_ "NetworkRequest" SG_ 1050 Lamp_BckUpLmpCmd 0;
BA_ "NetworkRequestHoldingTime" SG_ 1050 Lamp_BckUpLmpCmd 5000;
BA_ "Version" SG_ 1050 Lamp_BckUpLmpCmd "20.08.02";
BA_ "Description" SG_ 1050 Lamp_DrlOnReq "Lamp on command for DRL";
BA_ "GenSigSendType" SG_ 1050 Lamp_DrlOnReq 4;
BA_ "UserSigValidity" SG_ 1050 Lamp_DrlOnReq 0;
BA_ "NetworkRequest" SG_ 1050 Lamp_DrlOnReq 0;
BA_ "NetworkRequestHoldingTime" SG_ 1050 Lamp_DrlOnReq 5000;
BA_ "Version" SG_ 1050 Lamp_DrlOnReq "20.09.00";
BA_ "GenMsgSendType" BO_ 1052 0;
BA_ "Description" SG_ 1052 BCM_Crc9Val "The data area for CRC calculation is based on the data length (DLC) of the message DB.

The CRC shall be calculated over the entire data block (excluding the CRC bytes) including the user data, alive counter and Data ID 

 

- CRC Polynomial (0x1D) , Initial Value : 0x00, XOR value : 0xFF, Data ID Mode : Both, Data ID : Message ID + 0xF800 

- The initial value is for CRC calculation and the message should be sent with the calculated result value. 

The mathematical expression to 8 bit CRC polynomial is given here. G(x) = x8 + x4 + x3 + x2 + 1";
BA_ "GenSigSendType" SG_ 1052 BCM_Crc9Val 4;
BA_ "GenSigStartValue" SG_ 1052 BCM_Crc9Val 255;
BA_ "UserSigValidity" SG_ 1052 BCM_Crc9Val 0;
BA_ "Version" SG_ 1052 BCM_Crc9Val "18.11.08";
BA_ "Description" SG_ 1052 BCM_AlvCnt9Val "For the first transmission request for a data element the counter shall be initialized with 0 and shall be incremented by 1

for every subsequent send request. When the counter reaches the maximum value(0xE), then it shall restart with 0 for the next send request";
BA_ "GenSigSendType" SG_ 1052 BCM_AlvCnt9Val 4;
BA_ "UserSigValidity" SG_ 1052 BCM_AlvCnt9Val 0;
BA_ "Version" SG_ 1052 BCM_AlvCnt9Val "18.11.08";
BA_ "Description" SG_ 1052 Lamp_AutoLtSnsrNightSta "This signal indicates autolight sensor output";
BA_ "GenSigSendType" SG_ 1052 Lamp_AutoLtSnsrNightSta 4;
BA_ "GenSigStartValue" SG_ 1052 Lamp_AutoLtSnsrNightSta 1;
BA_ "UserSigValidity" SG_ 1052 Lamp_AutoLtSnsrNightSta 0;
BA_REL_ "GenSigTimeoutTime" BU_SG_REL_ SWRC SG_ 1052 Lamp_AutoLtSnsrNightSta 1500;
BA_REL_ "GenSigTimeoutTime" BU_SG_REL_ APSU SG_ 1052 Lamp_AutoLtSnsrNightSta 1500;
BA_REL_ "GenSigTimeoutTime" BU_SG_REL_ ATS SG_ 1052 Lamp_AutoLtSnsrNightSta 1500;
BA_ "NetworkRequest" SG_ 1052 Lamp_AutoLtSnsrNightSta 0;
BA_ "NetworkRequestHoldingTime" SG_ 1052 Lamp_AutoLtSnsrNightSta 5000;
BA_ "Version" SG_ 1052 Lamp_AutoLtSnsrNightSta "20.04.06";
BA_ "Description" SG_ 1052 Lamp_VendorInfo "Rain seosor Vendor info (LIN to CAN signal)

- 001 : TRW(BCS)

- 010 : HELLA";
BA_ "GenSigSendType" SG_ 1052 Lamp_VendorInfo 4;
BA_ "GenSigStartValue" SG_ 1052 Lamp_VendorInfo 7;
BA_ "UserSigValidity" SG_ 1052 Lamp_VendorInfo 0;
BA_ "NetworkRequest" SG_ 1052 Lamp_VendorInfo 0;
BA_ "NetworkRequestHoldingTime" SG_ 1052 Lamp_VendorInfo 5000;
BA_ "Version" SG_ 1052 Lamp_VendorInfo "20.05.03";
BA_ "Description" SG_ 1052 Lamp_AutoLtSnsrHorVal "This signal indicates autolight sensor output (for HUD)";
BA_ "GenSigSendType" SG_ 1052 Lamp_AutoLtSnsrHorVal 4;
BA_ "UserSigValidity" SG_ 1052 Lamp_AutoLtSnsrHorVal 0;
BA_REL_ "GenSigTimeoutTime" BU_SG_REL_ ATS SG_ 1052 Lamp_AutoLtSnsrHorVal 1500;
BA_ "NetworkRequest" SG_ 1052 Lamp_AutoLtSnsrHorVal 0;
BA_ "NetworkRequestHoldingTime" SG_ 1052 Lamp_AutoLtSnsrHorVal 5000;
BA_ "Version" SG_ 1052 Lamp_AutoLtSnsrHorVal "21.07.05";
BA_ "Description" SG_ 1052 IBU_HDPSpprtSWVer "This signal indicates HDP-IBU requirement version";
BA_ "GenSigSendType" SG_ 1052 IBU_HDPSpprtSWVer 4;
BA_ "UserSigValidity" SG_ 1052 IBU_HDPSpprtSWVer 0;
BA_ "NetworkRequest" SG_ 1052 IBU_HDPSpprtSWVer 0;
BA_ "NetworkRequestHoldingTime" SG_ 1052 IBU_HDPSpprtSWVer 5000;
BA_ "Version" SG_ 1052 IBU_HDPSpprtSWVer "21.10.04";
BA_ "Description" SG_ 1052 Wiper_RainAmount "Amount of rain on windshield (LIN to CAN Signal)

- LIN Signal Name : VAL_RAIN_AMOUNT

- 0~150 : PH=0.5*HEX%

- 151~254 : Reserved

- 255 (1111 1111) : Invalid";
BA_ "GenSigSendType" SG_ 1052 Wiper_RainAmount 4;
BA_ "GenSigStartValue" SG_ 1052 Wiper_RainAmount 255;
BA_ "UserSigValidity" SG_ 1052 Wiper_RainAmount 0;
BA_ "NetworkRequest" SG_ 1052 Wiper_RainAmount 0;
BA_ "NetworkRequestHoldingTime" SG_ 1052 Wiper_RainAmount 5000;
BA_ "Version" SG_ 1052 Wiper_RainAmount "21.07.05";
BA_ "GenMsgSendType" BO_ 1124 0;
BA_ "Description" SG_ 1124 BCM_Crc15Val "The data area for CRC calculation is based on the data length (DLC) of the message DB.

The CRC shall be calculated over the entire data block (excluding the CRC bytes) including the user data, alive counter and Data ID 

 

- CRC Polynomial (0x1D) , Initial Value : 0x00, XOR value : 0xFF, Data ID Mode : Both, Data ID : Message ID + 0xF800 

- The initial value is for CRC calculation and the message should be sent with the calculated result value. 

The mathematical expression to 8 bit CRC polynomial is given here. G(x) = x8 + x4 + x3 + x2 + 1";
BA_ "GenSigSendType" SG_ 1124 BCM_Crc15Val 4;
BA_ "GenSigStartValue" SG_ 1124 BCM_Crc15Val 255;
BA_ "UserSigValidity" SG_ 1124 BCM_Crc15Val 0;
BA_ "Version" SG_ 1124 BCM_Crc15Val "18.11.08";
BA_ "Description" SG_ 1124 BCM_AlvCnt15Val "For the first transmission request for a data element the counter shall be initialized with 0 and shall be incremented by 1

for every subsequent send request. When the counter reaches the maximum value(0xE), then it shall restart with 0 for the next send request";
BA_ "GenSigSendType" SG_ 1124 BCM_AlvCnt15Val 4;
BA_ "UserSigValidity" SG_ 1124 BCM_AlvCnt15Val 0;
BA_ "Version" SG_ 1124 BCM_AlvCnt15Val "18.11.08";
BA_ "Description" SG_ 1124 Window_DrvrSdWdwActSta "This signal indicates DRV Window Action Status";
BA_ "GenSigSendType" SG_ 1124 Window_DrvrSdWdwActSta 4;
BA_ "GenSigStartValue" SG_ 1124 Window_DrvrSdWdwActSta 15;
BA_ "UserSigValidity" SG_ 1124 Window_DrvrSdWdwActSta 0;
BA_ "NetworkRequest" SG_ 1124 Window_DrvrSdWdwActSta 0;
BA_ "NetworkRequestHoldingTime" SG_ 1124 Window_DrvrSdWdwActSta 5000;
BA_ "Version" SG_ 1124 Window_DrvrSdWdwActSta "18.02.01";
BA_ "Description" SG_ 1124 Window_AsstSdWdwActSta "This signal indicates AST Window Action Status";
BA_ "GenSigSendType" SG_ 1124 Window_AsstSdWdwActSta 4;
BA_ "GenSigStartValue" SG_ 1124 Window_AsstSdWdwActSta 15;
BA_ "UserSigValidity" SG_ 1124 Window_AsstSdWdwActSta 0;
BA_ "NetworkRequest" SG_ 1124 Window_AsstSdWdwActSta 0;
BA_ "NetworkRequestHoldingTime" SG_ 1124 Window_AsstSdWdwActSta 5000;
BA_ "Version" SG_ 1124 Window_AsstSdWdwActSta "18.02.01";
BA_ "Description" SG_ 1124 Window_RrLftWdwActSta "This signal indicates RL Window Action Status";
BA_ "GenSigSendType" SG_ 1124 Window_RrLftWdwActSta 4;
BA_ "GenSigStartValue" SG_ 1124 Window_RrLftWdwActSta 15;
BA_ "UserSigValidity" SG_ 1124 Window_RrLftWdwActSta 0;
BA_ "NetworkRequest" SG_ 1124 Window_RrLftWdwActSta 0;
BA_ "NetworkRequestHoldingTime" SG_ 1124 Window_RrLftWdwActSta 5000;
BA_ "Version" SG_ 1124 Window_RrLftWdwActSta "18.02.01";
BA_ "Description" SG_ 1124 Window_RrRtWdwActSta "This signal indicates RR Window Action Status";
BA_ "GenSigSendType" SG_ 1124 Window_RrRtWdwActSta 4;
BA_ "GenSigStartValue" SG_ 1124 Window_RrRtWdwActSta 15;
BA_ "UserSigValidity" SG_ 1124 Window_RrRtWdwActSta 0;
BA_ "NetworkRequest" SG_ 1124 Window_RrRtWdwActSta 0;
BA_ "NetworkRequestHoldingTime" SG_ 1124 Window_RrRtWdwActSta 5000;
BA_ "Version" SG_ 1124 Window_RrRtWdwActSta "18.02.01";
BA_ "Description" SG_ 1124 Window_DrvrSdWdwDetailOpnSta "This signal indicates DRV Window Open/Close Detail Status";
BA_ "GenSigSendType" SG_ 1124 Window_DrvrSdWdwDetailOpnSta 4;
BA_ "GenSigStartValue" SG_ 1124 Window_DrvrSdWdwDetailOpnSta 7;
BA_ "UserSigValidity" SG_ 1124 Window_DrvrSdWdwDetailOpnSta 0;
BA_ "NetworkRequest" SG_ 1124 Window_DrvrSdWdwDetailOpnSta 0;
BA_ "NetworkRequestHoldingTime" SG_ 1124 Window_DrvrSdWdwDetailOpnSta 5000;
BA_ "Version" SG_ 1124 Window_DrvrSdWdwDetailOpnSta "18.02.01";
BA_ "Description" SG_ 1124 Window_AsstSdWdwDetailOpnSta "This signal indicates AST Window Open/Close Detail Status";
BA_ "GenSigSendType" SG_ 1124 Window_AsstSdWdwDetailOpnSta 4;
BA_ "GenSigStartValue" SG_ 1124 Window_AsstSdWdwDetailOpnSta 7;
BA_ "UserSigValidity" SG_ 1124 Window_AsstSdWdwDetailOpnSta 0;
BA_ "NetworkRequest" SG_ 1124 Window_AsstSdWdwDetailOpnSta 0;
BA_ "NetworkRequestHoldingTime" SG_ 1124 Window_AsstSdWdwDetailOpnSta 5000;
BA_ "Version" SG_ 1124 Window_AsstSdWdwDetailOpnSta "18.02.01";
BA_ "Description" SG_ 1124 Window_DrvrSdWdwErrAntPinch "The DRV Window state whether Calibrated or not";
BA_ "GenSigSendType" SG_ 1124 Window_DrvrSdWdwErrAntPinch 4;
BA_ "GenSigStartValue" SG_ 1124 Window_DrvrSdWdwErrAntPinch 1;
BA_ "UserSigValidity" SG_ 1124 Window_DrvrSdWdwErrAntPinch 0;
BA_ "NetworkRequest" SG_ 1124 Window_DrvrSdWdwErrAntPinch 0;
BA_ "NetworkRequestHoldingTime" SG_ 1124 Window_DrvrSdWdwErrAntPinch 5000;
BA_ "Version" SG_ 1124 Window_DrvrSdWdwErrAntPinch "18.02.01";
BA_ "Description" SG_ 1124 Window_RrLftWdwDetailOpnSta "This signal indicates RL Window Open/Close Detail Status";
BA_ "GenSigSendType" SG_ 1124 Window_RrLftWdwDetailOpnSta 4;
BA_ "GenSigStartValue" SG_ 1124 Window_RrLftWdwDetailOpnSta 7;
BA_ "UserSigValidity" SG_ 1124 Window_RrLftWdwDetailOpnSta 0;
BA_ "NetworkRequest" SG_ 1124 Window_RrLftWdwDetailOpnSta 0;
BA_ "NetworkRequestHoldingTime" SG_ 1124 Window_RrLftWdwDetailOpnSta 5000;
BA_ "Version" SG_ 1124 Window_RrLftWdwDetailOpnSta "18.02.01";
BA_ "Description" SG_ 1124 Window_RrRtWdwDetailOpnSta "This signal indicates RR Window Open/Close Detail Status";
BA_ "GenSigSendType" SG_ 1124 Window_RrRtWdwDetailOpnSta 4;
BA_ "GenSigStartValue" SG_ 1124 Window_RrRtWdwDetailOpnSta 7;
BA_ "UserSigValidity" SG_ 1124 Window_RrRtWdwDetailOpnSta 0;
BA_ "NetworkRequest" SG_ 1124 Window_RrRtWdwDetailOpnSta 0;
BA_ "NetworkRequestHoldingTime" SG_ 1124 Window_RrRtWdwDetailOpnSta 5000;
BA_ "Version" SG_ 1124 Window_RrRtWdwDetailOpnSta "18.02.01";
BA_ "Description" SG_ 1124 Window_AsstSdWdwErrAntPinch "The AST Window state whether Calibrated or not";
BA_ "GenSigSendType" SG_ 1124 Window_AsstSdWdwErrAntPinch 4;
BA_ "GenSigStartValue" SG_ 1124 Window_AsstSdWdwErrAntPinch 1;
BA_ "UserSigValidity" SG_ 1124 Window_AsstSdWdwErrAntPinch 0;
BA_ "NetworkRequest" SG_ 1124 Window_AsstSdWdwErrAntPinch 0;
BA_ "NetworkRequestHoldingTime" SG_ 1124 Window_AsstSdWdwErrAntPinch 5000;
BA_ "Version" SG_ 1124 Window_AsstSdWdwErrAntPinch "18.02.01";
BA_ "Description" SG_ 1124 Window_RrLftWdwErrAntPinch "The RL Window state whether Calibrated or not";
BA_ "GenSigSendType" SG_ 1124 Window_RrLftWdwErrAntPinch 4;
BA_ "GenSigStartValue" SG_ 1124 Window_RrLftWdwErrAntPinch 1;
BA_ "UserSigValidity" SG_ 1124 Window_RrLftWdwErrAntPinch 0;
BA_ "NetworkRequest" SG_ 1124 Window_RrLftWdwErrAntPinch 0;
BA_ "NetworkRequestHoldingTime" SG_ 1124 Window_RrLftWdwErrAntPinch 5000;
BA_ "Version" SG_ 1124 Window_RrLftWdwErrAntPinch "18.02.01";
BA_ "Description" SG_ 1124 Window_RrRtWdwErrAntPinch "The RR Window state whether Calibrated or not";
BA_ "GenSigSendType" SG_ 1124 Window_RrRtWdwErrAntPinch 4;
BA_ "GenSigStartValue" SG_ 1124 Window_RrRtWdwErrAntPinch 1;
BA_ "UserSigValidity" SG_ 1124 Window_RrRtWdwErrAntPinch 0;
BA_ "NetworkRequest" SG_ 1124 Window_RrRtWdwErrAntPinch 0;
BA_ "NetworkRequestHoldingTime" SG_ 1124 Window_RrRtWdwErrAntPinch 5000;
BA_ "Version" SG_ 1124 Window_RrRtWdwErrAntPinch "18.02.01";
BA_ "Description" SG_ 1124 SunRoof_RrBlindPosSta "This signal indicates Rear Sunroof Blind Open/Close Status";
BA_ "GenSigSendType" SG_ 1124 SunRoof_RrBlindPosSta 4;
BA_ "GenSigStartValue" SG_ 1124 SunRoof_RrBlindPosSta 15;
BA_ "UserSigValidity" SG_ 1124 SunRoof_RrBlindPosSta 0;
BA_REL_ "GenSigTimeoutTime" BU_SG_REL_ ATS SG_ 1124 SunRoof_RrBlindPosSta 1500;
BA_ "Version" SG_ 1124 SunRoof_RrBlindPosSta "20.01.01";
BA_ "GenMsgSendType" BO_ 614 0;
BA_ "Description" SG_ 614 EMCU_Crc1Val "The data area for CRC calculation is based on the data length (DLC) of the message DB.

The CRC shall be calculated over the entire data block (excluding the CRC bytes) including the user data, alive counter and Data ID 

 

- CRC Polynomial (0x1D) , Initial Value : 0x00, XOR value : 0xFF, Data ID Mode : Both, Data ID : Message ID + 0xF800 

- The initial value is for CRC calculation and the message should be sent with the calculated result value. 

The mathematical expression to 8 bit CRC polynomial is given here. G(x) = x8 + x4 + x3 + x2 + 1";
BA_ "GenSigSendType" SG_ 614 EMCU_Crc1Val 4;
BA_ "UserSigValidity" SG_ 614 EMCU_Crc1Val 3;
BA_ "Version" SG_ 614 EMCU_Crc1Val "21.09.03";
BA_ "Description" SG_ 614 EMCU_AlvCnt1Val "For the first transmission request for a data element the counter shall be initialized with 0 and shall be incremented by 1

for every subsequent send request. When the counter reaches the maximum value(0xE), then it shall restart with 0 for the next send request";
BA_ "GenSigSendType" SG_ 614 EMCU_AlvCnt1Val 4;
BA_ "UserSigValidity" SG_ 614 EMCU_AlvCnt1Val 3;
BA_ "Version" SG_ 614 EMCU_AlvCnt1Val "21.09.03";
BA_ "Description" SG_ 614 EMCU_LHActSta "Left Engine Mount ON/OFF Status";
BA_ "GenSigSendType" SG_ 614 EMCU_LHActSta 4;
BA_ "UserSigValidity" SG_ 614 EMCU_LHActSta 3;
BA_ "Version" SG_ 614 EMCU_LHActSta "21.10.03";
BA_ "Description" SG_ 614 EMCU_RHActSta "Right Engine Mount ON/OFF Status";
BA_ "GenSigSendType" SG_ 614 EMCU_RHActSta 4;
BA_ "UserSigValidity" SG_ 614 EMCU_RHActSta 3;
BA_ "Version" SG_ 614 EMCU_RHActSta "21.10.03";
BA_ "Description" SG_ 614 EMCU_DeltaSpdVal "Current Delta Speed Vaule in control logic";
BA_ "GenSigSendType" SG_ 614 EMCU_DeltaSpdVal 4;
BA_ "UserSigValidity" SG_ 614 EMCU_DeltaSpdVal 3;
BA_ "Version" SG_ 614 EMCU_DeltaSpdVal "21.10.03";
BA_ "Description" SG_ 614 EMCU_System_Sta "Engine Mount Control Unit Status";
BA_ "GenSigSendType" SG_ 614 EMCU_System_Sta 4;
BA_ "UserSigValidity" SG_ 614 EMCU_System_Sta 3;
BA_ "Version" SG_ 614 EMCU_System_Sta "21.10.03";
BA_ "GenMsgSendType" BO_ 2214658049 0;
BA_ "GenMsgCycleTime" BO_ 2214658049 50;
BA_ "GenMsgCycleTimeFast" BO_ 2214658049 0;
BA_ "GenMsgNrOfRepetition" BO_ 2214658049 0;
BA_ "VFrameFormat" BO_ 2214658049 1;
BA_ "Description" SG_ 2214658049 EMS_Crc2Val "The data area for CRC calculation is based on the data length (DLC) of the message DB.

The CRC shall be calculated over the entire data block (excluding the CRC bytes) including the user data, alive counter and Data ID

 

- CRC Polynomial (0x1021) , Initial Value : 0xFFFF, XOR value : 0x0000, Data ID : Message ID + 0xF800 

- The initial value is for CRC calculation and the message should be sent with the calculated result value. 

- The mathematical expression to 16 bit CRC polynomial is given here. G(x) = x16 + x12 + x5 + 1";
BA_ "GenSigStartValue" SG_ 2214658049 EMS_Crc2Val 65535;
BA_ "UserSigValidity" SG_ 2214658049 EMS_Crc2Val 3;
BA_ "RoutingFactor" SG_ 2214658049 EMS_Crc2Val 5;
BA_ "Version" SG_ 2214658049 EMS_Crc2Val "18.11.08";
BA_ "Description" SG_ 2214658049 EMS_AlvCnt2Val "For the first transmission request for a data element the counter shall be initialized with 0 and shall be incremented by 1 for every subsequent send request. 

When the counter reaches the maximum value(0xFF), then it shall restart with 0 for the next send request";
BA_ "UserSigValidity" SG_ 2214658049 EMS_AlvCnt2Val 3;
BA_ "RoutingFactor" SG_ 2214658049 EMS_AlvCnt2Val 5;
BA_ "Version" SG_ 2214658049 EMS_AlvCnt2Val "18.11.08";
BA_ "Description" SG_ 2214658049 ENG_BrkSwSta "This signal indicates that a brake switch is activated or not. When the brake switch is activated(pressed) its value is 01H otherwise its value is 00H.

If the EMS does not support this signal the value is 02H.



Physical range : 0 ... 100

Conversion : (PH) = (Unsigned)0.002 * (HEX)[%]";
BA_ "GenSigStartValue" SG_ 2214658049 ENG_BrkSwSta 1;
BA_ "UserSigValidity" SG_ 2214658049 ENG_BrkSwSta 3;
BA_ "RoutingFactor" SG_ 2214658049 ENG_BrkSwSta 5;
BA_ "Version" SG_ 2214658049 ENG_BrkSwSta "18.11.00";
BA_ "Description" SG_ 2214658049 ENG_ObdFrzFrmSta "An ECU which detects an OBD fault, requires the EMS to store a set of environmental conditions

(freeze frame). If the EMS follows this requirement it is acknowledged in OBD_FRF_ACK. Also the synchronization of OBD relevant ECUs is made by this signal:



Bit 3-5 is used for freeze frame acknowledgement.

Bit 2 is set, in case a driving cycle has started.

Bit 1 is set, in case a trip is finished.

Bit 0 is set, in case a warm up cycle is finished.



Bit 5, 4, 3 freeze frame status :

0 - No freeze frame stored

1 - Freeze frame requested by EMS

2 - Freeze frame requested by TCU

3 - Freeze frame requested by TCS

4~7 - Reserved";
BA_ "UserSigValidity" SG_ 2214658049 ENG_ObdFrzFrmSta 3;
BA_ "RoutingFactor" SG_ 2214658049 ENG_ObdFrzFrmSta 5;
BA_ "Version" SG_ 2214658049 ENG_ObdFrzFrmSta "17.12.00";
BA_ "Description" SG_ 2214658049 ENG_EngClntTempVal "Engine coolant temperature in EMS sensed via an A/D converter; converted into degrees centigrade (¡ÆC).";
BA_ "GenSigStartValue" SG_ 2214658049 ENG_EngClntTempVal 255;
BA_ "UserSigValidity" SG_ 2214658049 ENG_EngClntTempVal 3;
BA_ "RoutingFactor" SG_ 2214658049 ENG_EngClntTempVal 5;
BA_ "Version" SG_ 2214658049 ENG_EngClntTempVal "17.12.00";
BA_ "Description" SG_ 2214658049 ENG_MafCrctVal "The altitude correction factor MAF_FAC_ALTI_MMV is calculated from division of MAF by MAF_SUB_DIAG (=limp home-value for MAF) or from AMP_AD by 1013 mbar in order to take into account different atmospheric pressures at different altitudes.



The Initial-value of 1.0 indicates sea-level, whereas lower values indicate altitude. MAF_FAC_ALTI_MMV is limited to C_MAF_FAC_ALTI_MMV_MIN (=0.6) and C_MAF_FAC_ALTI_MMV_MAX (=1.1) by calibration.";
BA_ "GenSigStartValue" SG_ 2214658049 ENG_MafCrctVal 128;
BA_ "UserSigValidity" SG_ 2214658049 ENG_MafCrctVal 3;
BA_ "RoutingFactor" SG_ 2214658049 ENG_MafCrctVal 5;
BA_ "Version" SG_ 2214658049 ENG_MafCrctVal "17.12.00";
BA_ "Description" SG_ 2214658049 ENG_BattDscnctSta "The signal specifies that ECU has detected a disconnection of the battery since last driving cycle, and therefore has reset the adaptive values and failure memory.

If the EMS does not support this signal the value is 00H



The failure memory erasure is activated only if the calibration C_CONF_NVMY_RST is set to 1 inside the EMS.";
BA_ "UserSigValidity" SG_ 2214658049 ENG_BattDscnctSta 3;
BA_ "RoutingFactor" SG_ 2214658049 ENG_BattDscnctSta 5;
BA_ "Version" SG_ 2214658049 ENG_BattDscnctSta "17.12.00";
BA_ "Description" SG_ 2214658049 OBD_MilConfgVal "The signal specifies the Configuration of the MIL Handling and Failure Memory Management by ECU.";
BA_ "GenSigStartValue" SG_ 2214658049 OBD_MilConfgVal 3;
BA_ "UserSigValidity" SG_ 2214658049 OBD_MilConfgVal 3;
BA_ "RoutingFactor" SG_ 2214658049 OBD_MilConfgVal 5;
BA_ "Version" SG_ 2214658049 OBD_MilConfgVal "17.12.00";
BA_ "Description" SG_ 2214658049 ENG_EngSta "This signal indicates that a status of engine.";
BA_ "UserSigValidity" SG_ 2214658049 ENG_EngSta 3;
BA_ "RoutingFactor" SG_ 2214658049 ENG_EngSta 5;
BA_ "Version" SG_ 2214658049 ENG_EngSta "17.12.00";
BA_ "GenMsgSendType" BO_ 2214658050 0;
BA_ "GenMsgCycleTime" BO_ 2214658050 50;
BA_ "GenMsgCycleTimeFast" BO_ 2214658050 0;
BA_ "GenMsgNrOfRepetition" BO_ 2214658050 0;
BA_ "VFrameFormat" BO_ 2214658050 1;
BA_ "Description" SG_ 2214658050 ENG_Ack4EngStpSta "The signal specifies the acknowledgement of the request for the operating state 'engine stopped'.";
BA_ "UserSigValidity" SG_ 2214658050 ENG_Ack4EngStpSta 3;
BA_ "RoutingFactor" SG_ 2214658050 ENG_Ack4EngStpSta 5;
BA_ "Version" SG_ 2214658050 ENG_Ack4EngStpSta "17.12.00";
BA_ "Description" SG_ 2214658050 ENG_AccDrvAlertDisp "If EMS sends the No Auto cruise engaged status or Auto cruise Disengaged status, 

Cluster shall display the status of Auto cruise.";
BA_ "TimeoutValue" SG_ 2214658050 ENG_AccDrvAlertDisp "0x0";
BA_ "UserSigValidity" SG_ 2214658050 ENG_AccDrvAlertDisp 3;
BA_ "RoutingFactor" SG_ 2214658050 ENG_AccDrvAlertDisp 5;
BA_ "Version" SG_ 2214658050 ENG_AccDrvAlertDisp "19.12.08";
BA_ "Description" SG_ 2214658050 DSL_GlowCtrlReq "This signal indicates that a diesel ECU requests ISS system to control glow plugs. 



If the EMS does not support this signal the value is 00H";
BA_ "UserSigValidity" SG_ 2214658050 DSL_GlowCtrlReq 3;
BA_ "RoutingFactor" SG_ 2214658050 DSL_GlowCtrlReq 5;
BA_ "Version" SG_ 2214658050 DSL_GlowCtrlReq "17.12.00";
BA_ "Description" SG_ 2214658050 ENG_GlowLmpSta "This signal indicates that a status of glow lamp.



This signal is used for a Diesel or LPI Engine alternatively.";
BA_ "GenSigStartValue" SG_ 2214658050 ENG_GlowLmpSta 1;
BA_ "UserSigValidity" SG_ 2214658050 ENG_GlowLmpSta 3;
BA_ "RoutingFactor" SG_ 2214658050 ENG_GlowLmpSta 5;
BA_ "Version" SG_ 2214658050 ENG_GlowLmpSta "17.12.00";
BA_ "Description" SG_ 2214658050 ENG_ThrPosVal "The signal TPS is a measure of the throttle position.

The throttle position is determined via a potentiometer, which is connected mechanically to the throttle shaft. The voltage value, which is adjusted in the port via the voltage divider, is sensed in the EMS by an A/D converter. The lower mechanical stop (idle) is sensed by a learning algorithm (offset). If the EMS-ECU recognizes closed throttle then the value 20 H is carried over on the CAN. If the EMS-ECU detects full load, that means nearly perpendicular throttle position, then F5 H is carried over on the CAN bus. Even if the throttle position exceeds the full load detection throttle angle the transmitted HEX-value is limited to F5 H.



If an error is detected in sensing of the position, this is identified by the value FFH.";
BA_ "GenSigStartValue" SG_ 2214658050 ENG_ThrPosVal 32;
BA_ "UserSigValidity" SG_ 2214658050 ENG_ThrPosVal 3;
BA_ "RoutingFactor" SG_ 2214658050 ENG_ThrPosVal 5;
BA_ "Version" SG_ 2214658050 ENG_ThrPosVal "17.12.00";
BA_ "Description" SG_ 2214658050 ENG_OverDrvOffReq "This signal indicates that auto cruise control function requests over drive off of TCU. 

In general, the over drive off request is done by hardware. (i.e. line-to-line signal between an EMS and a TCU). However, some systems may not have external over drive off requetst signal line and for these systems OD_OFF_REQ signal can be used as the same function.";
BA_ "UserSigValidity" SG_ 2214658050 ENG_OverDrvOffReq 3;
BA_ "RoutingFactor" SG_ 2214658050 ENG_OverDrvOffReq 5;
BA_ "Version" SG_ 2214658050 ENG_OverDrvOffReq "17.12.00";
BA_ "Description" SG_ 2214658050 ENG_AccelPdlVal "The signal PV_AV_CAN is a measure of the Accelerator Pedal value.

The accelerator pedal value is determined via 2 pedal sensors, which are connected mechanically to the

accelerator pedal. If the EMS-ECU recognizes that the accelerator pedal is not activated, then the value

00 H is carried over on the CAN. If the EMS-ECU detects that the accelerator pedal is fully activated, then 3FEH is carried over on the CAN bus.

If an error is detected on both pedal sensor channels, this is identified by the value 3FFH.



Signal relationship between ACC_ACT and PV_AV_CAN :

The phase relationship between auto cruise control and PV_AV_CAN is as following figure. If an auto cruise control system is not installed or if cruise control is not activated in auto cruise control system installed vehicle then PV_AV_CAN has actual pedal position value. But if the auto cruise control is activated (actually speed control is performed by EMS), PV_AV_CAN should have modeling value even if a driver does not press the acceleration pedal.

If ACC_ACT is value(0), then PV_AV_CAN is APS Value.

If ACC_ACT is value(1), then PV_AV_CAN is Modeling Value.

* APS Value : Acceleration Pedal Sensor value.

* Modeling Value : Estimated APS value which is calculated by ECU logic considering engine control during the auto-cruise control is activated period. (e.g. estimated throttle value of

gasoline engine system or TPS model value of diesel engine system)

And also this value can be used as a driver intension for the shift control of an A/T during auto-cruise control.



Signal relationship between PV_AV_CAN and TPS in DIESEL system :

In a diesel engine vehicle which has an ETC system, basically TPS has APS value. And if auto cruise control is activated then both TPS and PV_AV_CAN should have modeling value which is estimated according to the actual fuel injection and other factors that affect engine torque.";
BA_ "UserSigValidity" SG_ 2214658050 ENG_AccelPdlVal 3;
BA_ "RoutingFactor" SG_ 2214658050 ENG_AccelPdlVal 5;
BA_ "Version" SG_ 2214658050 ENG_AccelPdlVal "18.01.01";
BA_ "Description" SG_ 2214658050 ENG_AccActSta "EMS sends the state of the cruise control via the signal ACC_ACT. 

If the EMS does not support this signal the value is 00H



If the cruise control is activated then ACC_ACT = 1. In this period, vehicle speed control (cruise control) is performed by the auto-cruise control function of ECU only (including acceleration control, deceleration control, etc.). 

Although ¡°SCC set¡± switch is on (Cruise control is enabled), if the cruise control function is deactivated (e.g. when a driver presses an accel. pedal or a brake pedal to increase or to decarese vcehicle speed more or less than set speed) then ACC_ACT should be set to ¡®0¡¯.";
BA_ "UserSigValidity" SG_ 2214658050 ENG_AccActSta 3;
BA_ "RoutingFactor" SG_ 2214658050 ENG_AccActSta 5;
BA_ "Version" SG_ 2214658050 ENG_AccActSta "17.12.00";
BA_ "Description" SG_ 2214658050 ACC_CrsMainSwLmpSta "This signal indicates that an ECU requests cluster to turn on/off auto-cruise control ¡°MAIN¡± switch indication lamp.



This signal is for the CAN-type cluster installed vehicled only.";
BA_ "UserSigValidity" SG_ 2214658050 ACC_CrsMainSwLmpSta 3;
BA_ "RoutingFactor" SG_ 2214658050 ACC_CrsMainSwLmpSta 5;
BA_ "Version" SG_ 2214658050 ACC_CrsMainSwLmpSta "17.12.00";
BA_ "Description" SG_ 2214658050 ACC_CrsSetSwLmpSta "This signal indicates that an ECU requests cluster to turn on/off auto-cruise control ¡°SET¡± switch indication lamp.



This signal is for the CAN-type cluster installed vehicled only.";
BA_ "UserSigValidity" SG_ 2214658050 ACC_CrsSetSwLmpSta 3;
BA_ "RoutingFactor" SG_ 2214658050 ACC_CrsSetSwLmpSta 5;
BA_ "Version" SG_ 2214658050 ACC_CrsSetSwLmpSta "17.12.00";
BA_ "Description" SG_ 2214658050 ENG_LV_FUP_ENA_THD "The signal indicates that the status of the pressure on fuel rail is enough high to start engine.

(LPI)";
BA_ "UserSigValidity" SG_ 2214658050 ENG_LV_FUP_ENA_THD 3;
BA_ "RoutingFactor" SG_ 2214658050 ENG_LV_FUP_ENA_THD 5;
BA_ "Version" SG_ 2214658050 ENG_LV_FUP_ENA_THD "18.12.01";
BA_ "Description" SG_ 2214658050 ENG_SoakTimeErrSta "This signal indicates that information on soak time error.";
BA_ "UserSigValidity" SG_ 2214658050 ENG_SoakTimeErrSta 3;
BA_ "RoutingFactor" SG_ 2214658050 ENG_SoakTimeErrSta 5;
BA_ "Version" SG_ 2214658050 ENG_SoakTimeErrSta "17.12.00";
BA_ "Description" SG_ 2214658050 ENG_SoakTimeVal "The Signal SOAK_TIME means the duration from Engine Ignition Off to Ignition On.";
BA_ "UserSigValidity" SG_ 2214658050 ENG_SoakTimeVal 3;
BA_ "RoutingFactor" SG_ 2214658050 ENG_SoakTimeVal 5;
BA_ "Version" SG_ 2214658050 ENG_SoakTimeVal "17.12.00";
BA_ "Description" SG_ 2214658050 ENG_SprkTimeVal "This signal indicates output value of final spark timing from ECU which reflects torque intervention requests by ESC(TCS), SCC and TCU.



Physical range:

-35.625¢ª ¡¦ 0¢ª  =  00H .. 5FH (Retard)

0.375¢ª ¡¦ 60¢ª  =  60H .. FFH (Advance) 



Conversion:  (PH)=((HEX)-5FH) * 0.375 [¢ª ] (Advance)

(PH)=(5FH-(HEX)) *(- 0.375) [¢ª ] (Retard)";
BA_ "UserSigValidity" SG_ 2214658050 ENG_SprkTimeVal 3;
BA_ "RoutingFactor" SG_ 2214658050 ENG_SprkTimeVal 5;
BA_ "Version" SG_ 2214658050 ENG_SprkTimeVal "17.12.00";
BA_ "Description" SG_ 2214658050 ENG_CltchOpSta "This signal indicates that ECU has detected an operation of a clutch. Using this signal an ISG (Idle Stop & Go) system acts as an alternator or a starter.



If the EMS does not support this signal the value is 00H";
BA_ "UserSigValidity" SG_ 2214658050 ENG_CltchOpSta 3;
BA_ "RoutingFactor" SG_ 2214658050 ENG_CltchOpSta 5;
BA_ "Version" SG_ 2214658050 ENG_CltchOpSta "17.12.00";
BA_ "Description" SG_ 2214658050 EMS_BrkReq_Slope "Brake request at slope for anti-stall";
BA_ "UserSigValidity" SG_ 2214658050 EMS_BrkReq_Slope 3;
BA_ "RoutingFactor" SG_ 2214658050 EMS_BrkReq_Slope 5;
BA_ "Version" SG_ 2214658050 EMS_BrkReq_Slope "20.04.06";
BA_ "GenMsgSendType" BO_ 2214658051 0;
BA_ "GenMsgCycleTime" BO_ 2214658051 50;
BA_ "GenMsgCycleTimeFast" BO_ 2214658051 0;
BA_ "GenMsgNrOfRepetition" BO_ 2214658051 0;
BA_ "VFrameFormat" BO_ 2214658051 1;
BA_ "Description" SG_ 2214658051 ENG_MinIndTqVal "The signal TQI_MIN is the minimum engine torque (minimum air charging rate) which can be fired without misfire including compensation factors such as atmospheric pressure and temperature.

It is not enough to keep the engine running without external power such as inertia.

Firing is impossible below TQI_MIN even if engine is turning by inertia. The friction torque is

always greater than TQI_MIN which is almost constant value across engine RPM.

This signal is used to determine when activation of automatic braking is required to achieve a certain deceleration or if the engine deceleration is sufficient under current conditions.



Under normal driving conditions the physical value of this signal is negative:

TQ_MIN[Nm] = TQI_MIN[Nm] - TQFR[Nm]



If MSB is 1, this signal is - value.

else, this signal is +value.

0~10bit is used for absolute value.";
BA_ "UserSigValidity" SG_ 2214658051 ENG_MinIndTqVal 3;
BA_ "RoutingFactor" SG_ 2214658051 ENG_MinIndTqVal 5;
BA_ "Version" SG_ 2214658051 ENG_MinIndTqVal "18.01.01";
BA_ "Description" SG_ 2214658051 ENG_TrgtTqVal "The signal TQI_TARGET is determined by an engine torque map with input which consists of  acceleration pedal value, MAF sensor, current RPM and etc. This signal reflects driver¡¯s demand directly. 

But it does not depend on torque interventions realised due to reduction of airflow into the engine cylinders and due to ignition angle adjustment or injection/cylinder shut off.



In case of failures of the load signal (either MAF error or other errors depending on the system congiguration), a backup value is generated from specific index tables. The backup value mode is identified by the signal F_SUB_TQI. 



There is a specific phase relationship between the signals TQI_TARGET and F_SUB_TQI.



If MSB is 1, this signal is - value.

else, this signal is +value.

0~10bit is used for absolute value.";
BA_ "UserSigValidity" SG_ 2214658051 ENG_TrgtTqVal 3;
BA_ "RoutingFactor" SG_ 2214658051 ENG_TrgtTqVal 5;
BA_ "Version" SG_ 2214658051 ENG_TrgtTqVal "18.01.01";
BA_ "Description" SG_ 2214658051 ENG_MaxIndTqVal "The signal TQI_MAX is the current maximum indicated engine torque. This signal reflects the maximum engine torque under current conditions (engine speed, etc¡¦).



Note : TQI_MAX must be transmitted actual engine torque including COT, thermal/spark efficiency etc..

 This means that the TQI_ACOR can reach to the TQI_MAX.

 If not possible, thTQI_MAX should be ¡° FFH¡± (99.6%) to reduce TCS/ESC variant.



TQ_MAX[Nm] = TQI_MAX[Nm] - TQFR[Nm]



If MSB is 1, this signal is - value.

else, this signal is +value.

0~10bit is used for absolute value.";
BA_ "UserSigValidity" SG_ 2214658051 ENG_MaxIndTqVal 3;
BA_ "RoutingFactor" SG_ 2214658051 ENG_MaxIndTqVal 5;
BA_ "Version" SG_ 2214658051 ENG_MaxIndTqVal "18.01.01";
BA_ "Description" SG_ 2214658051 ENG_AppAccelPdlSta "This signal indicates if the driver applies the accelerator pedal. 

The signal always indicates the actual operation of the accelerator pedal, independent from SCC mode.";
BA_ "UserSigValidity" SG_ 2214658051 ENG_AppAccelPdlSta 3;
BA_ "RoutingFactor" SG_ 2214658051 ENG_AppAccelPdlSta 5;
BA_ "Version" SG_ 2214658051 ENG_AppAccelPdlSta "17.12.00";
BA_ "Description" SG_ 2214658051 ENG_BrkCtrlReq "This signal indicates that if brake control request during cruise control or speed limiter is active or not. This signal is for prevention of unwanted vehicle speed increase during cruise control or speed limiter control mode.";
BA_ "UserSigValidity" SG_ 2214658051 ENG_BrkCtrlReq 3;
BA_ "RoutingFactor" SG_ 2214658051 ENG_BrkCtrlReq 5;
BA_ "Version" SG_ 2214658051 ENG_BrkCtrlReq "17.12.00";
BA_ "Description" SG_ 2214658051 ACC_DnShftCtrlReq "This signal indicates target gear for downshift control request during cruise control or speed limiter is active or not. This signal is for prevention of unwanted vehicle speed increase during cruise control or speed limiter control mode.";
BA_ "UserSigValidity" SG_ 2214658051 ACC_DnShftCtrlReq 3;
BA_ "RoutingFactor" SG_ 2214658051 ACC_DnShftCtrlReq 5;
BA_ "Version" SG_ 2214658051 ACC_DnShftCtrlReq "17.12.00";
BA_ "GenMsgSendType" BO_ 2214658052 0;
BA_ "GenMsgCycleTime" BO_ 2214658052 50;
BA_ "GenMsgCycleTimeFast" BO_ 2214658052 0;
BA_ "GenMsgNrOfRepetition" BO_ 2214658052 0;
BA_ "VFrameFormat" BO_ 2214658052 1;
BA_ "Description" SG_ 2214658052 ENG_DclBrkCntrlReq "When current vehicle speed goes over set vehicle speed in the downhill during cruise control or speed limiter, ECU requests brake control to TCS with target deceleration. This is function of (Current vehicle speed - Set vehicle speed).";
BA_ "GenSigStartValue" SG_ 2214658052 ENG_DclBrkCntrlReq 4094;
BA_ "UserSigValidity" SG_ 2214658052 ENG_DclBrkCntrlReq 3;
BA_ "RoutingFactor" SG_ 2214658052 ENG_DclBrkCntrlReq 5;
BA_ "Version" SG_ 2214658052 ENG_DclBrkCntrlReq "17.12.00";
BA_ "Description" SG_ 2214658052 ENG_BstPrsrVal "Boost pressure for Turbo engine";
BA_ "UserSigValidity" SG_ 2214658052 ENG_BstPrsrVal 3;
BA_ "RoutingFactor" SG_ 2214658052 ENG_BstPrsrVal 5;
BA_ "Version" SG_ 2214658052 ENG_BstPrsrVal "17.12.00";
BA_ "Description" SG_ 2214658052 ENG_EngOilTempVal "engine oil temperature";
BA_ "GenSigStartValue" SG_ 2214658052 ENG_EngOilTempVal 53;
BA_ "UserSigValidity" SG_ 2214658052 ENG_EngOilTempVal 3;
BA_ "RoutingFactor" SG_ 2214658052 ENG_EngOilTempVal 5;
BA_ "Version" SG_ 2214658052 ENG_EngOilTempVal "17.12.00";
BA_ "Description" SG_ 2214658052 ENG_AmbtTempModelVal "Modeled Ambient temperature";
BA_ "GenSigStartValue" SG_ 2214658052 ENG_AmbtTempModelVal 164;
BA_ "UserSigValidity" SG_ 2214658052 ENG_AmbtTempModelVal 3;
BA_ "RoutingFactor" SG_ 2214658052 ENG_AmbtTempModelVal 5;
BA_ "Version" SG_ 2214658052 ENG_AmbtTempModelVal "17.12.00";
BA_ "Description" SG_ 2214658052 ENG_DpfWrngSta "The signal indicates the status of the 'DPF Warning Level'";
BA_ "UserSigValidity" SG_ 2214658052 ENG_DpfWrngSta 3;
BA_ "RoutingFactor" SG_ 2214658052 ENG_DpfWrngSta 5;
BA_ "Version" SG_ 2214658052 ENG_DpfWrngSta "17.12.00";
BA_ "Description" SG_ 2214658052 ENG_BattWrngLmpSta "The signal indicates the status of the 'Battery Warning Lamp'";
BA_ "UserSigValidity" SG_ 2214658052 ENG_BattWrngLmpSta 3;
BA_ "RoutingFactor" SG_ 2214658052 ENG_BattWrngLmpSta 5;
BA_ "Version" SG_ 2214658052 ENG_BattWrngLmpSta "17.12.00";
BA_ "Description" SG_ 2214658052 ENG_OilPrsrWrngLmpSta "The signal indicates the status of the 'Oil Pressure Warning Lamp'";
BA_ "UserSigValidity" SG_ 2214658052 ENG_OilPrsrWrngLmpSta 3;
BA_ "RoutingFactor" SG_ 2214658052 ENG_OilPrsrWrngLmpSta 5;
BA_ "Version" SG_ 2214658052 ENG_OilPrsrWrngLmpSta "17.12.00";
BA_ "Description" SG_ 2214658052 ENG_IsgInhbtLmpSta "The signal indicates the status of the 'ISG Inhibit Lamp'";
BA_ "UserSigValidity" SG_ 2214658052 ENG_IsgInhbtLmpSta 3;
BA_ "RoutingFactor" SG_ 2214658052 ENG_IsgInhbtLmpSta 5;
BA_ "Version" SG_ 2214658052 ENG_IsgInhbtLmpSta "17.12.00";
BA_ "GenMsgSendType" BO_ 1048 0;
BA_ "Description" SG_ 1048 ICU_Crc8Val "The data area for CRC calculation is based on the data length (DLC) of the message DB.

The CRC shall be calculated over the entire data block (excluding the CRC bytes) including the user data, alive counter and Data ID 

 

- CRC Polynomial (0x1D) , Initial Value : 0x00, XOR value : 0xFF, Data ID Mode : Both, Data ID : Message ID + 0xF800 

- The initial value is for CRC calculation and the message should be sent with the calculated result value. 

The mathematical expression to 8 bit CRC polynomial is given here. G(x) = x8 + x4 + x3 + x2 + 1";
BA_ "GenSigSendType" SG_ 1048 ICU_Crc8Val 4;
BA_ "GenSigStartValue" SG_ 1048 ICU_Crc8Val 255;
BA_ "UserSigValidity" SG_ 1048 ICU_Crc8Val 0;
BA_ "Version" SG_ 1048 ICU_Crc8Val "18.11.08";
BA_ "Description" SG_ 1048 ICU_AlvCnt8Val "For the first transmission request for a data element the counter shall be initialized with 0 and shall be incremented by 1

for every subsequent send request. When the counter reaches the maximum value(0xE), then it shall restart with 0 for the next send request";
BA_ "GenSigSendType" SG_ 1048 ICU_AlvCnt8Val 4;
BA_ "UserSigValidity" SG_ 1048 ICU_AlvCnt8Val 0;
BA_ "Version" SG_ 1048 ICU_AlvCnt8Val "18.11.08";
BA_ "Description" SG_ 1048 DriveTypeOption "Drive Type Option

This signal is used to determine driver's seat position('Drive Type') about this vehicle.";
BA_ "GenSigSendType" SG_ 1048 DriveTypeOption 4;
BA_ "UserSigValidity" SG_ 1048 DriveTypeOption 0;
BA_REL_ "GenSigTimeoutTime" BU_SG_REL_ APSU SG_ 1048 DriveTypeOption 1500;
BA_REL_ "GenSigTimeoutTime" BU_SG_REL_ SHVU_FR SG_ 1048 DriveTypeOption 1500;
BA_REL_ "GenSigTimeoutTime" BU_SG_REL_ SHVU_RR SG_ 1048 DriveTypeOption 1500;
BA_REL_ "GenSigTimeoutTime" BU_SG_REL_ DPSU SG_ 1048 DriveTypeOption 1500;
BA_REL_ "GenSigTimeoutTime" BU_SG_REL_ DLBCU SG_ 1048 DriveTypeOption 1500;
BA_REL_ "GenSigTimeoutTime" BU_SG_REL_ ATS SG_ 1048 DriveTypeOption 1500;
BA_ "NetworkRequest" SG_ 1048 DriveTypeOption 0;
BA_ "NetworkRequestHoldingTime" SG_ 1048 DriveTypeOption 5000;
BA_ "Version" SG_ 1048 DriveTypeOption "17.12.00";
BA_ "Description" SG_ 1048 Warn_RrLftSBRMATSwSta "Rear Left Seated State";
BA_ "GenSigSendType" SG_ 1048 Warn_RrLftSBRMATSwSta 4;
BA_ "UserSigValidity" SG_ 1048 Warn_RrLftSBRMATSwSta 0;
BA_ "NetworkRequest" SG_ 1048 Warn_RrLftSBRMATSwSta 0;
BA_ "NetworkRequestHoldingTime" SG_ 1048 Warn_RrLftSBRMATSwSta 5000;
BA_ "Version" SG_ 1048 Warn_RrLftSBRMATSwSta "17.12.00";
BA_ "Description" SG_ 1048 Warn_RrRhtSBRMATSwSta "Rear Right Seated State";
BA_ "GenSigSendType" SG_ 1048 Warn_RrRhtSBRMATSwSta 4;
BA_ "UserSigValidity" SG_ 1048 Warn_RrRhtSBRMATSwSta 0;
BA_ "NetworkRequest" SG_ 1048 Warn_RrRhtSBRMATSwSta 0;
BA_ "NetworkRequestHoldingTime" SG_ 1048 Warn_RrRhtSBRMATSwSta 5000;
BA_ "Version" SG_ 1048 Warn_RrRhtSBRMATSwSta "17.12.00";
BA_ "Description" SG_ 1048 Lamp_FootLampOnReq "Foot Lamp Command";
BA_ "GenSigSendType" SG_ 1048 Lamp_FootLampOnReq 4;
BA_ "UserSigValidity" SG_ 1048 Lamp_FootLampOnReq 0;
BA_ "NetworkRequest" SG_ 1048 Lamp_FootLampOnReq 0;
BA_ "NetworkRequestHoldingTime" SG_ 1048 Lamp_FootLampOnReq 5000;
BA_ "Version" SG_ 1048 Lamp_FootLampOnReq "17.12.00";
BA_ "Description" SG_ 1048 Lamp_MoodLampOnReq "Mood lamp command";
BA_ "GenSigSendType" SG_ 1048 Lamp_MoodLampOnReq 4;
BA_ "UserSigValidity" SG_ 1048 Lamp_MoodLampOnReq 0;
BA_ "NetworkRequest" SG_ 1048 Lamp_MoodLampOnReq 0;
BA_ "NetworkRequestHoldingTime" SG_ 1048 Lamp_MoodLampOnReq 5000;
BA_ "Version" SG_ 1048 Lamp_MoodLampOnReq "21.07.05";
BA_ "Description" SG_ 1048 ICU_PowerAutoCutModSta "ICU Delivery Mode State";
BA_ "GenSigSendType" SG_ 1048 ICU_PowerAutoCutModSta 4;
BA_ "UserSigValidity" SG_ 1048 ICU_PowerAutoCutModSta 3;
BA_REL_ "GenSigTimeoutTime" BU_SG_REL_ APSU SG_ 1048 ICU_PowerAutoCutModSta 1500;
BA_REL_ "GenSigTimeoutTime" BU_SG_REL_ RLHV SG_ 1048 ICU_PowerAutoCutModSta 1500;
BA_REL_ "GenSigTimeoutTime" BU_SG_REL_ RRHV SG_ 1048 ICU_PowerAutoCutModSta 1500;
BA_REL_ "GenSigTimeoutTime" BU_SG_REL_ DPSU SG_ 1048 ICU_PowerAutoCutModSta 1500;
BA_REL_ "GenSigTimeoutTime" BU_SG_REL_ RRPSU SG_ 1048 ICU_PowerAutoCutModSta 1500;
BA_REL_ "GenSigTimeoutTime" BU_SG_REL_ RLPSU SG_ 1048 ICU_PowerAutoCutModSta 1500;
BA_REL_ "GenSigTimeoutTime" BU_SG_REL_ BLTN_CAM SG_ 1048 ICU_PowerAutoCutModSta 1500;
BA_ "Version" SG_ 1048 ICU_PowerAutoCutModSta "17.12.00";
BA_ "Description" SG_ 1048 ICU_SoCBattStaMsgReq "Determine if soc level is warning or alert.";
BA_ "GenSigSendType" SG_ 1048 ICU_SoCBattStaMsgReq 4;
BA_ "GenSigStartValue" SG_ 1048 ICU_SoCBattStaMsgReq 3;
BA_ "UserSigValidity" SG_ 1048 ICU_SoCBattStaMsgReq 0;
BA_ "Version" SG_ 1048 ICU_SoCBattStaMsgReq "17.12.00";
BA_ "Description" SG_ 1048 Brake_SwSta_ICU "Brake Switch Status";
BA_ "GenSigSendType" SG_ 1048 Brake_SwSta_ICU 4;
BA_ "UserSigValidity" SG_ 1048 Brake_SwSta_ICU 0;
BA_ "NetworkRequest" SG_ 1048 Brake_SwSta_ICU 0;
BA_ "NetworkRequestHoldingTime" SG_ 1048 Brake_SwSta_ICU 5000;
BA_ "Version" SG_ 1048 Brake_SwSta_ICU "21.07.05";
BA_ "Description" SG_ 1048 C_3rdRCSeatBeltSW "3rd Rear Center Seat Belt Switch Status";
BA_ "GenSigSendType" SG_ 1048 C_3rdRCSeatBeltSW 4;
BA_ "UserSigValidity" SG_ 1048 C_3rdRCSeatBeltSW 0;
BA_REL_ "GenSigTimeoutTime" BU_SG_REL_ RRPSU SG_ 1048 C_3rdRCSeatBeltSW 1500;
BA_REL_ "GenSigTimeoutTime" BU_SG_REL_ RLPSU SG_ 1048 C_3rdRCSeatBeltSW 1500;
BA_ "NetworkRequest" SG_ 1048 C_3rdRCSeatBeltSW 0;
BA_ "NetworkRequestHoldingTime" SG_ 1048 C_3rdRCSeatBeltSW 5000;
BA_ "Version" SG_ 1048 C_3rdRCSeatBeltSW "18.03.04";
BA_ "Description" SG_ 1048 C_3rdRRSBRMatSw "3rd Rear Right Seated State



-Default value: 0x0 (¹ÌÅ¾½Â)

-Initial value: 0x0 (¹ÌÅ¾½Â)

-Timeout value: 0x0 (¹ÌÅ¾½Â)";
BA_ "GenSigSendType" SG_ 1048 C_3rdRRSBRMatSw 4;
BA_ "UserSigValidity" SG_ 1048 C_3rdRRSBRMatSw 0;
BA_REL_ "GenSigTimeoutTime" BU_SG_REL_ RRPSU SG_ 1048 C_3rdRRSBRMatSw 1500;
BA_REL_ "GenSigTimeoutTime" BU_SG_REL_ RLPSU SG_ 1048 C_3rdRRSBRMatSw 1500;
BA_ "NetworkRequest" SG_ 1048 C_3rdRRSBRMatSw 0;
BA_ "NetworkRequestHoldingTime" SG_ 1048 C_3rdRRSBRMatSw 5000;
BA_ "Version" SG_ 1048 C_3rdRRSBRMatSw "18.03.04";
BA_ "Description" SG_ 1048 C_3rdRLSBRMatSw "3rd Rear Left Seated State



-Default value: 0x0 (¹ÌÅ¾½Â)

-Initial value: 0x0 (¹ÌÅ¾½Â)

-Timeout value: 0x0 (¹ÌÅ¾½Â)";
BA_ "GenSigSendType" SG_ 1048 C_3rdRLSBRMatSw 4;
BA_ "UserSigValidity" SG_ 1048 C_3rdRLSBRMatSw 0;
BA_REL_ "GenSigTimeoutTime" BU_SG_REL_ RLPSU SG_ 1048 C_3rdRLSBRMatSw 1500;
BA_ "NetworkRequest" SG_ 1048 C_3rdRLSBRMatSw 0;
BA_ "NetworkRequestHoldingTime" SG_ 1048 C_3rdRLSBRMatSw 5000;
BA_ "Version" SG_ 1048 C_3rdRLSBRMatSw "18.03.04";
BA_ "Description" SG_ 1048 C_3rdRRSeatBeltSW "3rd Rear Right Seat Belt Switch Status";
BA_ "GenSigSendType" SG_ 1048 C_3rdRRSeatBeltSW 4;
BA_ "UserSigValidity" SG_ 1048 C_3rdRRSeatBeltSW 0;
BA_REL_ "GenSigTimeoutTime" BU_SG_REL_ RRPSU SG_ 1048 C_3rdRRSeatBeltSW 1500;
BA_REL_ "GenSigTimeoutTime" BU_SG_REL_ RLPSU SG_ 1048 C_3rdRRSeatBeltSW 1500;
BA_ "NetworkRequest" SG_ 1048 C_3rdRRSeatBeltSW 0;
BA_ "NetworkRequestHoldingTime" SG_ 1048 C_3rdRRSeatBeltSW 5000;
BA_ "Version" SG_ 1048 C_3rdRRSeatBeltSW "18.03.04";
BA_ "Description" SG_ 1048 C_3rdRLSeatBeltSW "3rd Rear Left Seat Belt Switch Status";
BA_ "GenSigSendType" SG_ 1048 C_3rdRLSeatBeltSW 4;
BA_ "UserSigValidity" SG_ 1048 C_3rdRLSeatBeltSW 0;
BA_REL_ "GenSigTimeoutTime" BU_SG_REL_ RRPSU SG_ 1048 C_3rdRLSeatBeltSW 1500;
BA_REL_ "GenSigTimeoutTime" BU_SG_REL_ RLPSU SG_ 1048 C_3rdRLSeatBeltSW 1500;
BA_ "NetworkRequest" SG_ 1048 C_3rdRLSeatBeltSW 0;
BA_ "NetworkRequestHoldingTime" SG_ 1048 C_3rdRLSeatBeltSW 5000;
BA_ "Version" SG_ 1048 C_3rdRLSeatBeltSW "18.03.04";
BA_ "Description" SG_ 1048 HSWS_SysWrngSta_ICU "0x0 : Normal

0x1 : System Fail

0x2 : Reserved

0x3 : Invalid";
BA_ "GenSigSendType" SG_ 1048 HSWS_SysWrngSta_ICU 4;
BA_ "UserSigValidity" SG_ 1048 HSWS_SysWrngSta_ICU 4;
BA_ "Version" SG_ 1048 HSWS_SysWrngSta_ICU "17.12.00";
BA_ "GenMsgCycleTime" BO_ 1616 0;
BA_ "GenSigSendType" SG_ 1616 MKBD_IllumiState 4;
BA_ "GenSigStartValue" SG_ 1616 MKBD_IllumiState 3;
BA_ "UserSigValidity" SG_ 1616 MKBD_IllumiState 1;
BA_ "Version" SG_ 1616 MKBD_IllumiState "20.04.02";
BA_ "Description" SG_ 1616 MKBD_SeatKeySet "The signal for transmitting Seat Key inputs from MKBD to Seat ECU

Release : 0x0 / Press : 0x1";
BA_ "GenSigSendType" SG_ 1616 MKBD_SeatKeySet 4;
BA_ "GenSigStartValue" SG_ 1616 MKBD_SeatKeySet 3;
BA_ "UserSigValidity" SG_ 1616 MKBD_SeatKeySet 3;
BA_REL_ "GenSigTimeoutTime" BU_SG_REL_ APSU SG_ 1616 MKBD_SeatKeySet 0;
BA_REL_ "GenSigTimeoutTime" BU_SG_REL_ SHVU_FR SG_ 1616 MKBD_SeatKeySet 0;
BA_REL_ "GenSigTimeoutTime" BU_SG_REL_ DPSU SG_ 1616 MKBD_SeatKeySet 0;
BA_ "Version" SG_ 1616 MKBD_SeatKeySet "20.06.07";
BA_ "GenMsgCycleTime" BO_ 1578 0;
BA_ "GenMsgILSupport" BO_ 1578 0;
BA_ "TpMessage" BO_ 1578 1;
BA_ "GenMsgDelayTime" BO_ 1578 10;
BA_ "UsrSigPurpose" SG_ 1578 PSB_CCP_CRO_Byte0 0;
BA_ "GenSigSendType" SG_ 1578 PSB_CCP_CRO_Byte0 2;
BA_ "UserSigValidity" SG_ 1578 PSB_CCP_CRO_Byte0 0;
BA_REL_ "GenSigTimeoutTime" BU_SG_REL_ PSB SG_ 1578 PSB_CCP_CRO_Byte0 0;
BA_ "NetworkRequest" SG_ 1578 PSB_CCP_CRO_Byte0 0;
BA_ "NetworkRequestHoldingTime" SG_ 1578 PSB_CCP_CRO_Byte0 5000;
BA_ "Version" SG_ 1578 PSB_CCP_CRO_Byte0 "21.02.04";
BA_ "UsrSigPurpose" SG_ 1578 PSB_CCP_CRO_Byte2 0;
BA_ "GenSigSendType" SG_ 1578 PSB_CCP_CRO_Byte2 2;
BA_ "UserSigValidity" SG_ 1578 PSB_CCP_CRO_Byte2 0;
BA_REL_ "GenSigTimeoutTime" BU_SG_REL_ PSB SG_ 1578 PSB_CCP_CRO_Byte2 0;
BA_ "NetworkRequest" SG_ 1578 PSB_CCP_CRO_Byte2 0;
BA_ "NetworkRequestHoldingTime" SG_ 1578 PSB_CCP_CRO_Byte2 5000;
BA_ "Version" SG_ 1578 PSB_CCP_CRO_Byte2 "21.02.04";
BA_ "UsrSigPurpose" SG_ 1578 PSB_CCP_CRO_Byte3 0;
BA_ "GenSigSendType" SG_ 1578 PSB_CCP_CRO_Byte3 2;
BA_ "UserSigValidity" SG_ 1578 PSB_CCP_CRO_Byte3 0;
BA_REL_ "GenSigTimeoutTime" BU_SG_REL_ PSB SG_ 1578 PSB_CCP_CRO_Byte3 0;
BA_ "NetworkRequest" SG_ 1578 PSB_CCP_CRO_Byte3 0;
BA_ "NetworkRequestHoldingTime" SG_ 1578 PSB_CCP_CRO_Byte3 5000;
BA_ "Version" SG_ 1578 PSB_CCP_CRO_Byte3 "21.02.04";
BA_ "UsrSigPurpose" SG_ 1578 PSB_CCP_CRO_Byte4 0;
BA_ "GenSigSendType" SG_ 1578 PSB_CCP_CRO_Byte4 2;
BA_ "UserSigValidity" SG_ 1578 PSB_CCP_CRO_Byte4 0;
BA_REL_ "GenSigTimeoutTime" BU_SG_REL_ PSB SG_ 1578 PSB_CCP_CRO_Byte4 0;
BA_ "NetworkRequest" SG_ 1578 PSB_CCP_CRO_Byte4 0;
BA_ "NetworkRequestHoldingTime" SG_ 1578 PSB_CCP_CRO_Byte4 5000;
BA_ "Version" SG_ 1578 PSB_CCP_CRO_Byte4 "21.02.04";
BA_ "UsrSigPurpose" SG_ 1578 PSB_CCP_CRO_Byte5 0;
BA_ "GenSigSendType" SG_ 1578 PSB_CCP_CRO_Byte5 2;
BA_ "UserSigValidity" SG_ 1578 PSB_CCP_CRO_Byte5 0;
BA_REL_ "GenSigTimeoutTime" BU_SG_REL_ PSB SG_ 1578 PSB_CCP_CRO_Byte5 0;
BA_ "NetworkRequest" SG_ 1578 PSB_CCP_CRO_Byte5 0;
BA_ "NetworkRequestHoldingTime" SG_ 1578 PSB_CCP_CRO_Byte5 5000;
BA_ "Version" SG_ 1578 PSB_CCP_CRO_Byte5 "21.02.04";
BA_ "UsrSigPurpose" SG_ 1578 PSB_CCP_CRO_Byte6 0;
BA_ "GenSigSendType" SG_ 1578 PSB_CCP_CRO_Byte6 2;
BA_ "UserSigValidity" SG_ 1578 PSB_CCP_CRO_Byte6 0;
BA_REL_ "GenSigTimeoutTime" BU_SG_REL_ PSB SG_ 1578 PSB_CCP_CRO_Byte6 0;
BA_ "NetworkRequest" SG_ 1578 PSB_CCP_CRO_Byte6 0;
BA_ "NetworkRequestHoldingTime" SG_ 1578 PSB_CCP_CRO_Byte6 5000;
BA_ "Version" SG_ 1578 PSB_CCP_CRO_Byte6 "21.02.04";
BA_ "UsrSigPurpose" SG_ 1578 PSB_CCP_CRO_Byte7 0;
BA_ "GenSigSendType" SG_ 1578 PSB_CCP_CRO_Byte7 2;
BA_ "UserSigValidity" SG_ 1578 PSB_CCP_CRO_Byte7 0;
BA_REL_ "GenSigTimeoutTime" BU_SG_REL_ PSB SG_ 1578 PSB_CCP_CRO_Byte7 0;
BA_ "NetworkRequest" SG_ 1578 PSB_CCP_CRO_Byte7 0;
BA_ "NetworkRequestHoldingTime" SG_ 1578 PSB_CCP_CRO_Byte7 5000;
BA_ "Version" SG_ 1578 PSB_CCP_CRO_Byte7 "21.02.04";
BA_ "UsrSigPurpose" SG_ 1578 PSB_CCP_CRO_Byte1 0;
BA_ "GenSigSendType" SG_ 1578 PSB_CCP_CRO_Byte1 2;
BA_ "UserSigValidity" SG_ 1578 PSB_CCP_CRO_Byte1 0;
BA_REL_ "GenSigTimeoutTime" BU_SG_REL_ PSB SG_ 1578 PSB_CCP_CRO_Byte1 0;
BA_ "NetworkRequest" SG_ 1578 PSB_CCP_CRO_Byte1 0;
BA_ "NetworkRequestHoldingTime" SG_ 1578 PSB_CCP_CRO_Byte1 5000;
BA_ "Version" SG_ 1578 PSB_CCP_CRO_Byte1 "21.02.04";
BA_ "GenMsgCycleTime" BO_ 1579 0;
BA_ "GenMsgILSupport" BO_ 1579 0;
BA_ "TpMessage" BO_ 1579 1;
BA_ "GenMsgDelayTime" BO_ 1579 10;
BA_ "UsrSigPurpose" SG_ 1579 PSB_CCP_DTO_Byte0 0;
BA_ "GenSigSendType" SG_ 1579 PSB_CCP_DTO_Byte0 2;
BA_ "UserSigValidity" SG_ 1579 PSB_CCP_DTO_Byte0 0;
BA_REL_ "GenSigTimeoutTime" BU_SG_REL_ CGW_CCU SG_ 1579 PSB_CCP_DTO_Byte0 0;
BA_ "NetworkRequest" SG_ 1579 PSB_CCP_DTO_Byte0 0;
BA_ "NetworkRequestHoldingTime" SG_ 1579 PSB_CCP_DTO_Byte0 5000;
BA_ "Version" SG_ 1579 PSB_CCP_DTO_Byte0 "21.02.04";
BA_ "UsrSigPurpose" SG_ 1579 PSB_CCP_DTO_Byte2 0;
BA_ "GenSigSendType" SG_ 1579 PSB_CCP_DTO_Byte2 2;
BA_ "UserSigValidity" SG_ 1579 PSB_CCP_DTO_Byte2 0;
BA_REL_ "GenSigTimeoutTime" BU_SG_REL_ CGW_CCU SG_ 1579 PSB_CCP_DTO_Byte2 0;
BA_ "NetworkRequest" SG_ 1579 PSB_CCP_DTO_Byte2 0;
BA_ "NetworkRequestHoldingTime" SG_ 1579 PSB_CCP_DTO_Byte2 5000;
BA_ "Version" SG_ 1579 PSB_CCP_DTO_Byte2 "21.02.04";
BA_ "UsrSigPurpose" SG_ 1579 PSB_CCP_DTO_Byte3 0;
BA_ "GenSigSendType" SG_ 1579 PSB_CCP_DTO_Byte3 2;
BA_ "UserSigValidity" SG_ 1579 PSB_CCP_DTO_Byte3 0;
BA_REL_ "GenSigTimeoutTime" BU_SG_REL_ CGW_CCU SG_ 1579 PSB_CCP_DTO_Byte3 0;
BA_ "NetworkRequest" SG_ 1579 PSB_CCP_DTO_Byte3 0;
BA_ "NetworkRequestHoldingTime" SG_ 1579 PSB_CCP_DTO_Byte3 5000;
BA_ "Version" SG_ 1579 PSB_CCP_DTO_Byte3 "21.02.04";
BA_ "UsrSigPurpose" SG_ 1579 PSB_CCP_DTO_Byte4 0;
BA_ "GenSigSendType" SG_ 1579 PSB_CCP_DTO_Byte4 2;
BA_ "UserSigValidity" SG_ 1579 PSB_CCP_DTO_Byte4 0;
BA_REL_ "GenSigTimeoutTime" BU_SG_REL_ CGW_CCU SG_ 1579 PSB_CCP_DTO_Byte4 0;
BA_ "NetworkRequest" SG_ 1579 PSB_CCP_DTO_Byte4 0;
BA_ "NetworkRequestHoldingTime" SG_ 1579 PSB_CCP_DTO_Byte4 5000;
BA_ "Version" SG_ 1579 PSB_CCP_DTO_Byte4 "21.02.04";
BA_ "UsrSigPurpose" SG_ 1579 PSB_CCP_DTO_Byte5 0;
BA_ "GenSigSendType" SG_ 1579 PSB_CCP_DTO_Byte5 2;
BA_ "UserSigValidity" SG_ 1579 PSB_CCP_DTO_Byte5 0;
BA_REL_ "GenSigTimeoutTime" BU_SG_REL_ CGW_CCU SG_ 1579 PSB_CCP_DTO_Byte5 0;
BA_ "NetworkRequest" SG_ 1579 PSB_CCP_DTO_Byte5 0;
BA_ "NetworkRequestHoldingTime" SG_ 1579 PSB_CCP_DTO_Byte5 5000;
BA_ "Version" SG_ 1579 PSB_CCP_DTO_Byte5 "21.02.04";
BA_ "UsrSigPurpose" SG_ 1579 PSB_CCP_DTO_Byte6 0;
BA_ "GenSigSendType" SG_ 1579 PSB_CCP_DTO_Byte6 2;
BA_ "UserSigValidity" SG_ 1579 PSB_CCP_DTO_Byte6 0;
BA_REL_ "GenSigTimeoutTime" BU_SG_REL_ CGW_CCU SG_ 1579 PSB_CCP_DTO_Byte6 0;
BA_ "NetworkRequest" SG_ 1579 PSB_CCP_DTO_Byte6 0;
BA_ "NetworkRequestHoldingTime" SG_ 1579 PSB_CCP_DTO_Byte6 5000;
BA_ "Version" SG_ 1579 PSB_CCP_DTO_Byte6 "21.02.04";
BA_ "UsrSigPurpose" SG_ 1579 PSB_CCP_DTO_Byte7 0;
BA_ "GenSigSendType" SG_ 1579 PSB_CCP_DTO_Byte7 2;
BA_ "UserSigValidity" SG_ 1579 PSB_CCP_DTO_Byte7 0;
BA_REL_ "GenSigTimeoutTime" BU_SG_REL_ CGW_CCU SG_ 1579 PSB_CCP_DTO_Byte7 0;
BA_ "NetworkRequest" SG_ 1579 PSB_CCP_DTO_Byte7 0;
BA_ "NetworkRequestHoldingTime" SG_ 1579 PSB_CCP_DTO_Byte7 5000;
BA_ "Version" SG_ 1579 PSB_CCP_DTO_Byte7 "21.02.04";
BA_ "UsrSigPurpose" SG_ 1579 PSB_CCP_DTO_Byte1 0;
BA_ "GenSigSendType" SG_ 1579 PSB_CCP_DTO_Byte1 2;
BA_ "UserSigValidity" SG_ 1579 PSB_CCP_DTO_Byte1 0;
BA_REL_ "GenSigTimeoutTime" BU_SG_REL_ CGW_CCU SG_ 1579 PSB_CCP_DTO_Byte1 0;
BA_ "NetworkRequest" SG_ 1579 PSB_CCP_DTO_Byte1 0;
BA_ "NetworkRequestHoldingTime" SG_ 1579 PSB_CCP_DTO_Byte1 5000;
BA_ "Version" SG_ 1579 PSB_CCP_DTO_Byte1 "21.02.04";
BA_ "GenMsgSendType" BO_ 1027 0;
BA_ "GenSigSendType" SG_ 1027 Win_ElecChildLkSwOpt 4;
BA_ "UserSigValidity" SG_ 1027 Win_ElecChildLkSwOpt 0;
BA_ "NetworkRequest" SG_ 1027 Win_ElecChildLkSwOpt 0;
BA_ "NetworkRequestHoldingTime" SG_ 1027 Win_ElecChildLkSwOpt 5000;
BA_ "Version" SG_ 1027 Win_ElecChildLkSwOpt "20.12.05";
BA_ "GenSigSendType" SG_ 1027 Win_PwrWdwSwTyp 4;
BA_ "UserSigValidity" SG_ 1027 Win_PwrWdwSwTyp 0;
BA_ "NetworkRequest" SG_ 1027 Win_PwrWdwSwTyp 0;
BA_ "NetworkRequestHoldingTime" SG_ 1027 Win_PwrWdwSwTyp 5000;
BA_ "Version" SG_ 1027 Win_PwrWdwSwTyp "20.12.05";
BA_ "GenSigSendType" SG_ 1027 Win_DrvIMSSwSta 4;
BA_ "UserSigValidity" SG_ 1027 Win_DrvIMSSwSta 0;
BA_REL_ "GenSigTimeoutTime" BU_SG_REL_ DPSU SG_ 1027 Win_DrvIMSSwSta 1500;
BA_ "NetworkRequest" SG_ 1027 Win_DrvIMSSwSta 0;
BA_ "NetworkRequestHoldingTime" SG_ 1027 Win_DrvIMSSwSta 5000;
BA_ "Version" SG_ 1027 Win_DrvIMSSwSta "20.12.05";
BA_ "GenSigSendType" SG_ 1027 Win_DrvPwrWdwSwSta 4;
BA_ "UserSigValidity" SG_ 1027 Win_DrvPwrWdwSwSta 0;
BA_ "NetworkRequest" SG_ 1027 Win_DrvPwrWdwSwSta 0;
BA_ "NetworkRequestHoldingTime" SG_ 1027 Win_DrvPwrWdwSwSta 5000;
BA_ "Version" SG_ 1027 Win_DrvPwrWdwSwSta "20.12.05";
BA_ "GenSigSendType" SG_ 1027 Win_AsstPwrWdwSwSta 4;
BA_ "UserSigValidity" SG_ 1027 Win_AsstPwrWdwSwSta 0;
BA_ "NetworkRequest" SG_ 1027 Win_AsstPwrWdwSwSta 0;
BA_ "NetworkRequestHoldingTime" SG_ 1027 Win_AsstPwrWdwSwSta 5000;
BA_ "Version" SG_ 1027 Win_AsstPwrWdwSwSta "20.12.05";
BA_ "GenSigSendType" SG_ 1027 Win_CtrlDrLkSwSta 4;
BA_ "UserSigValidity" SG_ 1027 Win_CtrlDrLkSwSta 0;
BA_ "NetworkRequest" SG_ 1027 Win_CtrlDrLkSwSta 0;
BA_ "NetworkRequestHoldingTime" SG_ 1027 Win_CtrlDrLkSwSta 5000;
BA_ "Version" SG_ 1027 Win_CtrlDrLkSwSta "20.12.05";
BA_ "GenSigSendType" SG_ 1027 Win_RrLftPwrWdwSwSta 4;
BA_ "UserSigValidity" SG_ 1027 Win_RrLftPwrWdwSwSta 0;
BA_ "NetworkRequest" SG_ 1027 Win_RrLftPwrWdwSwSta 0;
BA_ "NetworkRequestHoldingTime" SG_ 1027 Win_RrLftPwrWdwSwSta 5000;
BA_ "Version" SG_ 1027 Win_RrLftPwrWdwSwSta "20.12.05";
BA_ "GenSigSendType" SG_ 1027 Win_RrRtPwrWdwSwSta 4;
BA_ "UserSigValidity" SG_ 1027 Win_RrRtPwrWdwSwSta 0;
BA_ "NetworkRequest" SG_ 1027 Win_RrRtPwrWdwSwSta 0;
BA_ "NetworkRequestHoldingTime" SG_ 1027 Win_RrRtPwrWdwSwSta 5000;
BA_ "Version" SG_ 1027 Win_RrRtPwrWdwSwSta "20.12.05";
BA_ "GenSigSendType" SG_ 1027 Win_CtrlDrUnLkSwSta 4;
BA_ "UserSigValidity" SG_ 1027 Win_CtrlDrUnLkSwSta 0;
BA_ "NetworkRequest" SG_ 1027 Win_CtrlDrUnLkSwSta 0;
BA_ "NetworkRequestHoldingTime" SG_ 1027 Win_CtrlDrUnLkSwSta 5000;
BA_ "Version" SG_ 1027 Win_CtrlDrUnLkSwSta "20.12.05";
BA_ "GenSigSendType" SG_ 1027 Win_PwrWdwLkSwSta 4;
BA_ "UserSigValidity" SG_ 1027 Win_PwrWdwLkSwSta 0;
BA_ "NetworkRequest" SG_ 1027 Win_PwrWdwLkSwSta 0;
BA_ "NetworkRequestHoldingTime" SG_ 1027 Win_PwrWdwLkSwSta 5000;
BA_ "Version" SG_ 1027 Win_PwrWdwLkSwSta "20.12.05";
BA_ "GenSigSendType" SG_ 1027 Win_RrCrtSwSta 4;
BA_ "UserSigValidity" SG_ 1027 Win_RrCrtSwSta 0;
BA_ "NetworkRequest" SG_ 1027 Win_RrCrtSwSta 0;
BA_ "NetworkRequestHoldingTime" SG_ 1027 Win_RrCrtSwSta 5000;
BA_ "Version" SG_ 1027 Win_RrCrtSwSta "20.12.05";
VAL_ 2223057409 LKA_OptUsmSta 0 "None LKA/LDW Option (Default)" 1 "LDW" 2 "LKA" 3 "Reserved" 4 "LDW Only (None LKA)" 5 "LDW only OFF (None LKA)" 6 "LDW/LKA OFF" 7 "Invalid" ;
VAL_ 2223057409 LKA_RcgSta 0 "Not Recognized" 1 "Left Lane Recognition" 2 "Right Lane Recognition" 3 "Full Lane Recognition" 4 "Reserved" 5 "Reserved" 6 "Reserved" 7 "Reserved" ;
VAL_ 2223057409 LKA_LHLnWrnSta 0 "No Warning" 1 "Lane Departure Warning" 2 "Reserved" 3 "Reserved" ;
VAL_ 2223057409 LKA_RHLnWrnSta 0 "No Warning" 1 "Lane Departure Warning" 2 "Reserved" 3 "Reserved" ;
VAL_ 2223057409 LKA_HndsoffSnd 0 "Off" 1 "Hands-off Sound Warning" 2 "Reserved" 3 "Reserved" ;
VAL_ 2223057409 LKA_SysIndReq 0 "Off" 1 "Unavailable_(Grey On)" 2 "Lane Recognized_(Green On)" 3 "Lane Departure_(Green Blink)" 4 "System Fail_(Orange On)" 5 "Not Calibrated_(Orange Blink)" 6 "Off for Regulation (Orange On)" 7 "Temp. Unavailable (Orange On)" ;
VAL_ 2223057409 ADAS_StrTqReqVal 0 "0x0x000~0x7FD:0~2045" 2045 "0x0x000~0x7FD:0~2045" 2046 "Reserved" 2047 "Invalid" ;
VAL_ 2223057409 ADAS_ActToiSta 0 "De-activate TOI" 1 "Activate TOI" 2 "Reserved" 3 "Error indicator" ;
VAL_ 2223057409 ADAS_ToiFltSta 0 "No Fault" 1 "Fault" 2 "Reserved" 3 "Error indicatorr" ;
VAL_ 2223057409 BCA_Rear_WrnSta 0 "No Warning" 1 "Left Warning" 2 "Right Warning" 3 "Left Control" 4 "Right Control" 5 "Reserved" 6 "Not used" 7 "Error indicator" ;
VAL_ 2223057409 LKA_SysWrn 0 "No Info" 1 "Reserved" 2 "Reserved" 3 "Reserved" 4 "Hands-Off Warning 1" 5 "Hands-Off Warning 2" 6 "Hands-Off Warning 3" 7 "Reserved" 8 "Reserved" 9 "System Automatic off" 10 "Reserved" 11 "Reserved" 12 "Reserved" 13 "Reserved" 14 "Blockage Warning" 15 "System Fail" ;
VAL_ 2273435649 HDA_OptUsmSta 0 "Not Applied" 1 "Function Off" 2 "Function On" 3 "Reserved" 4 "Reserved" 5 "Reserved" 6 "Reserved" 7 "Invalid (Fail)" ;
VAL_ 2273435649 HDA_CntrlModSta 0 "System OFF (Default)" 1 "System STANDBY" 2 "System ACTIVE" 3 "Reserved" ;
VAL_ 2273435649 HDA_InfoPUDis 0 "No pop-up" 1 "system start pop-up" 2 "system auto disengaged pop-up by highway off" 3 "System Fail pop up (LFA)" 4 "System Fail pop up (HDA)" 5 "Hands-off pop up" 6 "Hands-off pop up w/ sound" 7 "Reserved" ;
VAL_ 2273435649 HDP_AutoCallReqSta 0 "No request" 1 "HDP MRM Auto Call Request" 2 "Reserved" 3 "Reserved" 4 "Reserved" 5 "Reserved" 6 "Cancel the HDP Auto Call" 7 "Invalid" ;
VAL_ 2273435649 HDP_DispBarSta 0 "Not Display" 1 "Reserved" 2 "Reserved" 3 "Amber Display" 4 "Red Display" 5 "Reserved" 6 "Reserved" 7 "Reserved" 8 "Reserved" 9 "Reserved" 10 "Reserved" 11 "Reserved" 12 "Reserved" 13 "Reserved" 14 "Reserved" 15 "Reserved" ;
VAL_ 2273435649 HDP_OptInfoSta 0 "HDP option not applied" 1 "HDP option applied" 2 "Reserved" 3 "Reserved" ;
VAL_ 2273435649 HDA_LFA_SymSta 0 "Off" 1 "Gray" 2 "Green" 3 "White blink" ;
VAL_ 2273435649 HDA_LFA_WrnSnd 0 "Off" 1 "Additional Warning Sound" 2 "Reserved" 3 "Error indicator" ;
VAL_ 2273435649 HDA_InfoPUDis1 0 "No Pop-up" 1 "System Automatic off (LFA)" 2 "System Automatic off (HDA)" 3 "Reserved" 4 "Reserved" 5 "Reserved" 6 "Not Used" 7 "Error Indicator" ;
VAL_ 2273435649 HDA_TDMRMDclReq 0 "Not automatically deactivated state of LFA (default)" 1 "Automatically deactivated state of LFA" 2 "Reserved" 3 "Reserved" ;
VAL_ 2273435649 HDP_ActvSta 0 "Not Active" 1 "Active" 2 "Reserved" 3 "Reserved" ;
VAL_ 2273435649 HDP_SysSta 0 "OFF" 1 "Standby" 2 "DDT" 3 "TD" 4 "MRM" 5 "EM" 6 "Reserved" 15 "Reserved" ;
VAL_ 2273435649 HDP_FailureMode 0 "Normal" 1 "Blockage" 2 "Failure" ;
VAL_ 2273435650 HDP_ObstacleDstVal 0 "0x0x0~0x5DC:Distance" 1500 "0x0x0~0x5DC:Distance" 1501 "0x5DD~0x7FD:Reserved" 2045 "0x5DD~0x7FD:Reserved" 2046 "Default" 2047 "Error" ;
VAL_ 2273435650 HDP_ObstacleLatPosVal 0 "0x0x0~0x1FD:Position Value" 509 "0x0x0~0x1FD:Position Value" 510 "Default" 511 "Error" ;
VAL_ 2273435650 HDP_InfoPUDis 0 "None" 1 "HDP Active" 2 "HDP TD Lv1" 3 "HDP TD Lv2" 4 "HDP MRM" 5 "HDP EM" 6 "HDP Automatic system off (ÀÚµ¿ ÇØÁ¦)" 7 "HDP Driver availability warning (¿îÀüÀÚ »óÅÂ °æ°í)" 8 "HDP Unable to start warning (È°¼ºÈ­ ºÒ°¡)" 9 "HDP guides user to change lane (°æ·Î º¯°æ À¯µµ ¾È³»)" 10 "Reserved" 11 "Reserved" 12 "Reserved" 13 "Reserved" 14 "Reserved" 15 "Reserved" ;
VAL_ 2273435650 HDP_WrngTypPUDis 0 "Reserved" 1 "Reserved" 2 "Reserved" 3 "Reserved" 4 "Reserved" 5 "Reserved" 6 "Reserved" 7 "Reserved" 8 "Reserved" 9 "Reserved" 10 "Reserved" 11 "Reserved" 12 "Reserved" 13 "Reserved" 14 "Reserved" 15 "Reserved" 16 "Reserved" 17 "Reserved" 18 "Reserved" 19 "Reserved" 20 "Reserved" 21 "Reserved" 22 "Reserved" 23 "Reserved" 24 "Reserved" 25 "Reserved" 26 "Reserved" 27 "Reserved" 28 "Reserved" 29 "Reserved" 30 "Reserved" 31 "Reserved" ;
VAL_ 2273435650 HDP_HapticWarnReq 0 "No Warn" 1 "Request Haptic Warn - Level1" 2 "Request Haptic Warn - Level2" 3 "Reserved" ;
VAL_ 2273435650 HDP_ActvStaDis 0 "Not Active" 1 "Active" 2 "Reserved" 3 "Reserved" 4 "Reserved" 5 "Reserved" 6 "Reserved" 7 "Invalid" ;
VAL_ 2273435650 HDP_OpStaDisp 0 "None" 1 "Standby" 2 "Ready" 3 "Active(DDT)" 4 "Active(TD)" 5 "Active(MRM)" 6 "Active(EM)" 7 "Reserved" 8 "Reserved" 9 "Reserved" 10 "Reserved" 11 "Reserved" 12 "Reserved" 13 "Reserved" 14 "Reserved" 15 "Invalid" ;
VAL_ 2273435650 HDP_ObstSta 0 "No in-path obstacle detected" 1 "In-path obstacle detected (uncontrollable)" 2 "In-path obstacle detected (controllable:longitudinal)" 3 "Reserved" 4 "Reserved" 5 "Reserved" 6 "Reserved" 7 "Reserved" ;
VAL_ 2273435650 HDP_SysFlrDisp 0 "No HDP failure pop-up" 1 "Display HDP failure pop-up" 2 "Reserved" 3 "Reserved" ;
VAL_ 2273435650 HDP_InhbtOffDispSta 0 "None" 1 "Inhibit FCA off in HDP" 2 "Inhibit DrivingSafety off in HDP" 3 "Reserved" 4 "Reserved" 5 "Reserved" 6 "Reserved" 7 "Reserved" ;
VAL_ 2273435650 HDP_CtRoadSrfcDistVal 0 "0x0x0~0x5DC:value (*0.1m)" 1500 "0x0x0~0x5DC:value (*0.1m)" 1501 "0x5DD~0x7FD:Reserved" 2045 "0x5DD~0x7FD:Reserved" 2046 "Default (Not Display)" 2047 "Invalid" ;
VAL_ 2273435650 ADAS_DRV_UpDateInfo 0 "old" 1 "new" ;
VAL_ 2244046849 PCA_RrEquipSta 0 "Default" 1 "Off" 2 "Warning" 3 "Assist" 4 "Reserved" 5 "Reserved" 6 "Reserved" 7 "Invalid" ;
VAL_ 2244046849 PCA_SysFlrSta 0 "Off (No Display)" 1 "Reserved" 2 "Camera Blockage" 3 "Ultrasonic sensor Blockage" 4 "PCA Failure" 5 "Reserved" 6 "Reserved" 7 "Error Indicator" ;
VAL_ 2244046849 PCA_RrWrngLvlSta 0 "Normal" 1 "Ready" 2 "Warning" 3 "Assist" 4 "Assist Ended" 5 "Brake Hold" 6 "Reserved" 7 "Invalid" ;
VAL_ 2244046849 PCA_ModDis 0 "No Warning" 1 "PCA-R Off" 2 "PCA-R On" 3 "PCA-R Off, PCA-F/S Off" 4 "PCA-R On, PCA-F/S Off" 5 "PCA-R On, PCA-F/S On" 6 "Reserved" 7 "Invalid" ;
VAL_ 2244046849 PCA_WrngSndCtSta 0 "Normal" 1 "Warning" 2 "Reserved" 3 "Invalid" ;
VAL_ 2244046849 PCA_WrngSndLtSta 0 "Normal" 1 "Warning" 2 "Reserved" 3 "Invalid" ;
VAL_ 2244046849 PCA_WrngSndRtSta 0 "Normal" 1 "Warning" 2 "Reserved" 3 "Invalid" ;
VAL_ 2244046849 PCA_HptReq 0 "Haptic Off" 1 "Haptic On" 2 "Reserved" 3 "Invalid" ;
VAL_ 2244046849 PCA_BrkReq 0 "PCA Brake off" 1 "PCA Brake on" 2 "PCA Brake on (hold)" 3 "Error indicator" ;
VAL_ 2244046849 PCA_EpbReq 0 "Apply EPB" 1 "Stand by" 2 "Reserved" 3 "Invalid" ;
VAL_ 2244046849 PCA_DgrSta 0 "Default" 1 "Late" 2 "Normal" 3 "Reserved" 4 "Reserved" 5 "Reserved" 6 "Reserved" 7 "Invalid" ;
VAL_ 2244046849 ADAS_PRK_PDW_SysFlrSta 0 "No Display" 1 "Unable by Ultrasonic" 2 "PDW Failure" 3 "Error Indicator" ;
VAL_ 2244046850 ADAS_PRK_PDW_SwIndOnReq 0 "Indicator Off" 1 "Indicator On" 2 "Not Used" 3 "Error Indicator" ;
VAL_ 2244046850 PCA_RrEquipChkSta 0 "Default" 1 "Off" 2 "On" 3 "Invalid" ;
VAL_ 2244046850 PCA_FrWrngLvlSta 0 "Normal" 1 "Ready" 2 "Warning" 3 "Assist" 4 "Assist Ended" 5 "Reserved" 6 "Reserved" 7 "Invalid" ;
VAL_ 2244046850 PCA_LtWrngLvlSta 0 "Normal" 1 "Ready" 2 "Warning" 3 "Assist" 4 "Assist Ended" 5 "Reserved" 6 "Reserved" 7 "Invalid" ;
VAL_ 2244046850 ADAS_PRK_PDW_OptTyp 0 "None" 1 "PDW-R" 2 "PDW-FR" 3 "PDW-FSR" 4 "PDW-R (w/ 1st Corner Warning)" 5 "PDW-FR (w/ 1st Corner Warning)" 6 "Not Used" 7 "Error Indicator" ;
VAL_ 2244046850 PCA_RtWrngLvlSta 0 "Normal" 1 "Ready" 2 "Warning" 3 "Assist" 4 "Assist Ended" 5 "Reserved" 6 "Reserved" 7 "Invalid" ;
VAL_ 2244046850 PCA_RrFlrDis 0 "Normal" 1 "Unvailable by PCA-R" 2 "Reserved" 3 "Invalid" ;
VAL_ 2244046850 PCA_FrFlrDis 0 "Normal" 1 "Unvailable by PCA-F" 2 "Reserved" 3 "Invalid" ;
VAL_ 2244046850 PCA_LtFlrDis 0 "Normal" 1 "Unvailable by PCA-S" 2 "Reserved" 3 "Invalid" ;
VAL_ 2244046850 PCA_RtFlrDis 0 "Normal" 1 "Unvailable by PCA-S" 2 "Reserved" 3 "Invalid" ;
VAL_ 2244046850 PCA_FrBndryLn 0 "Off (No Display)" 1 "Ready" 2 "Assist" 3 "Error Indicator" ;
VAL_ 2244046850 PCA_RrBndryLn 0 "Off (No Display)" 1 "Ready" 2 "Assist" 3 "Error Indicator" ;
VAL_ 2244046850 PCA_LtBndryLn 0 "Off (No Display)" 1 "Ready" 2 "Assist" 3 "Error Indicator" ;
VAL_ 2244046850 PCA_RtBndryLn 0 "Off (No Display)" 1 "Ready" 2 "Assist" 3 "Error Indicator" ;
VAL_ 2244046850 PCA_WrngPhrs 0 "Off (No Display)" 1 "Warning" 2 "Assist" 3 "Assist Ended" 4 "Brake Hold" 5 "Reserved" 6 "Reserved" 7 "Error Indicator" ;
VAL_ 2244046850 ADAS_PRK_PDW_AutoOn_USM 0 "Default" 1 "Function Off" 2 "Function On" 3 "Invalid" ;
VAL_ 2244046850 PCA_FrSdEquipChkSta 0 "Default" 1 "Off" 2 "On" 3 "Invalid" ;
VAL_ 1030 APSM_SWVerMajor1 0 "0x0x0~0x7F:ASCII Code Value (HEX)" 127 "0x0x0~0x7F:ASCII Code Value (HEX)" ;
VAL_ 1030 APSM_SWVerMinor1 0 "0x0x0~0x7F:ASCII Code Value (HEX)" 127 "0x0x0~0x7F:ASCII Code Value (HEX)" ;
VAL_ 1030 APSM_SWVerMinor2 0 "0x0x0~0x7F:ASCII Code Value (HEX)" 127 "0x0x0~0x7F:ASCII Code Value (HEX)" ;
VAL_ 1031 APSM_AstStEsyAcsUSMSta 0 "Default Value" 1 "Off (Disable)" 2 "50mmOn (Enable)" 3 "75mmOn (Enable)" 4 "Reserved" 5 "Reserved" 6 "Reserved" 7 "Invalid" ;
VAL_ 1031 APSM_WalkInEnable 0 "Disable" 1 "Enable" 2 "Not Used" 3 "Error" ;
VAL_ 1031 APSM_LimSetSta 0 "Default" 1 "Initialized" 2 "Not Initialized" 3 "Reserved" ;
VAL_ 1031 APSM_FootRest_Opt 0 "Default" 1 "Off" 2 "On(FootRest OPT)" 3 "Ivalid" ;
VAL_ 1031 APSM_RSE_Opt 0 "Default" 1 "Off" 2 "On(RSE OPT)" 3 "Ivalid" ;
VAL_ 527 ATS_DrvStRseFwdBtn 0 "Default" 1 "Off" 2 "On" 3 "Reserved" ;
VAL_ 527 ATS_DrvStRseBwdBtn 0 "Default" 1 "Off" 2 "On" 3 "Reserved" ;
VAL_ 527 ATS_RRRestModBtn 0 "Default" 1 "Off" 2 "On" 3 "Reserved" ;
VAL_ 527 ATS_RRResetModBtn 0 "Default" 1 "Off" 2 "On" 3 "Reserved" ;
VAL_ 527 ATS_RRAvWtcModBtn 0 "Default" 1 "Off" 2 "On" 3 "Reserved" ;
VAL_ 527 ATS_RRReadingModBtn 0 "Default" 1 "Off" 2 "On" 3 "Reserved" ;
VAL_ 527 ATS_RLRestModBtn 0 "Default" 1 "Off" 2 "On" 3 "Reserved" ;
VAL_ 527 ATS_RLResetModBtn 0 "Default" 1 "Off" 2 "On" 3 "Reserved" ;
VAL_ 543 ATS_AstStSldFwdBtn 0 "Default" 1 "Off" 2 "On" 3 "Reserved" ;
VAL_ 543 ATS_AstStSldBwdBtn 0 "Default" 1 "Off" 2 "On" 3 "Reserved" ;
VAL_ 543 ATS_AstStRclFwdBtn 0 "Default" 1 "Off" 2 "On" 3 "Reserved" ;
VAL_ 543 ATS_AstStRclBwdBtn 0 "Default" 1 "Off" 2 "On" 3 "Reserved" ;
VAL_ 543 ATS_AstStHgtUpBtn 0 "Default" 1 "Off" 2 "On" 3 "Reserved" ;
VAL_ 543 ATS_AstStHgtDnBtn 0 "Default" 1 "Off" 2 "On" 3 "Reserved" ;
VAL_ 543 ATS_AstStHRestUpBtn 0 "Default" 1 "Off" 2 "On" 3 "Reserved" ;
VAL_ 543 ATS_AstStHRestDnBtn 0 "Default" 1 "Off" 2 "On" 3 "Reserved" ;
VAL_ 543 ATS_AstStHRestFwdBtn 0 "Default" 1 "Off" 2 "On" 3 "Reserved" ;
VAL_ 543 ATS_AstStHRestBwdBtn 0 "Default" 1 "Off" 2 "On" 3 "Reserved" ;
VAL_ 543 ATS_AstStHRestFldBtn 0 "Default" 1 "Off" 2 "On" 3 "Reserved" ;
VAL_ 543 ATS_AstStHRestUnFldBtn 0 "Default" 1 "Off" 2 "On" 3 "Reserved" ;
VAL_ 543 ATS_AstStRseFwdBtn 0 "Default" 1 "Off" 2 "On" 3 "Reserved" ;
VAL_ 543 ATS_AstStRseBwdBtn 0 "Default" 1 "Off" 2 "On" 3 "Reserved" ;
VAL_ 543 ATS_AstStFRestFldBtn 0 "Default" 1 "Off" 2 "On" 3 "Reserved" ;
VAL_ 543 ATS_AstStFRestUnFldBtn 0 "Default" 1 "Off" 2 "On" 3 "Reserved" ;
VAL_ 543 ATS_AstTltUpBtn 0 "Default" 1 "Off" 2 "On" 3 "Reserved" ;
VAL_ 543 ATS_AstTltDnBtn 0 "Default" 1 "Off" 2 "On" 3 "Reserved" ;
VAL_ 623 ATS_ARSOpenCloseStatus 0 "Default" 1 "Open" 2 "Close" 3 "Invalid" ;
VAL_ 623 ATS_RLLumbarDefBtn 0 "Default" 1 "Off" 2 "On" 3 "Reserved" ;
VAL_ 623 ATS_RLLumbarLowBtn 0 "Default" 1 "Off" 2 "On" 3 "Reserved" ;
VAL_ 623 ATS_RLLumbarMidBtn 0 "Default" 1 "Off" 2 "On" 3 "Reserved" ;
VAL_ 623 ATS_RLLumbarUpBtn 0 "Default" 1 "Off" 2 "On" 3 "Reserved" ;
VAL_ 623 ATS_RLBolsterDefBtn 0 "Default" 1 "Off" 2 "On" 3 "Reserved" ;
VAL_ 623 ATS_RLBolsterInfSw 0 "Default" 1 "Off" 2 "On" 3 "Reserved" ;
VAL_ 623 ATS_RRLumbarDefBtn 0 "Default" 1 "Off" 2 "On" 3 "Reserved" ;
VAL_ 623 ATS_RRLumbarLowBtn 0 "Default" 1 "Off" 2 "On" 3 "Reserved" ;
VAL_ 623 ATS_RRLumbarMidBtn 0 "Default" 1 "Off" 2 "On" 3 "Reserved" ;
VAL_ 623 ATS_RRLumbarUpBtn 0 "Default" 1 "Off" 2 "On" 3 "Reserved" ;
VAL_ 623 ATS_RRBolsterDefBtn 0 "Default" 1 "Off" 2 "On" 3 "Reserved" ;
VAL_ 623 ATS_RRBolsterInfSw 0 "Default" 1 "Off" 2 "On" 3 "Reserved" ;
VAL_ 1141 Ast_SHVU_SeatOptSta 0 "Init" 1 "Heater only 2step" 2 "Heater only 3step" 3 "Vent only 2step" 4 "Vent only 3step" 5 "Heater and Vent 2step" 6 "Heater and Vent 3step" 7 "Invalid" ;
VAL_ 1141 Ast_SHVU_HtSwHiIndSta 0 "Off(Initial Value)" 1 "On" 2 "Not Used" 3 "Error Indicator" ;
VAL_ 1141 Ast_SHVU_HtSwMidIndSta 0 "Off(Initial Value)" 1 "On" 2 "Not Used" 3 "Error Indicator" ;
VAL_ 1141 Ast_SHVU_HtSwLowIndSta 0 "Off(Initial Value)" 1 "On" 2 "Not Used" 3 "Error Indicator" ;
VAL_ 1141 Ast_SHVU_VntSwHiIndSta 0 "Off(Initial Value)" 1 "On" 2 "Not Used" 3 "Error Indicator" ;
VAL_ 1141 Ast_SHVU_VntSwMidIndSta 0 "Off(Initial Value)" 1 "On" 2 "Not Used" 3 "Error Indicator" ;
VAL_ 1141 Ast_SHVU_VntSwLowIndSta 0 "Off(Initial Value)" 1 "On" 2 "Not Used" 3 "Error Indicator" ;
VAL_ 1141 Ast_SHVU_HtBlcUSMSta 0 "Default" 1 "Normal" 2 "Back 1" 3 "Back 2" 4 "Back 3" 5 "Cush 1" 6 "Cush 2" 7 "Cush 3" 8 "Reserved" 9 "Reserved" 10 "Reserved" 11 "Reserved" 12 "Reserved" 13 "Reserved" 14 "Reserved" 15 "Invalid" ;
VAL_ 1141 Ast_SHVU_SeatHtOperSta 0 "Init" 1 "Unused" 2 "Heater & Vent OFF" 3 "Vent Low" 4 "Vent Mid" 5 "Vent High" 6 "Heater Low" 7 "Heater Mid" 8 "Heater High" 9 "Unused" 10 "Unused" 11 "Unused" 12 "Unused" 13 "Unused" 14 "Unused" 15 "Invalid" ;
VAL_ 1141 Ast_SHVU_HtSwHiIndSta_RHD 0 "Off(Initial Value)" 1 "On" 2 "Not Used" 3 "Error Indicator" ;
VAL_ 1141 Ast_SHVU_HtSwMidIndSta_RHD 0 "Off(Initial Value)" 1 "On" 2 "Not Used" 3 "Error Indicator" ;
VAL_ 1141 Ast_SHVU_HtSwLowIndSta_RHD 0 "Off(Initial Value)" 1 "On" 2 "Not Used" 3 "Error Indicator" ;
VAL_ 1141 Ast_SHVU_VntSwHiIndSta_RHD 0 "Off(Initial Value)" 1 "On" 2 "Not Used" 3 "Error Indicator" ;
VAL_ 1141 Ast_SHVU_VntSwMidIndSta_RHD 0 "Off(Initial Value)" 1 "On" 2 "Not Used" 3 "Error Indicator" ;
VAL_ 1141 Ast_SHVU_VntSwLowIndSta_RHD 0 "Off(Initial Value)" 1 "On" 2 "Not Used" 3 "Error Indicator" ;
VAL_ 1050 Lamp_HiPrioHzrdReq 0 "Off" 1 "High On" 2 "High Inactive" 3 "Reserved" 4 "Reserved" 5 "Reseved" 6 "Not Used" 7 "Error Indicator" ;
VAL_ 1050 Lamp_LoPrioHzrdReq 0 "Off" 1 "Low On" 2 "Low Inactive" 3 "Reserved" 4 "Reserved" 5 "Reseved" 6 "Not Used" 7 "Error Indicator" ;
VAL_ 1050 Lamp_IntTailLmpOnReq 0 "Off" 1 "On" 2 "Not Used" 3 "Error Indicator" ;
VAL_ 1050 Lamp_ExtrnlTailLmpOnReq 0 "Off" 1 "On" 2 "Not Used" 3 "Error Indicator" ;
VAL_ 1050 Lamp_HdLmpLoOnReq 0 "Off" 1 "On" 2 "Not Used" 3 "Error Indicator" ;
VAL_ 1050 Lamp_HdLmpHiOnReq 0 "Off" 1 "On" 2 "Not Used" 3 "Error Indicator" ;
VAL_ 1050 Lamp_AvTailLmpSta 0 "Off" 1 "On" 2 "Not Used" 3 "Error Indicator" ;
VAL_ 1050 Lamp_BckUpLmpCmd 0 "Off" 1 "On" 2 "Not Used" 3 "Error Indicator" ;
VAL_ 1050 Lamp_DrlOnReq 0 "Off" 1 "On" 2 "Not Used" 3 "Error Indicator" ;
VAL_ 1052 Lamp_AutoLtSnsrNightSta 0 "Off" 1 "Night" 2 "Not Used" 3 "Error Indicator" ;
VAL_ 1052 Lamp_VendorInfo 0 "Not Used" 1 "TRW(BCS)" 2 "HELLA" 3 "Not Used" 4 "Not Used" 5 "Not Used" 6 "Not Used" 7 "Error Indicator" ;
VAL_ 1052 Lamp_AutoLtSnsrHorVal 0 "0x0x0~0x3FF:Light Sensor Value" 1023 "0x0x0~0x3FF:Light Sensor Value" ;
VAL_ 1052 IBU_HDPSpprtSWVer 0 "Not Support (Init)" 1 "SW Version" 2 "SW Version" 3 "SW Version" 4 "SW Version" 5 "SW Version" 6 "SW Version" 7 "SW Version" 8 "SW Version" 9 "SW Version" 10 "SW Version" 11 "SW Version" 12 "SW Version" 13 "SW Version" 14 "SW Version" 15 "SW Version" 16 "SW Version" 17 "SW Version" 18 "SW Version" 19 "SW Version" 20 "SW Version" 21 "SW Version" 22 "SW Version" 23 "SW Version" 24 "SW Version" 25 "SW Version" 26 "SW Version" 27 "SW Version" 28 "SW Version" 29 "SW Version" 30 "SW Version" 31 "SW Version" 32 "SW Version" 33 "SW Version" 34 "SW Version" 35 "SW Version" 36 "SW Version" 37 "SW Version" 38 "SW Version" 39 "SW Version" 40 "SW Version" 41 "SW Version" 42 "SW Version" 43 "SW Version" 44 "SW Version" 45 "SW Version" 46 "SW Version" 47 "SW Version" 48 "SW Version" 49 "SW Version" 50 "SW Version" 51 "SW Version" 52 "SW Version" 53 "SW Version" 54 "SW Version" 55 "SW Version" 56 "SW Version" 57 "SW Version" 58 "SW Version" 59 "SW Version" 60 "SW Version" 61 "SW Version" 62 "SW Version" 63 "Error Indicator" ;
VAL_ 1052 Wiper_RainAmount 0 "0x0x0~0x96:PH=0.5*HEX%" 150 "0x0x0~0x96:PH=0.5*HEX%" 151 "0x97~0xFE:Reserved" 254 "0x97~0xFE:Reserved" 255 "Invalid" ;
VAL_ 1124 Window_DrvrSdWdwActSta 0 "No Action" 1 "Manual Down" 2 "Manual Up" 3 "RLY Stuck/FET Error" 4 "Motor Stop Error" 5 "Auto Down" 6 "Auto Up" 7 "Reverse" 8 "Reserved" 9 "Reserved" 10 "Reserved" 11 "Reserved" 12 "Reserved" 13 "Reserved" 14 "Reserved" 15 "Invalid" ;
VAL_ 1124 Window_AsstSdWdwActSta 0 "No Action" 1 "Manual Down" 2 "Manual Up" 3 "RLY Stuck/FET Error" 4 "Motor Stop Error" 5 "Auto Down" 6 "Auto Up" 7 "Reverse" 8 "Reserved" 9 "Reserved" 10 "Reserved" 11 "Reserved" 12 "Reserved" 13 "Reserved" 14 "Reserved" 15 "Invalid" ;
VAL_ 1124 Window_RrLftWdwActSta 0 "No Action" 1 "Manual Down" 2 "Manual Up" 3 "RLY Stuck/FET Error" 4 "Motor Stop Error" 5 "Auto Down" 6 "Auto Up" 7 "Reverse" 8 "Reserved" 9 "Reserved" 10 "Reserved" 11 "Reserved" 12 "Reserved" 13 "Reserved" 14 "Reserved" 15 "Invalid" ;
VAL_ 1124 Window_RrRtWdwActSta 0 "No Action" 1 "Manual Down" 2 "Manual Up" 3 "RLY Stuck/FET Error" 4 "Motor Stop Error" 5 "Auto Down" 6 "Auto Up" 7 "Reverse" 8 "Reserved" 9 "Reserved" 10 "Reserved" 11 "Reserved" 12 "Reserved" 13 "Reserved" 14 "Reserved" 15 "Invalid" ;
VAL_ 1124 Window_DrvrSdWdwDetailOpnSta 0 "Full Close" 1 "1~30% Open" 2 "31~99% Open" 3 "Full Open" 4 "Reserved" 5 "Reserved" 6 "Reserved" 7 "Invalid" ;
VAL_ 1124 Window_AsstSdWdwDetailOpnSta 0 "Full Close" 1 "1~30% Open" 2 "31~99% Open" 3 "Full Open" 4 "Reserved" 5 "Reserved" 6 "Reserved" 7 "Invalid" ;
VAL_ 1124 Window_DrvrSdWdwErrAntPinch 0 "Calibrated" 1 "De-Calibrated" 2 "Reserved" 3 "Invalid" ;
VAL_ 1124 Window_RrLftWdwDetailOpnSta 0 "Full Close" 1 "1~30% Open" 2 "31~99% Open" 3 "Full Open" 4 "Reserved" 5 "Reserved" 6 "Reserved" 7 "Invalid" ;
VAL_ 1124 Window_RrRtWdwDetailOpnSta 0 "Full Close" 1 "1~30% Open" 2 "31~99% Open" 3 "Full Open" 4 "Reserved" 5 "Reserved" 6 "Reserved" 7 "Invalid" ;
VAL_ 1124 Window_AsstSdWdwErrAntPinch 0 "Calibrated" 1 "De-Calibrated" 2 "Reserved" 3 "Invalid" ;
VAL_ 1124 Window_RrLftWdwErrAntPinch 0 "Calibrated" 1 "De-Calibrated" 2 "Reserved" 3 "Invalid" ;
VAL_ 1124 Window_RrRtWdwErrAntPinch 0 "Calibrated" 1 "De-Calibrated" 2 "Reserved" 3 "Invalid" ;
VAL_ 1124 SunRoof_RrBlindPosSta 0 "BLIND_HALF_OPEN" 1 "BLIND_LESS_THEN_HALF_OPEN" 2 "BLIND_ANTIPINCH_LESS_THAN_HALF_OPEN" 3 "BLIND_FULLY_CLOSE" 4 "BLIND_ANTIPINCH_MORE_THAN_HALF_OPEN" 5 "BLIND_MORE_THAN_HALF_OPEN" 6 "BLIND_FULLY_OPEN" 7 "BLIND_UNINITIALIZED" 8 "Reserved" 9 "Reserved" 10 "Reserved" 11 "Reserved" 12 "Reserved" 13 "Reserved" 14 "Reserved" 15 "invalid" ;
VAL_ 614 EMCU_Crc1Val 0 "0x0x0~0xFF:CRCValue" 255 "0x0x0~0xFF:CRCValue" ;
VAL_ 614 EMCU_AlvCnt1Val 0 "AlvCntValue" 1 "AlvCntValue" 2 "AlvCntValue" 3 "AlvCntValue" 4 "AlvCntValue" 5 "AlvCntValue" 6 "AlvCntValue" 7 "AlvCntValue" 8 "AlvCntValue" 9 "AlvCntValue" 10 "AlvCntValue" 11 "AlvCntValue" 12 "AlvCntValue" 13 "AlvCntValue" 14 "AlvCntValue" 15 "AlvCntValue" ;
VAL_ 614 EMCU_LHActSta 0 "OFF" 1 "ON" 2 "RESERVED" 3 "Error indicator" ;
VAL_ 614 EMCU_RHActSta 0 "OFF" 1 "ON" 2 "RESERVED" 3 "Error indicator" ;
VAL_ 614 EMCU_DeltaSpdVal 0 "0x0x000~0xFFE:real values" 4094 "0x0x000~0xFFE:real values" 4095 "Error indicator" ;
VAL_ 614 EMCU_System_Sta 0 "Normal" 1 "RESERVED" 2 "RESERVED" 3 "Error indicator" ;
VAL_ 2214658049 EMS_Crc2Val 65535 "Signal Invalid (Message with unused CRC. CRC signal is transmitted fixed value)" ;
VAL_ 2214658049 EMS_AlvCnt2Val 255 "Signal Invalid (Message with unused Alive counter. Alive counter signal is transmitted fixed value)" ;
VAL_ 2214658049 ENG_BrkSwSta 0 "Brake switch is not pressed (OFF)" 1 "Brake switch is pressed (ON)" 2 "EMS does not support this function." 3 "Brake switch failure" ;
VAL_ 2214658049 ENG_EngClntTempVal 255 "Error indicator" ;
VAL_ 2214658049 ENG_MafCrctVal 128 "Error indicator" ;
VAL_ 2214658049 ENG_BattDscnctSta 0 "no battery disconnection detected" 1 "battery disconnection detected and failure memory erased" 2 "Not used" 3 "Error indicator" ;
VAL_ 2214658049 OBD_MilConfgVal 0 "no MIL, Failure Memory Management OBD-I" 1 "MIL Treatment OBD-I, Failure Memory Management OBD-I" 2 "MIL Treatment OBD-II, Exception" 3 "MIL Treatment OBD-II, Failure Memory Management OBD-II" 4 "MIL Treatment E-OBD, Failure Memory Management E-OBD" 5 "MIL Treatment K-OBD, Failure Memory Management K-OBD" ;
VAL_ 2214658049 ENG_EngSta 0 "Engine Stop" 1 "Cranking" 2 "Stalled" 3 "Running" 4 "Reserved" 5 "Reserved" 6 "Reserved" 7 "Fault" ;
VAL_ 2214658050 ENG_Ack4EngStpSta 0 "No acknowledgement" 1 "Acknowledgement engine stopped" 2 "Not used" 3 "Error indicator" ;
VAL_ 2214658050 ENG_AccDrvAlertDisp 0 "Default" 1 "Auto cruise Disengaged" 2 "No Auto cruise Engaged" 3 "Error indicator" ;
VAL_ 2214658050 DSL_GlowCtrlReq 0 "Glow plug off request" 1 "Glow plug on request" 2 "System Error" 3 "Reserved" ;
VAL_ 2214658050 ENG_GlowLmpSta 0 "Lamp Off" 1 "Lamp On" 2 "Not used" 3 "Error indicator" ;
VAL_ 2214658050 ENG_ThrPosVal 32 "Idle (port value is learnt)" 245 "Throttle perpendicular" 255 "Throttle defective" ;
VAL_ 2214658050 ENG_OverDrvOffReq 0 "Normal operation" 1 "Over drive off request to TCU by the cruise control function" 2 "Not used" 3 "Error indicator" ;
VAL_ 2214658050 ENG_AccelPdlVal 0 "Accelerator Pedal not activated" 1022 "Accelerator Pedal fully activated" 1023 "Accelerator Pedal is defective (fail state) or Non-ETC system (APS is not installed), Error indicator" ;
VAL_ 2214658050 ENG_AccActSta 0 "Auto cruise control is not active" 1 "Auto cruise control is active" 2 "Not used" 3 "Error indicator" ;
VAL_ 2214658050 ACC_CrsMainSwLmpSta 0 "Cruise MAIN switch indication lamp turn OFF" 1 "Cruise MAIN switch indication lamp turn ON" 2 "Not used" 3 "Error indicator" ;
VAL_ 2214658050 ACC_CrsSetSwLmpSta 0 "Cruise SET switch indication lamp turn OFF" 1 "Cruise SET switch indication lamp turn ON" 2 "Not used" 3 "Error indicator" ;
VAL_ 2214658050 ENG_LV_FUP_ENA_THD 0 "The pressure is too low to start engine" 1 "The pressure is enough high to start engine" ;
VAL_ 2214658050 ENG_SoakTimeErrSta 0 "No Failure detected" 1 "Failure detected" 2 "Not used" 3 "Error indicator" ;
VAL_ 2214658050 ENG_CltchOpSta 0 "Clutch is not operating" 1 "Clutch is operating" 2 "Not used" 3 "Error indicator" ;
VAL_ 2214658050 EMS_BrkReq_Slope 0 "No Request" 1 "Brake Request" ;
VAL_ 2214658051 ENG_AppAccelPdlSta 0 "Accelerator pedal not pressed" 1 "Accelerator pedal pressed" 2 "Reserved" 3 "Accelerator pedal position sensor failure" ;
VAL_ 2214658051 ENG_BrkCtrlReq 0 "Brake control request is not active" 1 "Brake control request is active" 2 "Not used" 3 "Error indicator" ;
VAL_ 2214658051 ACC_DnShftCtrlReq 0 "Downshift control request is not active" 1 "Downshift request to 1st gear" 2 "Downshift request to 2nd gear" 3 "Downshift request to 3rd gear" 4 "Downshift request to 4th gear" 5 "Downshift request to 5th gear" 6 "Downshift request to 6th gear" 7 "Downshift request to 7th gear" 8 "Downshift request to 8th gear" 9 "Reserved" 10 "Reserved" 11 "Reserved" 12 "Reserved" 13 "Reserved" 14 "Reserved" 15 "Error indicator" ;
VAL_ 2214658052 ENG_DclBrkCntrlReq 4095 "Error indicator" ;
VAL_ 2214658052 ENG_BstPrsrVal 4095 "Error indicator" ;
VAL_ 2214658052 ENG_EngOilTempVal 255 "Error indicator" ;
VAL_ 2214658052 ENG_DpfWrngSta 0 "DPF Normal State" 1 "DPF Warning State Level 1" 2 "DPF Warning State Level 2" 3 "Reserved" ;
VAL_ 2214658052 ENG_BattWrngLmpSta 0 "Battery Warning Lamp OFF" 1 "Battery Warning Lamp ON" 2 "Not used" 3 "Error indicator" ;
VAL_ 2214658052 ENG_OilPrsrWrngLmpSta 0 "Oil Pressure Warning Lamp OFF" 1 "Oil Pressure Warning Lamp ON" 2 "Not used" 3 "Error indicator" ;
VAL_ 2214658052 ENG_IsgInhbtLmpSta 0 "ISG Inhibit Lamp OFF" 1 "ISG Inhibit Lamp ON" 2 "Not used" 3 "Error indicator" ;
VAL_ 1048 DriveTypeOption 0 "Left Handle Drive Type" 1 "Right Handle Drive Type" 3 "Error Indicator" ;
VAL_ 1048 Warn_RrLftSBRMATSwSta 0 "Off (UnSeated)" 1 "On (Seated)" 3 "Error Indicator" ;
VAL_ 1048 Warn_RrRhtSBRMATSwSta 0 "Off (UnSeated)" 1 "On (Seated)" 3 "Error Indicator" ;
VAL_ 1048 Lamp_FootLampOnReq 0 "Off" 1 "On" 2 "Dim Out" 3 "Error Indicator" ;
VAL_ 1048 Lamp_MoodLampOnReq 0 "0%" 1 "FadeIn" 2 "MoodBrightPercent" 3 "FadeOut" 4 "100%" 5 "RESERVED" 6 "RESERVED" 7 "RESERVED" ;
VAL_ 1048 ICU_PowerAutoCutModSta 0 "Factory Mode (default)" 1 "Dealer Mode" 2 "Customer Mode" 3 "Error Indicator" ;
VAL_ 1048 ICU_SoCBattStaMsgReq 0 "Default" 1 "Alert" 2 "Warning" 3 "Invalid" ;
VAL_ 1048 Brake_SwSta_ICU 0 "Off" 1 "On" 2 "RESERVED" 3 "RESERVED" ;
VAL_ 1048 C_3rdRCSeatBeltSW 0 "Unbelted" 1 "Belted" ;
VAL_ 1048 C_3rdRRSBRMatSw 0 "Off (UnSeated)" 1 "On (Seated)" ;
VAL_ 1048 C_3rdRLSBRMatSw 0 "Off (UnSeated)" 1 "On (Seated)" ;
VAL_ 1048 C_3rdRRSeatBeltSW 0 "Unbelted" 1 "Belted" ;
VAL_ 1048 C_3rdRLSeatBeltSW 0 "Unbelted" 1 "Belted" ;
VAL_ 1048 HSWS_SysWrngSta_ICU 0 "Normal" 1 "System Fail" 2 "Reserved" 3 "Invalid" ;
VAL_ 1616 MKBD_IllumiState 0 "Not received" 1 "Receive Completed" 2 "Reserved" 3 "Invalid" ;
VAL_ 1616 MKBD_SeatKeySet 0 "Off" 1 "On" 2 "Reserved" 3 "Invalid" ;
VAL_ 1027 Win_ElecChildLkSwOpt 0 "Off" 1 "On" 2 "Not Used" 3 "Error Indicator" ;
VAL_ 1027 Win_PwrWdwSwTyp 0 "Invalid" 1 "All Manual" 2 "Drv Auto Down" 3 "Drv Safety" 4 "Frt Safety" 5 "All Safety" 6 "Not Used" 7 "Error Indicator" ;
VAL_ 1027 Win_DrvIMSSwSta 0 "Off" 1 "1" 2 "2" 3 "3(Smart)" 4 "Set(Passenger Seat)" 5 "Not Used" 6 "Not Used" 7 "Error Indicator" ;
VAL_ 1027 Win_DrvPwrWdwSwSta 0 "Off" 1 "Manual Up" 2 "Manual Down" 3 "Auto Up" 4 "Auto Down" 5 "Stuck" 6 "Not Used" 7 "Error Indicator" ;
VAL_ 1027 Win_AsstPwrWdwSwSta 0 "Off" 1 "Manual Up" 2 "Manual Down" 3 "Auto Up" 4 "Auto Down" 5 "Stuck" 6 "Not Used" 7 "Error Indicator" ;
VAL_ 1027 Win_CtrlDrLkSwSta 0 "Off" 1 "On" 2 "Not Used" 3 "Error Indicator" ;
VAL_ 1027 Win_RrLftPwrWdwSwSta 0 "Off" 1 "Manual Up" 2 "Manual Down" 3 "Auto Up" 4 "Auto Down" 5 "Stuck" 6 "Not Used" 7 "Error Indicator" ;
VAL_ 1027 Win_RrRtPwrWdwSwSta 0 "Off" 1 "Manual Up" 2 "Manual Down" 3 "Auto Up" 4 "Auto Down" 5 "Stuck" 6 "Not Used" 7 "Error Indicator" ;
VAL_ 1027 Win_CtrlDrUnLkSwSta 0 "Off" 1 "On" 2 "Not Used" 3 "Error Indicator" ;
VAL_ 1027 Win_PwrWdwLkSwSta 0 "Off" 1 "On" 2 "Not Used" 3 "Error Indicator" ;
VAL_ 1027 Win_RrCrtSwSta 0 "Off" 1 "On" 2 "Not Used" 3 "Error Indicator" ;
